VERSION ""

NS_ :

BS_:

BU_: SBZA_R_LS SBZA_L_LS VIS2_LS SDM_LS PEPS_LS UPA_LS PTM_LS MSM_LS HFP_LS EOCM_F_LS ECC_LS DCAC_LS CGM_LS BSM_LS BCM_LS AOS_LS

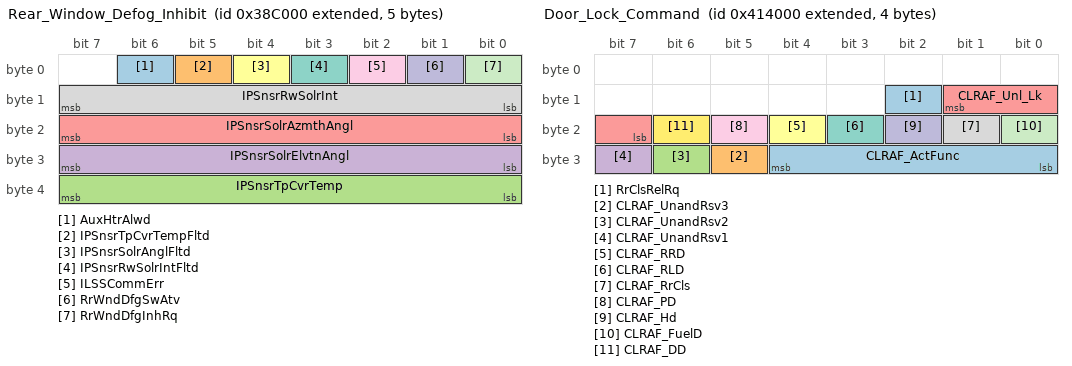
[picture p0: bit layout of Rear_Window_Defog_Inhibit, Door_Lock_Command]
BO_ 2151202816 Rear_Window_Defog_Inhibit: 5 BCM_LS
 SG_ AuxHtrAlwd : 6|1@0+ (1,0) [0|1] ""  ECC_LS,CGM_LS
 SG_ IPSnsrTpCvrTempFltd : 5|1@0+ (1,0) [0|1] ""  ECC_LS,CGM_LS
 SG_ IPSnsrTpCvrTemp : 39|8@0+ (0.5,-40) [-40|87.5] "deg C"  ECC_LS,CGM_LS
 SG_ IPSnsrSolrElvtnAngl : 31|8@0+ (1,0) [0|255] "deg"  ECC_LS,CGM_LS
 SG_ IPSnsrSolrAzmthAngl : 23|8@0+ (2,-180) [-180|330] "deg"  ECC_LS,CGM_LS
 SG_ IPSnsrSolrAnglFltd : 4|1@0+ (1,0) [0|1] ""  ECC_LS,CGM_LS
 SG_ IPSnsrRwSolrIntFltd : 3|1@0+ (1,0) [0|1] ""  ECC_LS,CGM_LS
 SG_ IPSnsrRwSolrInt : 15|8@0+ (3,0) [0|765] "W/m2"  ECC_LS,CGM_LS
 SG_ ILSSCommErr : 2|1@0+ (1,0) [0|1] ""  ECC_LS,CGM_LS
 SG_ RrWndDfgSwAtv : 1|1@0+ (1,0) [0|1] ""  ECC_LS,CGM_LS
 SG_ RrWndDfgInhRq : 0|1@0+ (1,0) [0|1] ""  ECC_LS,CGM_LS

BO_ 2151759872 Door_Lock_Command: 4 BCM_LS
 SG_ RrClsRelRq : 10|1@0+ (1,0) [0|1] ""  PTM_LS,PEPS_LS,CGM_LS
 SG_ CLRAF_UnandRsv3 : 29|1@0+ (1,0) [0|1] ""  PTM_LS,MSM_LS,CGM_LS
 SG_ CLRAF_UnandRsv2 : 30|1@0+ (1,0) [0|1] ""  PTM_LS,MSM_LS,CGM_LS
 SG_ CLRAF_UnandRsv1 : 31|1@0+ (1,0) [0|1] ""  PTM_LS,MSM_LS,CGM_LS
 SG_ CLRAF_Unl_Lk : 9|3@0+ (1,0) [0|7] ""  PTM_LS,MSM_LS,CGM_LS
 SG_ CLRAF_RRD : 20|1@0+ (1,0) [0|1] ""  PTM_LS,MSM_LS,CGM_LS
 SG_ CLRAF_RLD : 19|1@0+ (1,0) [0|1] ""  PTM_LS,MSM_LS,CGM_LS
 SG_ CLRAF_RrCls : 17|1@0+ (1,0) [0|1] ""  PTM_LS,MSM_LS,CGM_LS
 SG_ CLRAF_PD : 21|1@0+ (1,0) [0|1] ""  PTM_LS,MSM_LS,CGM_LS
 SG_ CLRAF_Hd : 18|1@0+ (1,0) [0|1] ""  PTM_LS,MSM_LS,CGM_LS
 SG_ CLRAF_FuelD : 16|1@0+ (1,0) [0|1] ""  PTM_LS,MSM_LS,CGM_LS
 SG_ CLRAF_DD : 22|1@0+ (1,0) [0|1] ""  PTM_LS,MSM_LS,CGM_LS
 SG_ CLRAF_ActFunc : 28|5@0+ (1,0) [0|31] ""  PTM_LS,MSM_LS,CGM_LS

BO_ 2149974016 Content_Theft_Sensor_Status: 3 BCM_LS
 SG_ IntrSnsDisbld : 1|1@0+ (1,0) [0|1] ""  CGM_LS
 SG_ AlrmStat : 18|3@0+ (1,0) [0|7] ""  PTM_LS,BSM_LS,CGM_LS
 SG_ AlrmTrggrdBattRcnctd : 11|1@0+ (1,0) [0|1] ""  CGM_LS
 SG_ AlrmTrgDrvDr : 3|1@0+ (1,0) [0|1] ""  CGM_LS
 SG_ AlrmTrgGlsBrkSns : 12|1@0+ (1,0) [0|1] ""  CGM_LS
 SG_ AlrmTrgHd : 21|1@0+ (1,0) [0|1] ""  CGM_LS
 SG_ AlrmTrgdIO : 15|1@0+ (1,0) [0|1] ""  CGM_LS
 SG_ AlrmTrgIntMvmntSns : 10|1@0+ (1,0) [0|1] ""  CGM_LS
 SG_ AlrmTrgNonOffPM : 13|1@0+ (1,0) [0|1] ""  CGM_LS
 SG_ AlrmTrgPsngDr : 4|1@0+ (1,0) [0|1] ""  CGM_LS
 SG_ AlrmTrgRrLftDr : 6|1@0+ (1,0) [0|1] ""  CGM_LS
 SG_ AlrmTrgRrRtDr : 5|1@0+ (1,0) [0|1] ""  CGM_LS
 SG_ AlrmTrgTltSns : 9|1@0+ (1,0) [0|1] ""  CGM_LS
 SG_ AlrmTrgTrnk : 8|1@0+ (1,0) [0|1] ""  CGM_LS
 SG_ SrvAlrmSysIO : 0|1@0+ (1,0) [0|1] ""  CGM_LS
 SG_ AlrmTrigMidClsr : 14|1@0+ (1,0) [0|1] ""  CGM_LS
 SG_ AlrmTrigTonn : 7|1@0+ (1,0) [0|1] ""  CGM_LS

BO_ 2151907328 Steering_Wheel_Control_Switches: 1 BCM_LS
 SG_ StrgWhlUnit1SwStat : 3|4@0+ (1,0) [0|15] ""  CGM_LS
 SG_ StrgWhlUnit2SwStat : 7|4@0+ (1,0) [0|15] ""  CGM_LS

BO_ 1345 UUDT_Resp_From_BCM_LS: 8 BCM_LS
 SG_ DgnInf_LS541 : 7|64@0+ (1,0) [0|1.84467440737096E+019] ""  CGM_LS

BO_ 1601 USDT_Resp_From_BCM_LS: 8 BCM_LS
 SG_ DgnInf : 7|64@0+ (1,0) [0|1.84467440737096E+019] ""  CGM_LS

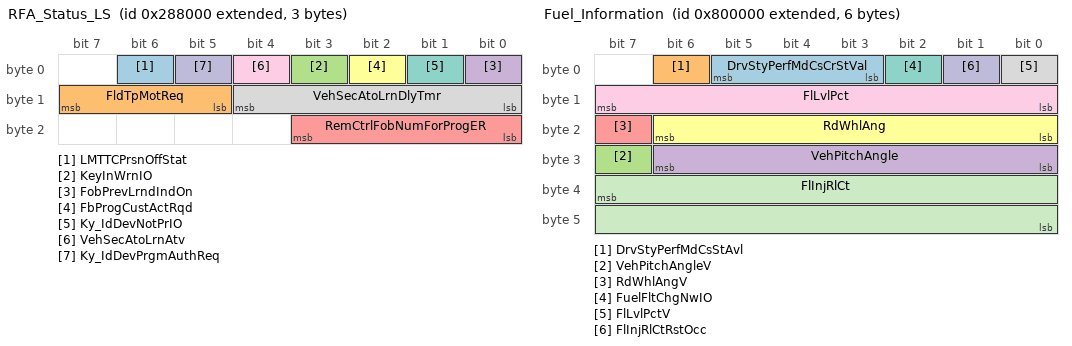
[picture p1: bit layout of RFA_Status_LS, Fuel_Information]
BO_ 2150137856 RFA_Status_LS: 3 BCM_LS
 SG_ LMTTCPrsnOffStat : 6|1@0+ (1,0) [0|1] ""  PEPS_LS,CGM_LS
 SG_ FldTpMotReq : 15|3@0+ (1,0) [0|7] ""  PEPS_LS,CGM_LS
 SG_ KeyInWrnIO : 3|1@0+ (1,0) [0|1] ""  CGM_LS
 SG_ FobPrevLrndIndOn : 0|1@0+ (1,0) [0|1] ""  CGM_LS
 SG_ RemCtrlFobNumForProgER : 19|4@0+ (1,0) [0|15] ""  PEPS_LS,CGM_LS
 SG_ FbProgCustActRqd : 2|1@0+ (1,0) [0|1] ""  CGM_LS
 SG_ Ky_IdDevNotPrIO : 1|1@0+ (1,0) [0|1] ""  CGM_LS
 SG_ VehSecAtoLrnDlyTmr : 12|5@0+ (1,0) [0|31] "min"  CGM_LS
 SG_ VehSecAtoLrnAtv : 4|1@0+ (1,0) [0|1] ""  CGM_LS
 SG_ Ky_IdDevPrgmAuthReq : 5|1@0+ (1,0) [0|1] ""  PEPS_LS,CGM_LS

BO_ 2155872256 Fuel_Information: 6 BCM_LS
 SG_ DrvStyPerfMdCsCrStVal : 5|3@0+ (1,0) [0|7] ""  CGM_LS
 SG_ DrvStyPerfMdCsStAvl : 6|1@0+ (1,0) [0|1] ""  CGM_LS
 SG_ VehPitchAngleV : 31|1@0+ (1,0) [0|1] ""  CGM_LS
 SG_ VehPitchAngle : 30|7@0+ (0.703125,-45) [-45|44.296875] "deg"  CGM_LS
 SG_ RdWhlAngV : 23|1@0+ (1,0) [0|1] ""  CGM_LS
 SG_ RdWhlAng : 22|7@0+ (0.703125,-45) [-45|44.296875] "deg"  CGM_LS
 SG_ FuelFltChgNwIO : 2|1@0+ (1,0) [0|1] ""  CGM_LS
 SG_ FlLvlPctV : 0|1@0+ (1,0) [0|1] ""  CGM_LS
 SG_ FlLvlPct : 15|8@0+ (0.392157,0) [0|100.000035] "%"  CGM_LS
 SG_ FlInjRlCtRstOcc : 1|1@0+ (1,0) [0|1] ""  CGM_LS
 SG_ FlInjRlCt : 39|16@0+ (3.05176E-005,0) [0|1.999970916] "liters"  CGM_LS

BO_ 2154561536 Vehicle_Odo_LS: 5 BCM_LS
 SG_ VehOdoV : 32|1@0+ (1,0) [0|1] ""  EOCM_F_LS,CGM_LS,BSM_LS
 SG_ VehOdo : 7|32@0+ (0.015625,0) [0|67108863.984375] "km"  EOCM_F_LS,ECC_LS,CGM_LS,BSM_LS

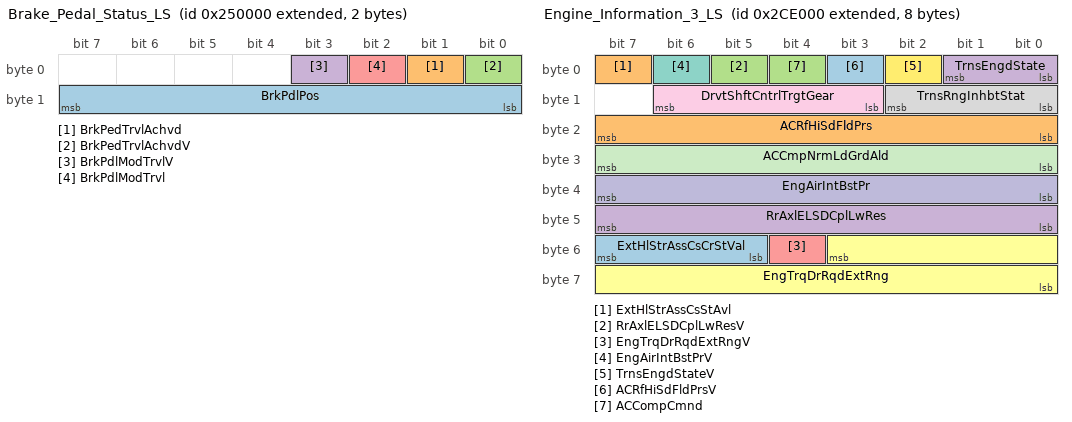
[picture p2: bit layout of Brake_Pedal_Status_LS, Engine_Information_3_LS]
BO_ 2149908480 Brake_Pedal_Status_LS: 2 BCM_LS
 SG_ BrkPdlPos : 15|8@0+ (0.392157,0) [0|100.000035] "% full"  VIS2_LS,CGM_LS
 SG_ BrkPedTrvlAchvd : 1|1@0+ (1,0) [0|1] ""  SDM_LS,VIS2_LS,CGM_LS
 SG_ BrkPedTrvlAchvdV : 0|1@0+ (1,0) [0|1] ""  SDM_LS,VIS2_LS,CGM_LS
 SG_ BrkPdlModTrvlV : 3|1@0+ (1,0) [0|1] ""  VIS2_LS,CGM_LS
 SG_ BrkPdlModTrvl : 2|1@0+ (1,0) [0|1] ""  VIS2_LS,CGM_LS

BO_ 2151268352 Column_Lock_Status: 1 BCM_LS
 SG_ ClmnLckTT : 1|2@0+ (1,0) [0|3] ""  CGM_LS

BO_ 2150424576 Engine_Information_3_LS: 8 BCM_LS
 SG_ ExtHlStrAssCsCrStVal : 55|3@0+ (1,0) [0|7] ""  CGM_LS
 SG_ ExtHlStrAssCsStAvl : 7|1@0+ (1,0) [0|1] ""  CGM_LS
 SG_ RrAxlELSDCplLwResV : 5|1@0+ (1,0) [0|1] ""  CGM_LS
 SG_ RrAxlELSDCplLwRes : 47|8@0+ (10,0) [0|2550] "Nm"  CGM_LS
 SG_ EngTrqDrRqdExtRngV : 52|1@0+ (1,0) [0|1] ""  CGM_LS
 SG_ EngTrqDrRqdExtRng : 51|12@0+ (0.5,-848) [-848|1199.5] "Nm"  CGM_LS
 SG_ EngAirIntBstPrV : 6|1@0+ (1,0) [0|1] ""  CGM_LS
 SG_ TrnsRngInhbtStat : 10|3@0+ (1,0) [0|7] ""  CGM_LS
 SG_ DrvtShftCntrlTrgtGear : 14|4@0+ (1,0) [0|15] ""  CGM_LS
 SG_ EngAirIntBstPr : 39|8@0- (1,0) [-128|127] "kPaG"  CGM_LS
 SG_ ACCmpNrmLdGrdAld : 31|8@0+ (0.1,0) [0|25.5] "dm3/m/s"  ECC_LS,CGM_LS
 SG_ TrnsEngdStateV : 2|1@0+ (1,0) [0|1] ""  SBZA_R_LS,VIS2_LS,SBZA_L_LS,CGM_LS
 SG_ ACRfHiSdFldPrsV : 3|1@0+ (1,0) [0|1] ""  ECC_LS,CGM_LS
 SG_ ACRfHiSdFldPrs : 23|8@0+ (14,0) [0|3570] "kPaG"  ECC_LS,CGM_LS
 SG_ ACCompCmnd : 4|1@0+ (1,0) [0|1] ""  ECC_LS,CGM_LS
 SG_ TrnsEngdState : 1|2@0+ (1,0) [0|3] ""  SBZA_R_LS,VIS2_LS,SBZA_L_LS,CGM_LS

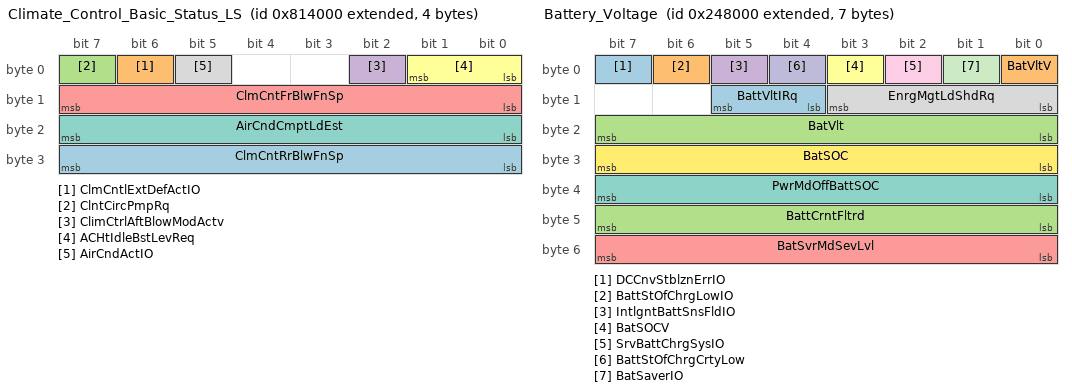
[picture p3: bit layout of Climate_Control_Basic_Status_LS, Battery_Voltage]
BO_ 2155954176 Climate_Control_Basic_Status_LS: 4 BCM_LS
 SG_ ClmCntRrBlwFnSp : 31|8@0+ (0.392157,0) [0|100.000035] "%"  CGM_LS,PTM_LS
 SG_ ClmCntlExtDefActIO : 6|1@0+ (1,0) [0|1] ""  CGM_LS
 SG_ ClntCircPmpRq : 7|1@0+ (1,0) [0|1] ""  CGM_LS,BCM_LS
 SG_ ClimCtrlAftBlowModActv : 2|1@0+ (1,0) [0|1] ""  CGM_LS,BCM_LS
 SG_ ClmCntFrBlwFnSp : 15|8@0+ (0.392157,0) [0|100.000035] "%"  CGM_LS,BSM_LS,BCM_LS,PTM_LS
 SG_ ACHtIdleBstLevReq : 1|2@0+ (1,0) [0|3] ""  CGM_LS,BCM_LS
 SG_ AirCndCmptLdEst : 23|8@0+ (0.392157,0) [0|100.000035] "%"  CGM_LS
 SG_ AirCndActIO : 5|1@0+ (1,0) [0|1] ""  CGM_LS

BO_ 2149875712 Battery_Voltage: 7 BCM_LS
 SG_ DCCnvStblznErrIO : 7|1@0+ (1,0) [0|1] ""  CGM_LS
 SG_ BattStOfChrgLowIO : 6|1@0+ (1,0) [0|1] ""  CGM_LS
 SG_ BattCrntFltrd : 47|8@0- (0.5,0) [-64|63.5] "A"  ECC_LS,CGM_LS
 SG_ IntlgntBattSnsFldIO : 5|1@0+ (1,0) [0|1] ""  CGM_LS
 SG_ BatSvrMdSevLvl : 55|8@0+ (1,0) [0|255] ""  CGM_LS
 SG_ BatSOCV : 3|1@0+ (1,0) [0|1] ""  DCAC_LS,ECC_LS,CGM_LS
 SG_ PwrMdOffBattSOC : 39|8@0+ (0.392157,0) [0|100.000035] "%"  CGM_LS
 SG_ EnrgMgtLdShdRq : 11|4@0+ (1,0) [0|15] ""  MSM_LS,DCAC_LS,ECC_LS,CGM_LS
 SG_ SrvBattChrgSysIO : 2|1@0+ (1,0) [0|1] ""  CGM_LS
 SG_ BattStOfChrgCrtyLow : 4|1@0+ (1,0) [0|1] ""  ECC_LS,CGM_LS
 SG_ BatSaverIO : 1|1@0+ (1,0) [0|1] ""  CGM_LS
 SG_ BatSOC : 31|8@0+ (0.392157,0) [0|100.000035] "%"  PEPS_LS,DCAC_LS,ECC_LS,CGM_LS
 SG_ BattVltIRq : 13|2@0+ (1,0) [0|3] ""  CGM_LS
 SG_ BatVltV : 0|1@0+ (1,0) [0|1] ""  SBZA_R_LS,MSM_LS,EOCM_F_LS,ECC_LS,CGM_LS,SBZA_L_LS
 SG_ BatVlt : 23|8@0+ (0.1,3) [3|28.5] "volts"  SBZA_R_LS,PEPS_LS,MSM_LS,EOCM_F_LS,ECC_LS,CGM_LS,SBZA_L_LS

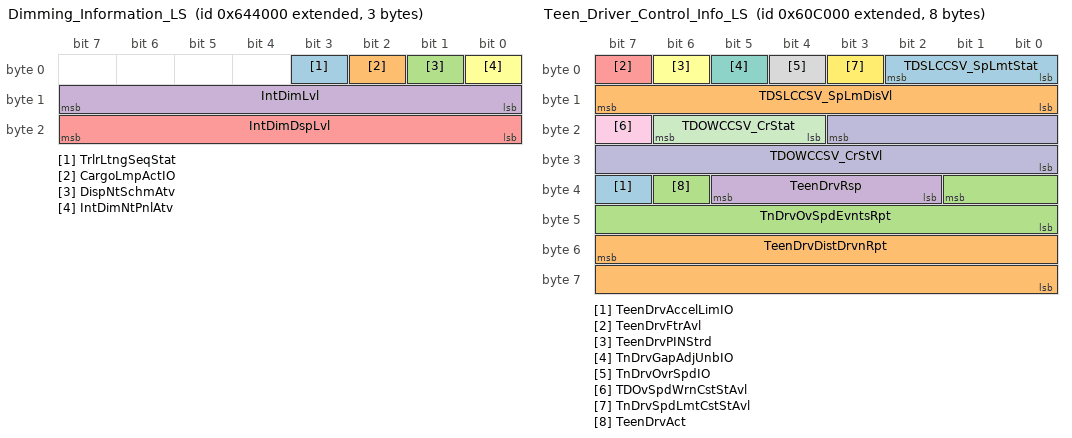
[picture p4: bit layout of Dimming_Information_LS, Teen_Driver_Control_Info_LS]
BO_ 2154053632 Dimming_Information_LS: 3 BCM_LS
 SG_ TrlrLtngSeqStat : 3|1@0+ (1,0) [0|1] ""  CGM_LS
 SG_ CargoLmpActIO : 2|1@0+ (1,0) [0|1] ""  CGM_LS
 SG_ DispNtSchmAtv : 1|1@0+ (1,0) [0|1] ""  SDM_LS,HFP_LS,ECC_LS,CGM_LS
 SG_ IntDimLvl : 15|8@0+ (0.392157,0) [0|100.000035] "%"  MSM_LS,ECC_LS,CGM_LS
 SG_ IntDimDspLvl : 23|8@0+ (0.392157,0) [0|100.000035] "%"  SDM_LS,ECC_LS,CGM_LS
 SG_ IntDimNtPnlAtv : 0|1@0+ (1,0) [0|1] ""  ECC_LS,CGM_LS

BO_ 2033 PCU_Req_to_SDM_LS: 8 BCM_LS
 SG_ PCUInfo : 7|64@0+ (1,0) [0|1.84467440737096E+019] ""  SDM_LS,CGM_LS

BO_ 2151530496 TPM_Display_Commands: 6 BCM_LS
 SG_ HVBTBDCSRR1_DChMHSRq : 45|6@0+ (1,0) [0|63] "min"  CGM_LS
 SG_ HVBTBDCSRR1_DChSnSRq : 47|2@0+ (1,0) [0|3] ""  CGM_LS
 SG_ HVBTBDCSRR1_DChSlSRq : 35|4@0+ (1,0) [0|15] ""  CGM_LS
 SG_ HVBTBDCSRR1_DChDStRq : 39|4@0+ (1,0) [0|15] ""  CGM_LS
 SG_ HVBTBDCSRR1_DChHStRq : 28|5@0+ (1,0) [0|31] "hr"  CGM_LS
 SG_ HVBatTmBsChgMdRqRmt1 : 31|3@0+ (1,0) [0|7] ""  CGM_LS
 SG_ HVChgSyChgLvPfStRmt1 : 18|3@0+ (1,0) [0|7] ""  CGM_LS
 SG_ StTODChrgTmpOvrdRmt1 : 20|2@0+ (1,0) [0|3] ""  CGM_LS
 SG_ PrtyChrgRqRmt1 : 22|2@0+ (1,0) [0|3] ""  CGM_LS
 SG_ OfBrdHVCVhCsChRqRmt1 : 23|1@0+ (1,0) [0|1] ""  CGM_LS
 SG_ TireTrdTmpStat : 6|3@0+ (1,0) [0|7] ""  CGM_LS
 SG_ TrPrsMntrTrLdStat : 3|2@0+ (1,0) [0|3] ""  CGM_LS
 SG_ TrPrsMntrAtLocFld : 1|1@0+ (1,0) [0|1] ""  CGM_LS
 SG_ TireLocatnWarnEn : 15|1@0+ (1,0) [0|1] ""  CGM_LS
 SG_ WintTrRecIndOn : 12|1@0+ (1,0) [0|1] ""  CGM_LS
 SG_ TrPrsMntrFld : 13|1@0+ (1,0) [0|1] ""  CGM_LS
 SG_ TrRrAxlPresStat : 11|2@0+ (1,0) [0|3] ""  CGM_LS
 SG_ TrFrntAxlPresStat : 9|2@0+ (1,0) [0|3] ""  CGM_LS
 SG_ TPMTrLrnMdCmplt : 0|1@0+ (1,0) [0|1] ""  CGM_LS

BO_ 2153824256 Teen_Driver_Control_Info_LS: 8 BCM_LS
 SG_ TeenDrvAccelLimIO : 39|1@0+ (1,0) [0|1] ""  CGM_LS
 SG_ TeenDrvDistDrvnRpt : 55|16@0+ (1,0) [0|65535] "km"  CGM_LS
 SG_ TnDrvOvSpdEvntsRpt : 33|10@0+ (1,0) [0|1023] "counts"  CGM_LS
 SG_ TeenDrvRsp : 37|4@0+ (1,0) [0|15] ""  CGM_LS
 SG_ TeenDrvFtrAvl : 7|1@0+ (1,0) [0|1] ""  CGM_LS
 SG_ TeenDrvPINStrd : 6|1@0+ (1,0) [0|1] ""  CGM_LS
 SG_ TnDrvGapAdjUnbIO : 5|1@0+ (1,0) [0|1] ""  CGM_LS
 SG_ TnDrvOvrSpdIO : 4|1@0+ (1,0) [0|1] ""  CGM_LS
 SG_ TDOvSpdWrnCstStAvl : 23|1@0+ (1,0) [0|1] ""  CGM_LS
 SG_ TDOWCCSV_CrStVl : 19|12@0+ (0.0625,0) [0|255.9375] "km/h"  CGM_LS
 SG_ TDOWCCSV_CrStat : 22|3@0+ (1,0) [0|7] ""  CGM_LS
 SG_ TnDrvSpdLmtCstStAvl : 3|1@0+ (1,0) [0|1] ""  CGM_LS
 SG_ TDSLCCSV_SpLmtStat : 2|3@0+ (1,0) [0|7] ""  CGM_LS
 SG_ TDSLCCSV_SpLmDisVl : 15|8@0+ (2,0) [0|510] "km/h"  CGM_LS
 SG_ TeenDrvAct : 38|1@0+ (1,0) [0|1] ""  SBZA_R_LS,SBZA_L_LS,UPA_LS,VIS2_LS,EOCM_F_LS,CGM_LS

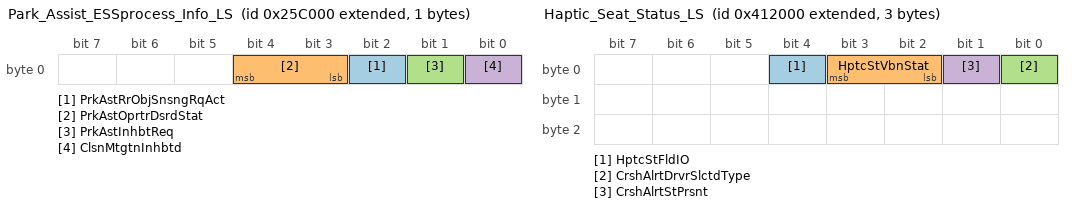
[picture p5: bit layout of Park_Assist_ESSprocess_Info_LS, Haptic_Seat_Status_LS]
BO_ 2149957632 Park_Assist_ESSprocess_Info_LS: 1 EOCM_F_LS
 SG_ PrkAstRrObjSnsngRqAct : 2|1@0+ (1,0) [0|1] ""  UPA_LS,CGM_LS
 SG_ PrkAstOprtrDsrdStat : 4|2@0+ (1,0) [0|3] ""  UPA_LS,CGM_LS
 SG_ PrkAstInhbtReq : 1|1@0+ (1,0) [0|1] ""  UPA_LS,CGM_LS
 SG_ ClsnMtgtnInhbtd : 0|1@0+ (1,0) [0|1] ""  UPA_LS,CGM_LS

BO_ 2151751680 Haptic_Seat_Status_LS: 3 MSM_LS
 SG_ HptcStFldIO : 4|1@0+ (1,0) [0|1] ""  VIS2_LS,CGM_LS
 SG_ HptcStVbnStat : 3|2@0+ (1,0) [0|3] ""  SBZA_R_LS,SBZA_L_LS,UPA_LS,VIS2_LS,EOCM_F_LS,CGM_LS,BCM_LS
 SG_ CrshAlrtDrvrSlctdType : 0|1@0+ (1,0) [0|1] ""  SBZA_R_LS,SBZA_L_LS,UPA_LS,VIS2_LS,EOCM_F_LS,CGM_LS,BCM_LS
 SG_ CrshAlrtStPrsnt : 1|1@0+ (1,0) [0|1] ""  SBZA_R_LS,SBZA_L_LS,UPA_LS,VIS2_LS,EOCM_F_LS,CGM_LS,BCM_LS

BO_ 2149990400 HS_Indications_Fast_LS: 8 BCM_LS
 SG_ ElcTransRngRq : 39|3@0+ (1,0) [0|7] ""  CGM_LS
 SG_ TrnsfrCsRngShfSpdLmt : 47|8@0+ (1,0) [0|255] "km / h"  CGM_LS
 SG_ TrlrBrkngVDA : 2|1@0+ (1,0) [0|1] ""  CGM_LS
 SG_ InstFuelConsmpRate : 51|12@0+ (0.025,0) [0|102.375] "ltrs/hr"  CGM_LS
 SG_ MotStBltUnblIO : 36|1@0+ (1,0) [0|1] ""  CGM_LS
 SG_ MotStBltFldIO : 35|1@0+ (1,0) [0|1] ""  CGM_LS
 SG_ TransNtrlCntrlMdStat : 34|2@0+ (1,0) [0|3] ""  CGM_LS
 SG_ TrlrWiringFltIO : 7|1@0+ (1,0) [0|1] ""  CGM_LS
 SG_ TrlrCnctdIO : 14|1@0+ (1,0) [0|1] ""  EOCM_F_LS,CGM_LS
 SG_ TrlrBrkngGainSetIO : 13|1@0+ (1,0) [0|1] ""  CGM_LS
 SG_ TrlrBrkngGainSet : 31|8@0+ (0.392157,0) [0|100.000035] "%"  CGM_LS
 SG_ TrlrBrkngFrcOtpt : 23|8@0+ (0.392157,0) [0|100.000035] "%"  CGM_LS
 SG_ SrvTrlrBrkngSysIO : 12|1@0+ (1,0) [0|1] ""  CGM_LS
 SG_ ChkTrlrIO : 15|1@0+ (1,0) [0|1] ""  CGM_LS
 SG_ ScndryAxleVDA : 11|1@0+ (1,0) [0|1] ""  CGM_LS
 SG_ TrlrHtchSwAtv_ITBC : 32|1@0+ (1,0) [0|1] ""  CGM_LS
 SG_ AdvHlmpsVDA : 9|1@0+ (1,0) [0|1] ""  CGM_LS
 SG_ ABSIO : 0|1@0+ (1,0) [0|1] ""  SDM_LS,CGM_LS
 SG_ ACCHdwayStngIO : 5|1@0+ (1,0) [0|1] ""  CGM_LS
 SG_ StpOnBrkToRelPBIndOn : 1|1@0+ (1,0) [0|1] ""  CGM_LS
 SG_ SADmpVDA : 10|1@0+ (1,0) [0|1] ""  CGM_LS
 SG_ ACCDrvrSeltdSpdIO : 6|1@0+ (1,0) [0|1] ""  CGM_LS
 SG_ TreInfMonSysRstPrfmd : 4|1@0+ (1,0) [0|1] ""  CGM_LS
 SG_ DrvThrtlOvrdIO : 3|1@0+ (1,0) [0|1] ""  CGM_LS
 SG_ SecAxlOperMod : 55|4@0+ (1,0) [0|15] ""  UPA_LS,CGM_LS

BO_ 2155380736 HS_Indications_SuperSlow_LS: 6 BCM_LS
 SG_ ACCmCltEngd : 41|1@0+ (1,0) [0|1] ""  ECC_LS,CGM_LS
 SG_ StrAsstRdcdLvl3IO : 23|1@0+ (1,0) [0|1] ""  CGM_LS
 SG_ StrAsstRdcdLvl2IO : 16|1@0+ (1,0) [0|1] ""  CGM_LS
 SG_ StrngAsstRdcdIO : 22|1@0+ (1,0) [0|1] ""  CGM_LS
 SG_ PwrPkFnSpd : 39|8@0+ (0.392157,0) [0|100.000035] "%"  PTM_LS,ECC_LS,CGM_LS
 SG_ PwrPckAirInTempFlt : 31|8@0+ (1,-40) [-40|215] "deg C"  ECC_LS,CGM_LS
 SG_ PTExPrtclFltrWrn2IO : 18|1@0+ (1,0) [0|1] ""  CGM_LS
 SG_ EngOilHotIO : 5|1@0+ (1,0) [0|1] ""  CGM_LS
 SG_ RrLevVDA : 3|1@0+ (1,0) [0|1] ""  CGM_LS
 SG_ EngWtrInFlIO : 12|1@0+ (1,0) [0|1] ""  CGM_LS
 SG_ AdvFrntLghtSysIndRq : 21|3@0+ (1,0) [0|7] ""  EOCM_F_LS,CGM_LS
 SG_ PTExPrtclFltrWrnIO : 6|1@0+ (1,0) [0|1] ""  CGM_LS
 SG_ AirCndOffIO : 4|1@0+ (1,0) [0|1] ""  CGM_LS
 SG_ HdLtLvlFlrIO : 2|1@0+ (1,0) [0|1] ""  CGM_LS
 SG_ PwrStrIO : 17|1@0+ (1,0) [0|1] ""  CGM_LS
 SG_ EngHt_StpEngIO : 15|1@0+ (1,0) [0|1] ""  CGM_LS
 SG_ CkFlFilrCapIO : 14|1@0+ (1,0) [0|1] ""  CGM_LS
 SG_ RdcdPwrIO : 13|1@0+ (1,0) [0|1] ""  SDM_LS,CGM_LS
 SG_ EngOilPrsLwIO : 11|1@0+ (1,0) [0|1] ""  CGM_LS
 SG_ EngOilLvlLwIO : 10|1@0+ (1,0) [0|1] ""  CGM_LS
 SG_ EngOilChngIO : 9|1@0+ (1,0) [0|1] ""  CGM_LS
 SG_ EngHotFuelEnrchmntIO : 8|1@0+ (1,0) [0|1] ""  CGM_LS
 SG_ DslGlwPlgIO : 7|1@0+ (1,0) [0|1] ""  CGM_LS
 SG_ SrvLevSysIO : 1|1@0+ (1,0) [0|1] ""  CGM_LS
 SG_ VehOvrLdIndOn : 0|1@0+ (1,0) [0|1] ""  CGM_LS
 SG_ ARSFlrIO : 40|1@0+ (1,0) [0|1] ""  CGM_LS

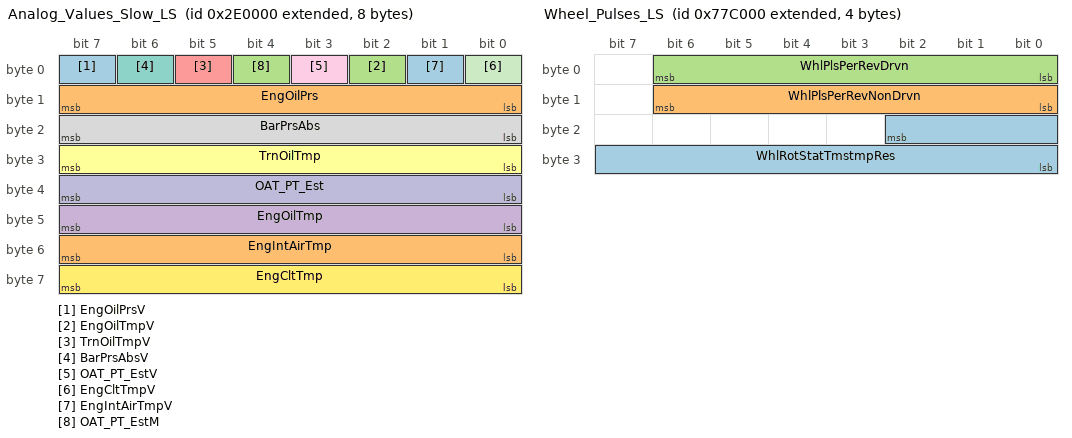
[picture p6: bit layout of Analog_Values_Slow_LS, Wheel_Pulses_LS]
BO_ 2150498304 Analog_Values_Slow_LS: 8 BCM_LS
 SG_ EngOilPrsV : 7|1@0+ (1,0) [0|1] ""  CGM_LS
 SG_ EngOilPrs : 15|8@0+ (4,0) [0|1020] "kPa"  CGM_LS
 SG_ EngOilTmpV : 2|1@0+ (1,0) [0|1] ""  CGM_LS
 SG_ EngOilTmp : 47|8@0+ (1,-40) [-40|215] "deg C"  CGM_LS
 SG_ TrnOilTmpV : 5|1@0+ (1,0) [0|1] ""  ECC_LS,CGM_LS
 SG_ TrnOilTmp : 31|8@0+ (1,-40) [-40|215] "deg C"  ECC_LS,CGM_LS
 SG_ BarPrsAbsV : 6|1@0+ (1,0) [0|1] ""  CGM_LS
 SG_ BarPrsAbs : 23|8@0+ (0.5,0) [0|127.5] "kPa"  CGM_LS
 SG_ OAT_PT_EstV : 3|1@0+ (1,0) [0|1] ""  PTM_LS,ECC_LS,CGM_LS
 SG_ OAT_PT_Est : 39|8@0+ (0.5,-40) [-40|87.5] "deg C"  PTM_LS,ECC_LS,CGM_LS
 SG_ EngCltTmpV : 0|1@0+ (1,0) [0|1] ""  ECC_LS,CGM_LS
 SG_ EngCltTmp : 63|8@0+ (1,-40) [-40|215] "deg C"  ECC_LS,CGM_LS
 SG_ EngIntAirTmpV : 1|1@0+ (1,0) [0|1] ""  ECC_LS,CGM_LS
 SG_ EngIntAirTmp : 55|8@0+ (1,-40) [-40|215] "deg C"  ECC_LS,CGM_LS
 SG_ OAT_PT_EstM : 4|1@0+ (1,0) [0|1] ""  PTM_LS,ECC_LS,CGM_LS

BO_ 2155331584 Wheel_Pulses_LS: 4 BCM_LS
 SG_ WhlRotStatTmstmpRes : 18|11@0+ (0.002,0) [0|4.094] "uSec"  SDM_LS,CGM_LS
 SG_ WhlPlsPerRevNonDrvn : 14|7@0+ (1,0) [0|127] ""  UPA_LS,SDM_LS,CGM_LS
 SG_ WhlPlsPerRevDrvn : 6|7@0+ (1,0) [0|127] ""  UPA_LS,SDM_LS,CGM_LS

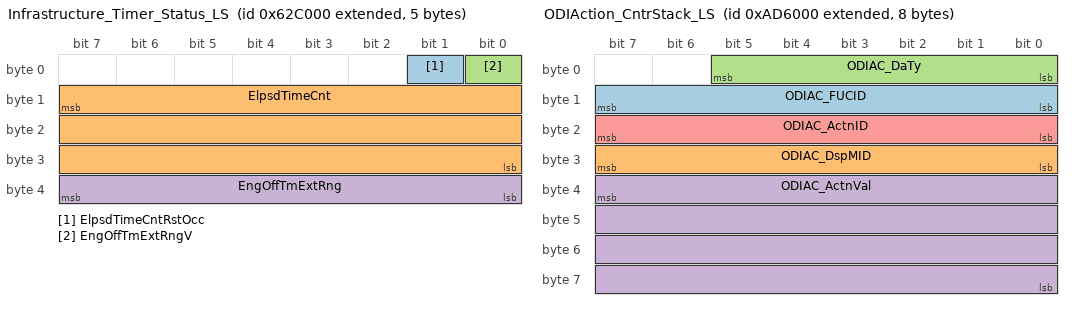
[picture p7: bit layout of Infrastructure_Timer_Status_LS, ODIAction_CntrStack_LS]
BO_ 2153955328 Infrastructure_Timer_Status_LS: 5 BCM_LS
 SG_ ElpsdTimeCntRstOcc : 1|1@0+ (1,0) [0|1] ""  CGM_LS
 SG_ ElpsdTimeCnt : 15|24@0+ (1,0) [0|16777215] "min"  CGM_LS
 SG_ EngOffTmExtRngV : 0|1@0+ (1,0) [0|1] ""  ECC_LS,CGM_LS
 SG_ EngOffTmExtRng : 39|8@0+ (4,0) [0|1020] "min"  ECC_LS,CGM_LS

BO_ 2158845952 ODIAction_CntrStack_LS: 8 CGM_LS
 SG_ ODIAC_FUCID : 15|8@0+ (1,0) [0|255] ""  SBZA_L_LS,UPA_LS,VIS2_LS,MSM_LS,EOCM_F_LS,ECC_LS,BCM_LS
 SG_ ODIAC_DspMID : 31|8@0+ (1,0) [0|255] ""  SBZA_L_LS,UPA_LS,VIS2_LS,MSM_LS,EOCM_F_LS,ECC_LS,BCM_LS
 SG_ ODIAC_DaTy : 5|6@0+ (1,0) [0|63] ""  SBZA_L_LS,UPA_LS,VIS2_LS,MSM_LS,EOCM_F_LS,ECC_LS,BCM_LS
 SG_ ODIAC_ActnVal : 39|32@0+ (1,0) [0|4294967295] ""  SBZA_L_LS,UPA_LS,VIS2_LS,MSM_LS,EOCM_F_LS,ECC_LS,BCM_LS
 SG_ ODIAC_ActnID : 23|8@0+ (1,0) [0|255] ""  SBZA_L_LS,UPA_LS,VIS2_LS,MSM_LS,EOCM_F_LS,ECC_LS,BCM_LS

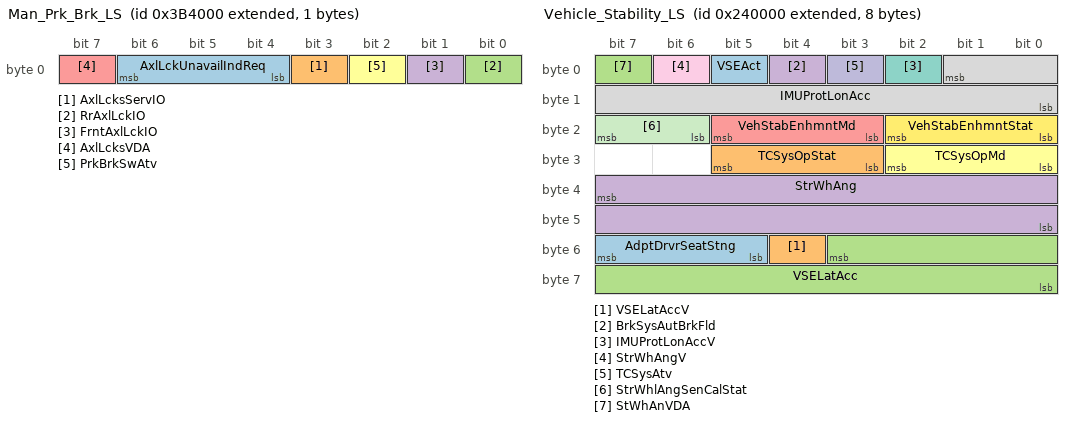
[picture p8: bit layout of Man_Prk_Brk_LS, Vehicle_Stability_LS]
BO_ 2151366656 Man_Prk_Brk_LS: 1 BCM_LS
 SG_ AxlLckUnavailIndReq : 6|3@0+ (1,0) [0|7] ""  CGM_LS
 SG_ AxlLcksServIO : 3|1@0+ (1,0) [0|1] ""  CGM_LS
 SG_ RrAxlLckIO : 0|1@0+ (1,0) [0|1] ""  CGM_LS
 SG_ FrntAxlLckIO : 1|1@0+ (1,0) [0|1] ""  CGM_LS
 SG_ AxlLcksVDA : 7|1@0+ (1,0) [0|1] ""  CGM_LS
 SG_ PrkBrkSwAtv : 2|1@0+ (1,0) [0|1] ""  SBZA_R_LS,SBZA_L_LS,UPA_LS,MSM_LS,CGM_LS

BO_ 2149842944 Vehicle_Stability_LS: 8 BCM_LS
 SG_ AdptDrvrSeatStng : 55|3@0+ (1,0) [0|7] ""  MSM_LS,CGM_LS
 SG_ VSELatAccV : 52|1@0+ (1,0) [0|1] ""  VIS2_LS,CGM_LS
 SG_ VSELatAcc : 51|12@0- (0.015625,0) [-32|31.984375] "m/s^2"  VIS2_LS,CGM_LS
 SG_ BrkSysAutBrkFld : 4|1@0+ (1,0) [0|1] ""  CGM_LS
 SG_ VehStabEnhmntMd : 21|3@0+ (1,0) [0|7] ""  CGM_LS
 SG_ TCSysOpMd : 26|3@0+ (1,0) [0|7] ""  CGM_LS
 SG_ IMUProtLonAccV : 2|1@0+ (1,0) [0|1] ""  UPA_LS,PTM_LS,VIS2_LS,CGM_LS
 SG_ IMUProtLonAcc : 1|10@0- (0.03,0) [-15.36|15.33] "m/s^2"  UPA_LS,PTM_LS,VIS2_LS,CGM_LS
 SG_ StrWhAngV : 6|1@0+ (1,0) [0|1] ""  SBZA_R_LS,SBZA_L_LS,UPA_LS,VIS2_LS,CGM_LS
 SG_ TCSysAtv : 3|1@0+ (1,0) [0|1] ""  VIS2_LS,CGM_LS
 SG_ StrWhlAngSenCalStat : 23|2@0+ (1,0) [0|3] ""  UPA_LS,VIS2_LS,CGM_LS
 SG_ VehStabEnhmntStat : 18|3@0+ (1,0) [0|7] ""  CGM_LS
 SG_ VSEAct : 5|1@0+ (1,0) [0|1] ""  VIS2_LS,EOCM_F_LS,CGM_LS
 SG_ TCSysOpStat : 29|3@0+ (1,0) [0|7] ""  CGM_LS
 SG_ StWhAnVDA : 7|1@0+ (1,0) [0|1] ""  UPA_LS,VIS2_LS,CGM_LS
 SG_ StrWhAng : 39|16@0- (0.0625,0) [-2048|2047.9375] "deg"  SBZA_R_LS,SBZA_L_LS,UPA_LS,VIS2_LS,CGM_LS

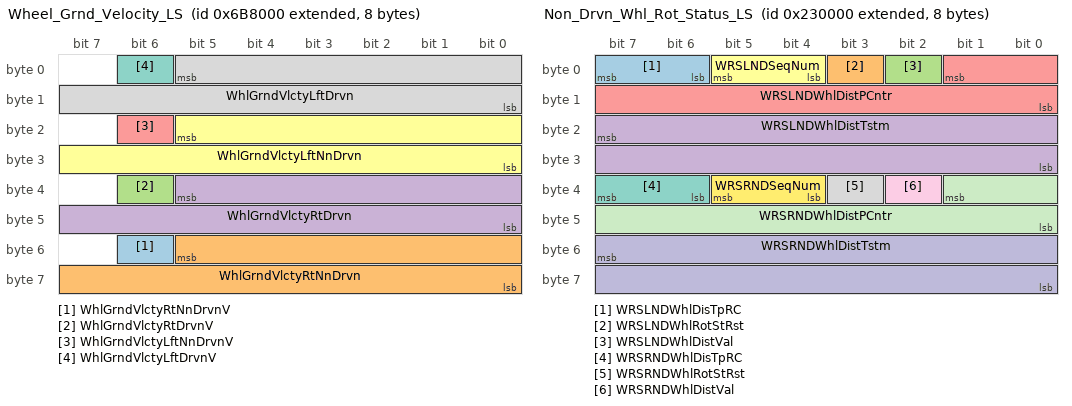
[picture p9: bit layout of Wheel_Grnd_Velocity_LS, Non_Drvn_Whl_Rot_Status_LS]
BO_ 2154528768 Wheel_Grnd_Velocity_LS: 8 BCM_LS
 SG_ WhlGrndVlctyRtNnDrvnV : 54|1@0+ (1,0) [0|1] ""  UPA_LS,SDM_LS,CGM_LS
 SG_ WhlGrndVlctyRtNnDrvn : 53|14@0+ (0.03125,0) [0|511.96875] "km / h"  UPA_LS,SDM_LS,CGM_LS
 SG_ WhlGrndVlctyRtDrvnV : 38|1@0+ (1,0) [0|1] ""  UPA_LS,SDM_LS,CGM_LS
 SG_ WhlGrndVlctyRtDrvn : 37|14@0+ (0.03125,0) [0|511.96875] "km / h"  UPA_LS,SDM_LS,CGM_LS
 SG_ WhlGrndVlctyLftNnDrvnV : 22|1@0+ (1,0) [0|1] ""  UPA_LS,SDM_LS,CGM_LS
 SG_ WhlGrndVlctyLftNnDrvn : 21|14@0+ (0.03125,0) [0|511.96875] "km / h"  UPA_LS,SDM_LS,CGM_LS
 SG_ WhlGrndVlctyLftDrvnV : 6|1@0+ (1,0) [0|1] ""  UPA_LS,SDM_LS,CGM_LS
 SG_ WhlGrndVlctyLftDrvn : 5|14@0+ (0.03125,0) [0|511.96875] "km / h"  UPA_LS,SDM_LS,CGM_LS

BO_ 2149777408 Non_Drvn_Whl_Rot_Status_LS: 8 BCM_LS
 SG_ WRSLNDWhlDisTpRC : 7|2@0+ (1,0) [0|3] "counts"  UPA_LS,CGM_LS
 SG_ WRSLNDWhlRotStRst : 3|1@0+ (1,0) [0|1] ""  UPA_LS,CGM_LS
 SG_ WRSLNDWhlDistVal : 2|1@0+ (1,0) [0|1] ""  UPA_LS,CGM_LS
 SG_ WRSLNDWhlDistTstm : 23|16@0+ (1,0) [0|65535] "counts"  UPA_LS,CGM_LS
 SG_ WRSLNDWhlDistPCntr : 1|10@0+ (1,0) [0|1023] "counts"  UPA_LS,CGM_LS
 SG_ WRSLNDSeqNum : 5|2@0+ (1,0) [0|3] "counts"  UPA_LS,CGM_LS
 SG_ WRSRNDWhlDisTpRC : 39|2@0+ (1,0) [0|3] "counts"  UPA_LS,CGM_LS
 SG_ WRSRNDWhlRotStRst : 35|1@0+ (1,0) [0|1] ""  UPA_LS,CGM_LS
 SG_ WRSRNDWhlDistVal : 34|1@0+ (1,0) [0|1] ""  UPA_LS,CGM_LS
 SG_ WRSRNDWhlDistTstm : 55|16@0+ (1,0) [0|65535] "counts"  UPA_LS,CGM_LS
 SG_ WRSRNDWhlDistPCntr : 33|10@0+ (1,0) [0|1023] "counts"  UPA_LS,CGM_LS
 SG_ WRSRNDSeqNum : 37|2@0+ (1,0) [0|3] "counts"  UPA_LS,CGM_LS

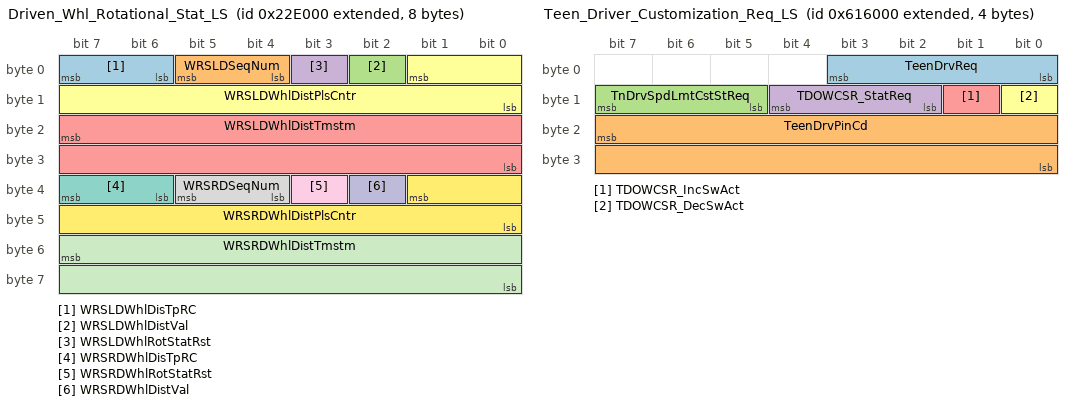
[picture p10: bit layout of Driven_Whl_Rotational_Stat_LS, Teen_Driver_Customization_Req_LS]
BO_ 2149769216 Driven_Whl_Rotational_Stat_LS: 8 BCM_LS
 SG_ WRSLDWhlDisTpRC : 7|2@0+ (1,0) [0|3] "counts"  UPA_LS,CGM_LS
 SG_ WRSLDSeqNum : 5|2@0+ (1,0) [0|3] "counts"  UPA_LS,CGM_LS
 SG_ WRSLDWhlDistVal : 2|1@0+ (1,0) [0|1] ""  UPA_LS,CGM_LS
 SG_ WRSLDWhlRotStatRst : 3|1@0+ (1,0) [0|1] ""  UPA_LS,CGM_LS
 SG_ WRSLDWhlDistTmstm : 23|16@0+ (1,0) [0|65535] "counts"  UPA_LS,CGM_LS
 SG_ WRSLDWhlDistPlsCntr : 1|10@0+ (1,0) [0|1023] "counts"  UPA_LS,CGM_LS
 SG_ WRSRDWhlDisTpRC : 39|2@0+ (1,0) [0|3] "counts"  UPA_LS,CGM_LS
 SG_ WRSRDSeqNum : 37|2@0+ (1,0) [0|3] "counts"  UPA_LS,CGM_LS
 SG_ WRSRDWhlRotStatRst : 35|1@0+ (1,0) [0|1] ""  UPA_LS,CGM_LS
 SG_ WRSRDWhlDistVal : 34|1@0+ (1,0) [0|1] ""  UPA_LS,CGM_LS
 SG_ WRSRDWhlDistTmstm : 55|16@0+ (1,0) [0|65535] "counts"  UPA_LS,CGM_LS
 SG_ WRSRDWhlDistPlsCntr : 33|10@0+ (1,0) [0|1023] "counts"  UPA_LS,CGM_LS

BO_ 2149752832 Chassis_Information_LS: 8 BCM_LS
 SG_ SndEnhcmtPerfMdRq : 55|3@0+ (1,0) [0|7] ""  CGM_LS
 SG_ SndPerfMdCsStAvl : 63|1@0+ (1,0) [0|1] ""  CGM_LS
 SG_ SndPerfMdCsCrStVal : 62|3@0+ (1,0) [0|7] ""  CGM_LS
 SG_ DispPerfMdCsStAvl : 59|1@0+ (1,0) [0|1] ""  CGM_LS
 SG_ DispPerfMdCsCrStVal : 58|3@0+ (1,0) [0|7] ""  CGM_LS
 SG_ HlStrAssActIO : 41|1@0+ (1,0) [0|1] ""  CGM_LS
 SG_ GNCustSetngAvlbl : 44|1@0+ (1,0) [0|1] ""  CGM_LS
 SG_ GNCustCrntStngVal : 47|3@0+ (1,0) [0|7] ""  CGM_LS
 SG_ CPSInfotmntMtReq : 49|2@0+ (1,0) [0|3] ""  CGM_LS
 SG_ ColPrSysStngAvl : 42|1@0+ (1,0) [0|1] ""  CGM_LS
 SG_ ColPrSysCrntStng : 52|3@0+ (1,0) [0|7] ""  CGM_LS
 SG_ HillDscntCntlSysStat : 37|3@0+ (1,0) [0|7] ""  CGM_LS
 SG_ EBDFailed : 31|1@0+ (1,0) [0|1] ""  CGM_LS
 SG_ SusCustStngAvlbl : 30|1@0+ (1,0) [0|1] ""  CGM_LS
 SG_ SusCustCurrStngVal : 34|3@0+ (1,0) [0|7] ""  CGM_LS
 SG_ StrCustStngAvlbl : 7|1@0+ (1,0) [0|1] ""  CGM_LS
 SG_ StrCustCurrStngVal : 29|3@0+ (1,0) [0|7] ""  CGM_LS
 SG_ DrvlnCustStngAvlbl : 6|1@0+ (1,0) [0|1] ""  CGM_LS
 SG_ DrvlnCustCurrStngVal : 26|3@0+ (1,0) [0|7] ""  CGM_LS
 SG_ PowStVDA : 13|1@0+ (1,0) [0|1] ""  CGM_LS
 SG_ RrDrCntVDA : 14|1@0+ (1,0) [0|1] ""  CGM_LS
 SG_ VehHghtStatV : 0|1@0+ (1,0) [0|1] ""  CGM_LS
 SG_ VehHghtStat : 11|4@0+ (1,0) [0|15] ""  CGM_LS
 SG_ IntBrkAssPreFilReq : 1|1@0+ (1,0) [0|1] "N/A"  CGM_LS
 SG_ EPBSysDspMsgReq : 23|3@0+ (1,0) [0|7] ""  CGM_LS
 SG_ EPBSysAudWarnReq : 20|2@0+ (1,0) [0|3] ""  CGM_LS
 SG_ BksOvht : 2|1@0+ (1,0) [0|1] ""  CGM_LS
 SG_ BrkSysRedBrkTlltlReq : 4|1@0+ (1,0) [0|1] ""  CGM_LS
 SG_ HalfSysFail : 3|1@0+ (1,0) [0|1] ""  CGM_LS
 SG_ ElecPrkBrkStat : 39|2@0+ (1,0) [0|3] ""  SBZA_R_LS,SBZA_L_LS,UPA_LS,MSM_LS,CGM_LS
 SG_ ABSAtv : 5|1@0+ (1,0) [0|1] ""  UPA_LS,VIS2_LS,SDM_LS,CGM_LS
 SG_ SprTireSt : 18|3@0+ (1,0) [0|7] ""  UPA_LS,CGM_LS
 SG_ BrkSysVDA : 15|1@0+ (1,0) [0|1] ""  UPA_LS,PTM_LS,VIS2_LS,CGM_LS
 SG_ PrkBrkVDA : 12|1@0+ (1,0) [0|1] ""  UPA_LS,CGM_LS

BO_ 2152775680 Front_360_Camera_On_LS: 4 CGM_LS
 SG_ RPDCA_Resrv3Avail : 17|1@0+ (1,0) [0|1] "" Vector__XXX
 SG_ RPDCA_Resrv2Avail : 18|1@0+ (1,0) [0|1] "" Vector__XXX
 SG_ RPDCA_Resrv1Avail : 19|1@0+ (1,0) [0|1] "" Vector__XXX
 SG_ RPDCA_AlrtBrkAvail : 20|1@0+ (1,0) [0|1] "" Vector__XXX
 SG_ RPDCA_AlrtAvail : 21|1@0+ (1,0) [0|1] "" Vector__XXX
 SG_ RPDCA_OnAvail : 22|1@0+ (1,0) [0|1] "" Vector__XXX
 SG_ RPDCA_OfAvail : 23|1@0+ (1,0) [0|1] "" Vector__XXX
 SG_ DispTrgdVidOn : 14|1@0+ (1,0) [0|1] "" Vector__XXX
 SG_ a_360DegVidFetrPrsnt : 15|1@0+ (1,0) [0|1] "" Vector__XXX
 SG_ TrgdVidRecFetrPrsnt : 7|1@0+ (1,0) [0|1] "" Vector__XXX
 SG_ RrPdDetHptcStVbRq : 13|6@0+ (1,0) [0|63] "Pulse"  MSM_LS
 SG_ RrPdDetHptcStVbRqSeqN : 6|2@0+ (1,0) [0|3] ""  MSM_LS
 SG_ RrPedDetCstStVal : 4|3@0+ (1,0) [0|7] "" Vector__XXX
 SG_ RrPedDetCstStAvl : 1|1@0+ (1,0) [0|1] "" Vector__XXX
 SG_ SurdVwLightgCsCurrSetVal : 26|3@0+ (1,0) [0|7] "" Vector__XXX
 SG_ DispSmrtTwVidOn : 16|1@0+ (1,0) [0|1] "" Vector__XXX
 SG_ DispFrt360CamOn : 0|1@0+ (1,0) [0|1] "" Vector__XXX
 SG_ SurdVwLightgCsSetAvail : 27|1@0+ (1,0) [0|1] "" Vector__XXX
 SG_ PudlLmpReqstd : 28|1@0+ (1,0) [0|1] ""  BCM_LS

BO_ 2153865216 Teen_Driver_Customization_Req_LS: 4 CGM_LS
 SG_ TeenDrvReq : 3|4@0+ (1,0) [0|15] ""  BCM_LS
 SG_ TeenDrvPinCd : 23|16@0+ (1,0) [0|39321] ""  BCM_LS
 SG_ TnDrvSpdLmtCstStReq : 15|3@0+ (1,0) [0|7] ""  BCM_LS
 SG_ TDOWCSR_StatReq : 12|3@0+ (1,0) [0|7] ""  BCM_LS
 SG_ TDOWCSR_IncSwAct : 9|1@0+ (1,0) [0|1] ""  BCM_LS
 SG_ TDOWCSR_DecSwAct : 8|1@0+ (1,0) [0|1] ""  BCM_LS

BO_ 2150391808 HMI_Hourmeter_Data_LS: 6 CGM_LS
 SG_ EngRunAtvTm : 31|24@0+ (1,0) [0|16777215] "min"  BCM_LS
 SG_ EngIdlAtvTm : 7|24@0+ (1,0) [0|16777215] "min"  BCM_LS

BO_ 2155970560 HVAC_PowerManager_Status_LS: 1 ECC_LS
 SG_ ClmCntBatSaverIO : 5|1@0+ (1,0) [0|1] ""  CGM_LS
 SG_ ClmCntLdShdLvlRq : 3|4@0+ (1,0) [0|15] ""  MSM_LS,CGM_LS,BCM_LS

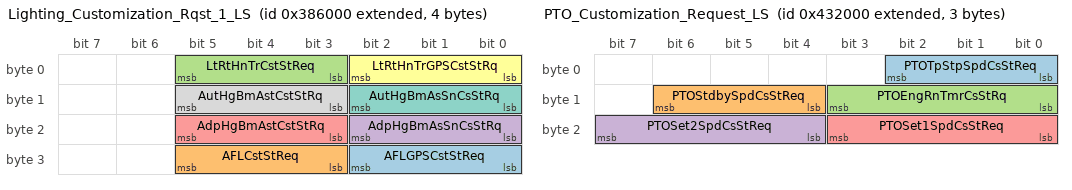
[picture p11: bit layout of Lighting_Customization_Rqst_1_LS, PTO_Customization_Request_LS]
BO_ 2151178240 Lighting_Customization_Rqst_1_LS: 4 CGM_LS
 SG_ AFLGPSCstStReq : 26|3@0+ (1,0) [0|7] ""  VIS2_LS,BCM_LS
 SG_ AFLCstStReq : 29|3@0+ (1,0) [0|7] ""  VIS2_LS,BCM_LS
 SG_ LtRtHnTrCstStReq : 5|3@0+ (1,0) [0|7] ""  BCM_LS
 SG_ AdpHgBmAsSnCsStRq : 18|3@0+ (1,0) [0|7] ""  VIS2_LS,BCM_LS
 SG_ AdpHgBmAstCstStRq : 21|3@0+ (1,0) [0|7] ""  VIS2_LS,BCM_LS
 SG_ LtRtHnTrGPSCstStRq : 2|3@0+ (1,0) [0|7] ""  BCM_LS
 SG_ AutHgBmAsSnCsStRq : 10|3@0+ (1,0) [0|7] ""  VIS2_LS,EOCM_F_LS,BCM_LS
 SG_ AutHgBmAstCstStRq : 13|3@0+ (1,0) [0|7] ""  VIS2_LS,EOCM_F_LS,BCM_LS

BO_ 2151882752 PTO_Customization_Request_LS: 3 CGM_LS
 SG_ PTOTpStpSpdCsStReq : 2|3@0+ (1,0) [0|7] ""  BCM_LS
 SG_ PTOStdbySpdCsStReq : 14|3@0+ (1,0) [0|7] ""  BCM_LS
 SG_ PTOEngRnTmrCsStRq : 11|4@0+ (1,0) [0|15] ""  BCM_LS
 SG_ PTOSet2SpdCsStReq : 23|4@0+ (1,0) [0|15] ""  BCM_LS
 SG_ PTOSet1SpdCsStReq : 19|4@0+ (1,0) [0|15] ""  BCM_LS

BO_TX_BU_ 2151907328 : CGM_LS,BCM_LS;
BO_TX_BU_ 2155954176 : ECC_LS,BCM_LS;
CM_ SG_ 2149908480 BrkPdlModTrvlV "Indicates that the brake pedal position has passed a threshold for brake torque management and some 2 channel Vehicle Dynamics Control systems.";
CM_ SG_ 2149908480 BrkPdlModTrvl "Indicates that the brake pedal position has passed a threshold for brake torque management and some 2 channel Vehicle Dynamics Control systems.";
CM_ SG_ 2150424576 ACCmpNrmLdGrdAld "dm3/m/s = dm3/minute/second";
CM_ SG_ 2151530496 TrRrAxlPresStat "Not required for C100 DIC";
CM_ SG_ 2151530496 TrFrntAxlPresStat "Not required for C100 DIC";
CM_ SG_ 2158845952 ODIAC_FUCID "ODI - Primary ID of Functional Unit in FU Database";
CM_ SG_ 2158845952 ODIAC_DspMID "ODI - ID that identifies the display requesting the data.  See detailed requirements in ODI GMLAN Protocol.";
CM_ SG_ 2158845952 ODIAC_ActnVal "ODI-Integer value for Actions with values.
FUDatabase definition of Action includes ActionDataType that defines whether or not Action has a value. 
For Actions without a value, this field is always sent as 0.";
CM_ SG_ 2158845952 ODIAC_ActnID "ODI-ActionId within the FUClass";
CM_ SG_ 2149842944 BrkSysAutBrkFld "BrakeSystemAutomaticBrakingFailed";
CM_ SG_ 2149752832 IntBrkAssPreFilReq "IntelligentBrakeAssistPreFillRequest";
BA_DEF_ SG_  "VNSigDiagnostic" ENUM  "No","Yes","DLCLS","DLCHS","DLCCE","DLCFO";
BA_DEF_ SG_  "VNSigUnused_4" ENUM  "No","Yes","DLCLS","DLCHS","DLCCE","DLCFO";
BA_DEF_ SG_  "VNSigIntermediate" ENUM  "No","Yes","DLCLS","DLCHS","DLCCE","DLCFO";
BA_DEF_ SG_  "VNSigParkedVehicle" ENUM  "No","Yes","DLCLS","DLCHS","DLCCE","DLCFO";
BA_DEF_ SG_  "VNSigRemoteDiagnostics" ENUM  "No","Yes","DLCLS","DLCHS","DLCCE","DLCFO";
BA_DEF_ SG_  "GenSigSendOnInit" ENUM  "Not Initialized","Application","Handler","DLCLS","DLCHS","DLCCE","DLCFO";
BA_DEF_ SG_  "GenSigSendType" ENUM  "not used","not used","not used","not used","not used","not used","not used","NoSigSendType","not used","not used","OnAnyChange","OnChangeIfActive","OnDelta","DLCLS","DLCHS","DLCCE","DLCFO";
BA_DEF_ SG_  "GenSigInactiveValue" INT 0 0;
BA_DEF_ SG_  "GenSigDeltaValue" INT 0 0;
BA_DEF_ SG_  "VNSigAllNodes" ENUM  "No","Yes","DLCLS","DLCHS","DLCCE","DLCFO";
BA_DEF_ SG_  "SignalType" STRING ;
BA_DEF_ SG_  "PacketOrder" INT 0 65535;
BA_DEF_ SG_  "SignalLongName" STRING ;
BA_DEF_ SG_  "GenSigStartValue" INT 0 65535;
BA_DEF_ SG_  "TxSignalSendOnInit" ENUM  "Not Initialized","Application","Handler";
BA_DEF_ BO_  "GenMsgILSupport" ENUM  "No","Yes","DLCLS","DLCHS","DLCCE","DLCFO";
BA_DEF_ BO_  "TpApplType" STRING ;
BA_DEF_ BO_  "Prio" INT 0 7;
BA_DEF_ BO_  "MessageSubnet" ENUM  "LS","MS","HS","CE","PE","HV","FO","S1","HE","LE","HE2","DLCLS","DLCHS","DLCCE","DLCFO","vector_leerstring";
BA_DEF_ BO_  "DiagState" ENUM  "No","Yes";
BA_DEF_ BO_  "GenMsgIlSupport" ENUM  "No","Yes";
BA_DEF_ BO_  "GenMsgStartDelayTime" INT 0 100000;
BA_DEF_ BO_  "GenMsgDelayTime" INT 0 100000;
BA_DEF_ BO_  "GenMsgCycleTime" INT 0 100000;
BA_DEF_ BO_  "GenMsgSendType" ENUM  "cyclicX","spontanX","cyclicIfActiveX","spontanWithDelay","cyclicAndSpontanX","cyclicAndSpontanWithDelay","spontanWithRepitition","cyclicIfActiveAndSpontanWD";
BA_DEF_ BO_  "DiagResponse" ENUM  "No","Yes";
BA_DEF_ BO_  "DiagRequest" ENUM  "No","Yes";
BA_DEF_ BO_  "NmMessage" ENUM  "No","Yes";
BA_DEF_REL_ BU_SG_REL_  "GenSigSuprvResp" ENUM  "None","Notify App","Substitute Default","DLCLS","DLCHS","DLCCE","DLCFO";
BA_DEF_REL_ BU_SG_REL_  "GenSigSuprvRespSubValue" INT 0 65535;
BA_DEF_REL_ BU_SG_REL_  "GenSigRxStartValue" STRING ;
BA_DEF_REL_ BU_SG_REL_  "GenSigVDAFailResp" ENUM  "No","Yes","DLCLS","DLCHS","DLCCE","DLCFO";
BA_DEF_REL_ BU_SG_REL_  "GenSigVDAFailComment" STRING ;
BA_DEF_REL_ BU_SG_REL_  "GenSigVBitRespComment" STRING ;
BA_DEF_REL_ BU_SG_REL_  "GenSigVBitResp" ENUM  "No","Yes","DLCLS","DLCHS","DLCCE","DLCFO";
BA_DEF_REL_ BU_SG_REL_  "GenSigSuprvRespComment" STRING ;
BA_DEF_REL_ BU_SG_REL_  "GenSigTimeoutTime" INT 0 5000;
BA_DEF_DEF_  "VNSigDiagnostic" "No";
BA_DEF_DEF_  "VNSigUnused_4" "No";
BA_DEF_DEF_  "VNSigIntermediate" "No";
BA_DEF_DEF_  "VNSigParkedVehicle" "No";
BA_DEF_DEF_  "VNSigRemoteDiagnostics" "No";
BA_DEF_DEF_  "GenSigSendOnInit" "Not Initialized";
BA_DEF_DEF_  "GenSigSendType" "NoSigSendType";
BA_DEF_DEF_  "GenSigInactiveValue" 0;
BA_DEF_DEF_  "GenSigDeltaValue" 0;
BA_DEF_DEF_  "VNSigAllNodes" "No";
BA_DEF_DEF_  "SignalType" "";
BA_DEF_DEF_  "PacketOrder" 0;
BA_DEF_DEF_  "SignalLongName" "";
BA_DEF_DEF_  "GenSigStartValue" 0;
BA_DEF_DEF_  "TxSignalSendOnInit" "Not Initialized";
BA_DEF_DEF_  "GenMsgILSupport" "Yes";
BA_DEF_DEF_  "TpApplType" "";
BA_DEF_DEF_  "Prio" 0;
BA_DEF_DEF_  "MessageSubnet" "LS";
BA_DEF_DEF_  "DiagState" "No";
BA_DEF_DEF_  "GenMsgIlSupport" "Yes";
BA_DEF_DEF_  "GenMsgStartDelayTime" 0;
BA_DEF_DEF_  "GenMsgDelayTime" 0;
BA_DEF_DEF_  "GenMsgCycleTime" 0;
BA_DEF_DEF_  "GenMsgSendType" "spontanX";
BA_DEF_DEF_  "DiagResponse" "No";
BA_DEF_DEF_  "DiagRequest" "No";
BA_DEF_DEF_  "NmMessage" "No";
BA_DEF_DEF_REL_ "GenSigSuprvResp" "None";
BA_DEF_DEF_REL_ "GenSigSuprvRespSubValue" 0;
BA_DEF_DEF_REL_ "GenSigRxStartValue" "";
BA_DEF_DEF_REL_ "GenSigVDAFailResp" "No";
BA_DEF_DEF_REL_ "GenSigVDAFailComment" "";
BA_DEF_DEF_REL_ "GenSigVBitRespComment" "";
BA_DEF_DEF_REL_ "GenSigVBitResp" "No";
BA_DEF_DEF_REL_ "GenSigSuprvRespComment" "";
BA_DEF_DEF_REL_ "GenSigTimeoutTime" 0;
BA_ "Prio" BO_ 2151202816 4;
BA_ "GenMsgDelayTime" BO_ 2151202816 100;
BA_ "Prio" BO_ 2151759872 3;
BA_ "GenMsgDelayTime" BO_ 2151759872 100;
BA_ "Prio" BO_ 2149974016 4;
BA_ "GenMsgDelayTime" BO_ 2149974016 100;
BA_ "Prio" BO_ 2151907328 4;
BA_ "GenMsgDelayTime" BO_ 2151907328 100;
BA_ "GenMsgILSupport" BO_ 1345 0;
BA_ "TpApplType" BO_ 1345 "DiagUUDTResponse";
BA_ "DiagResponse" BO_ 1601 1;
BA_ "Prio" BO_ 2150137856 4;
BA_ "GenMsgDelayTime" BO_ 2150137856 100;
BA_ "Prio" BO_ 2155872256 3;
BA_ "GenMsgStartDelayTime" BO_ 2155872256 190;
BA_ "GenMsgCycleTime" BO_ 2155872256 250;
BA_ "GenMsgSendType" BO_ 2155872256 0;
BA_ "Prio" BO_ 2154561536 4;
BA_ "GenMsgStartDelayTime" BO_ 2154561536 170;
BA_ "GenMsgCycleTime" BO_ 2154561536 1000;
BA_ "GenMsgSendType" BO_ 2154561536 0;
BA_ "Prio" BO_ 2149908480 4;
BA_ "GenMsgStartDelayTime" BO_ 2149908480 130;
BA_ "GenMsgDelayTime" BO_ 2149908480 100;
BA_ "GenMsgCycleTime" BO_ 2149908480 1000;
BA_ "GenMsgSendType" BO_ 2149908480 0;
BA_ "Prio" BO_ 2151268352 4;
BA_ "GenMsgDelayTime" BO_ 2151268352 100;
BA_ "Prio" BO_ 2150424576 4;
BA_ "GenMsgStartDelayTime" BO_ 2150424576 150;
BA_ "GenMsgCycleTime" BO_ 2150424576 250;
BA_ "GenMsgSendType" BO_ 2150424576 0;
BA_ "Prio" BO_ 2155954176 4;
BA_ "GenMsgDelayTime" BO_ 2155954176 100;
BA_ "GenMsgCycleTime" BO_ 2155954176 2500;
BA_ "GenMsgSendType" BO_ 2155954176 0;
BA_ "Prio" BO_ 2149875712 4;
BA_ "GenMsgStartDelayTime" BO_ 2149875712 120;
BA_ "GenMsgCycleTime" BO_ 2149875712 500;
BA_ "GenMsgSendType" BO_ 2149875712 0;
BA_ "Prio" BO_ 2154053632 4;
BA_ "GenMsgDelayTime" BO_ 2154053632 100;
BA_ "Prio" BO_ 2151530496 4;
BA_ "GenMsgDelayTime" BO_ 2151530496 100;
BA_ "Prio" BO_ 2153824256 4;
BA_ "GenMsgDelayTime" BO_ 2153824256 100;
BA_ "Prio" BO_ 2149957632 4;
BA_ "GenMsgDelayTime" BO_ 2149957632 100;
BA_ "Prio" BO_ 2151751680 4;
BA_ "GenMsgDelayTime" BO_ 2151751680 100;
BA_ "Prio" BO_ 2149990400 4;
BA_ "GenMsgStartDelayTime" BO_ 2149990400 200;
BA_ "GenMsgCycleTime" BO_ 2149990400 100;
BA_ "GenMsgSendType" BO_ 2149990400 0;
BA_ "Prio" BO_ 2155380736 4;
BA_ "GenMsgStartDelayTime" BO_ 2155380736 180;
BA_ "GenMsgDelayTime" BO_ 2155380736 10;
BA_ "GenMsgCycleTime" BO_ 2155380736 500;
BA_ "GenMsgSendType" BO_ 2155380736 0;
BA_ "Prio" BO_ 2150498304 4;
BA_ "GenMsgStartDelayTime" BO_ 2150498304 140;
BA_ "GenMsgCycleTime" BO_ 2150498304 1000;
BA_ "GenMsgSendType" BO_ 2150498304 0;
BA_ "Prio" BO_ 2155331584 4;
BA_ "GenMsgStartDelayTime" BO_ 2155331584 160;
BA_ "GenMsgCycleTime" BO_ 2155331584 1000;
BA_ "GenMsgSendType" BO_ 2155331584 0;
BA_ "Prio" BO_ 2153955328 4;
BA_ "GenMsgDelayTime" BO_ 2153955328 100;
BA_ "Prio" BO_ 2158845952 4;
BA_ "GenMsgDelayTime" BO_ 2158845952 20;
BA_ "Prio" BO_ 2151366656 4;
BA_ "GenMsgDelayTime" BO_ 2151366656 100;
BA_ "Prio" BO_ 2149842944 4;
BA_ "GenMsgStartDelayTime" BO_ 2149842944 160;
BA_ "GenMsgCycleTime" BO_ 2149842944 100;
BA_ "GenMsgSendType" BO_ 2149842944 0;
BA_ "Prio" BO_ 2154528768 4;
BA_ "GenMsgStartDelayTime" BO_ 2154528768 160;
BA_ "GenMsgCycleTime" BO_ 2154528768 200;
BA_ "GenMsgSendType" BO_ 2154528768 0;
BA_ "Prio" BO_ 2149777408 4;
BA_ "GenMsgStartDelayTime" BO_ 2149777408 140;
BA_ "GenMsgCycleTime" BO_ 2149777408 200;
BA_ "GenMsgSendType" BO_ 2149777408 0;
BA_ "Prio" BO_ 2149769216 4;
BA_ "GenMsgStartDelayTime" BO_ 2149769216 130;
BA_ "GenMsgCycleTime" BO_ 2149769216 200;
BA_ "GenMsgSendType" BO_ 2149769216 0;
BA_ "Prio" BO_ 2149752832 4;
BA_ "GenMsgStartDelayTime" BO_ 2149752832 110;
BA_ "GenMsgCycleTime" BO_ 2149752832 250;
BA_ "GenMsgSendType" BO_ 2149752832 0;
BA_ "Prio" BO_ 2152775680 4;
BA_ "GenMsgDelayTime" BO_ 2152775680 100;
BA_ "Prio" BO_ 2153865216 4;
BA_ "GenMsgDelayTime" BO_ 2153865216 100;
BA_ "Prio" BO_ 2150391808 4;
BA_ "GenMsgDelayTime" BO_ 2150391808 100;
BA_ "Prio" BO_ 2155970560 4;
BA_ "GenMsgDelayTime" BO_ 2155970560 100;
BA_ "Prio" BO_ 2151178240 4;
BA_ "GenMsgDelayTime" BO_ 2151178240 100;
BA_ "Prio" BO_ 2151882752 4;
BA_ "GenMsgDelayTime" BO_ 2151882752 100;
BA_ "GenSigSendType" SG_ 2151202816 AuxHtrAlwd 10;
BA_ "VNSigAllNodes" SG_ 2151202816 AuxHtrAlwd 1;
BA_ "SignalType" SG_ 2151202816 AuxHtrAlwd "BLN";
BA_ "SignalLongName" SG_ 2151202816 AuxHtrAlwd "Auxiliary Heater Allowed";
BA_ "GenSigSendType" SG_ 2151202816 IPSnsrTpCvrTempFltd 10;
BA_ "VNSigAllNodes" SG_ 2151202816 IPSnsrTpCvrTempFltd 1;
BA_ "SignalType" SG_ 2151202816 IPSnsrTpCvrTempFltd "BLN";
BA_ "SignalLongName" SG_ 2151202816 IPSnsrTpCvrTempFltd "Instrument Panel Sensor Top Cover Temperature faulted";
BA_ "GenSigSendType" SG_ 2151202816 IPSnsrTpCvrTemp 12;
BA_ "GenSigDeltaValue" SG_ 2151202816 IPSnsrTpCvrTemp 1;
BA_ "VNSigAllNodes" SG_ 2151202816 IPSnsrTpCvrTemp 1;
BA_ "SignalType" SG_ 2151202816 IPSnsrTpCvrTemp "UNM";
BA_ "SignalLongName" SG_ 2151202816 IPSnsrTpCvrTemp "Instrument Panel Sensor Top Cover Temperature";
BA_ "GenSigSendType" SG_ 2151202816 IPSnsrSolrElvtnAngl 12;
BA_ "GenSigDeltaValue" SG_ 2151202816 IPSnsrSolrElvtnAngl 1;
BA_ "VNSigAllNodes" SG_ 2151202816 IPSnsrSolrElvtnAngl 1;
BA_ "SignalType" SG_ 2151202816 IPSnsrSolrElvtnAngl "UNM";
BA_ "SignalLongName" SG_ 2151202816 IPSnsrSolrElvtnAngl "Instrument Panel Sensor Solar Elevation Angle";
BA_ "GenSigSendType" SG_ 2151202816 IPSnsrSolrAzmthAngl 12;
BA_ "GenSigDeltaValue" SG_ 2151202816 IPSnsrSolrAzmthAngl 1;
BA_ "VNSigAllNodes" SG_ 2151202816 IPSnsrSolrAzmthAngl 1;
BA_ "SignalType" SG_ 2151202816 IPSnsrSolrAzmthAngl "UNM";
BA_ "SignalLongName" SG_ 2151202816 IPSnsrSolrAzmthAngl "Instrument Panel Sensor Solar Azimuth Angle";
BA_ "GenSigSendType" SG_ 2151202816 IPSnsrSolrAnglFltd 10;
BA_ "VNSigAllNodes" SG_ 2151202816 IPSnsrSolrAnglFltd 1;
BA_ "SignalType" SG_ 2151202816 IPSnsrSolrAnglFltd "BLN";
BA_ "SignalLongName" SG_ 2151202816 IPSnsrSolrAnglFltd "Instrument Panel Sensor Solar Angle Faulted";
BA_ "GenSigSendType" SG_ 2151202816 IPSnsrRwSolrIntFltd 10;
BA_ "VNSigAllNodes" SG_ 2151202816 IPSnsrRwSolrIntFltd 1;
BA_ "SignalType" SG_ 2151202816 IPSnsrRwSolrIntFltd "BLN";
BA_ "SignalLongName" SG_ 2151202816 IPSnsrRwSolrIntFltd "Instrument Panel Sensor Raw Solar Intensity Faulted";
BA_ "GenSigSendType" SG_ 2151202816 IPSnsrRwSolrInt 12;
BA_ "GenSigDeltaValue" SG_ 2151202816 IPSnsrRwSolrInt 1;
BA_ "VNSigAllNodes" SG_ 2151202816 IPSnsrRwSolrInt 1;
BA_ "SignalType" SG_ 2151202816 IPSnsrRwSolrInt "UNM";
BA_ "SignalLongName" SG_ 2151202816 IPSnsrRwSolrInt "Instrument Panel Sensor Raw Solar Intensity";
BA_ "GenSigSendType" SG_ 2151202816 ILSSCommErr 10;
BA_ "VNSigAllNodes" SG_ 2151202816 ILSSCommErr 1;
BA_ "SignalType" SG_ 2151202816 ILSSCommErr "ENM";
BA_ "SignalLongName" SG_ 2151202816 ILSSCommErr "ILSS Communication Error";
BA_ "GenSigSendType" SG_ 2151202816 RrWndDfgSwAtv 10;
BA_ "VNSigAllNodes" SG_ 2151202816 RrWndDfgSwAtv 1;
BA_ "SignalType" SG_ 2151202816 RrWndDfgSwAtv "BLN";
BA_ "SignalLongName" SG_ 2151202816 RrWndDfgSwAtv "Rear Window Defog Switch Active";
BA_ "GenSigSendOnInit" SG_ 2151202816 RrWndDfgInhRq 2;
BA_ "GenSigSendType" SG_ 2151202816 RrWndDfgInhRq 10;
BA_ "VNSigAllNodes" SG_ 2151202816 RrWndDfgInhRq 1;
BA_ "SignalType" SG_ 2151202816 RrWndDfgInhRq "ENM";
BA_ "SignalLongName" SG_ 2151202816 RrWndDfgInhRq "Rear Window Defog Inhibit Request";
BA_ "GenSigSendType" SG_ 2151759872 RrClsRelRq 10;
BA_ "VNSigAllNodes" SG_ 2151759872 RrClsRelRq 1;
BA_ "SignalType" SG_ 2151759872 RrClsRelRq "ENM";
BA_ "SignalLongName" SG_ 2151759872 RrClsRelRq "Rear Closure Release Request";
BA_ "GenSigSendType" SG_ 2151759872 CLRAF_UnandRsv3 10;
BA_ "VNSigAllNodes" SG_ 2151759872 CLRAF_UnandRsv3 1;
BA_ "SignalType" SG_ 2151759872 CLRAF_UnandRsv3 "BLN";
BA_ "PacketOrder" SG_ 2151759872 CLRAF_UnandRsv3 11;
BA_ "SignalLongName" SG_ 2151759872 CLRAF_UnandRsv3 "Central Locking Request with Extended Activating Functions : Unused and Reserved 3";
BA_ "GenSigSendType" SG_ 2151759872 CLRAF_UnandRsv2 10;
BA_ "VNSigAllNodes" SG_ 2151759872 CLRAF_UnandRsv2 1;
BA_ "SignalType" SG_ 2151759872 CLRAF_UnandRsv2 "BLN";
BA_ "PacketOrder" SG_ 2151759872 CLRAF_UnandRsv2 10;
BA_ "SignalLongName" SG_ 2151759872 CLRAF_UnandRsv2 "Central Locking Request with Extended Activating Functions : Unused and Reserved 2";
BA_ "GenSigSendType" SG_ 2151759872 CLRAF_UnandRsv1 10;
BA_ "VNSigAllNodes" SG_ 2151759872 CLRAF_UnandRsv1 1;
BA_ "SignalType" SG_ 2151759872 CLRAF_UnandRsv1 "BLN";
BA_ "PacketOrder" SG_ 2151759872 CLRAF_UnandRsv1 9;
BA_ "SignalLongName" SG_ 2151759872 CLRAF_UnandRsv1 "Central Locking Request with Extended Activating Functions : Unused and Reserved 1";
BA_ "GenSigSendType" SG_ 2151759872 CLRAF_Unl_Lk 10;
BA_ "VNSigAllNodes" SG_ 2151759872 CLRAF_Unl_Lk 1;
BA_ "SignalType" SG_ 2151759872 CLRAF_Unl_Lk "ENM";
BA_ "PacketOrder" SG_ 2151759872 CLRAF_Unl_Lk 1;
BA_ "SignalLongName" SG_ 2151759872 CLRAF_Unl_Lk "Central Locking Request with Extended Activating Functions : Unlock/Lock";
BA_ "GenSigSendType" SG_ 2151759872 CLRAF_RRD 10;
BA_ "VNSigAllNodes" SG_ 2151759872 CLRAF_RRD 1;
BA_ "SignalType" SG_ 2151759872 CLRAF_RRD "BLN";
BA_ "PacketOrder" SG_ 2151759872 CLRAF_RRD 4;
BA_ "SignalLongName" SG_ 2151759872 CLRAF_RRD "Central Locking Request with Extended Activating Functions : Rear Right Door";
BA_ "GenSigSendType" SG_ 2151759872 CLRAF_RLD 10;
BA_ "VNSigAllNodes" SG_ 2151759872 CLRAF_RLD 1;
BA_ "SignalType" SG_ 2151759872 CLRAF_RLD "BLN";
BA_ "PacketOrder" SG_ 2151759872 CLRAF_RLD 5;
BA_ "SignalLongName" SG_ 2151759872 CLRAF_RLD "Central Locking Request with Extended Activating Functions : Rear Left Door";
BA_ "GenSigSendType" SG_ 2151759872 CLRAF_RrCls 10;
BA_ "VNSigAllNodes" SG_ 2151759872 CLRAF_RrCls 1;
BA_ "SignalType" SG_ 2151759872 CLRAF_RrCls "BLN";
BA_ "PacketOrder" SG_ 2151759872 CLRAF_RrCls 7;
BA_ "SignalLongName" SG_ 2151759872 CLRAF_RrCls "Central Locking Request with Extended Activating Functions : Rear Closure";
BA_ "GenSigSendType" SG_ 2151759872 CLRAF_PD 10;
BA_ "VNSigAllNodes" SG_ 2151759872 CLRAF_PD 1;
BA_ "SignalType" SG_ 2151759872 CLRAF_PD "BLN";
BA_ "PacketOrder" SG_ 2151759872 CLRAF_PD 3;
BA_ "SignalLongName" SG_ 2151759872 CLRAF_PD "Central Locking Request with Extended Activating Functions : Passenger Door";
BA_ "GenSigSendType" SG_ 2151759872 CLRAF_Hd 10;
BA_ "VNSigAllNodes" SG_ 2151759872 CLRAF_Hd 1;
BA_ "SignalType" SG_ 2151759872 CLRAF_Hd "BLN";
BA_ "PacketOrder" SG_ 2151759872 CLRAF_Hd 6;
BA_ "SignalLongName" SG_ 2151759872 CLRAF_Hd "Central Locking Request with Extended Activating Functions : Hood";
BA_ "GenSigSendType" SG_ 2151759872 CLRAF_FuelD 10;
BA_ "VNSigAllNodes" SG_ 2151759872 CLRAF_FuelD 1;
BA_ "SignalType" SG_ 2151759872 CLRAF_FuelD "BLN";
BA_ "PacketOrder" SG_ 2151759872 CLRAF_FuelD 8;
BA_ "SignalLongName" SG_ 2151759872 CLRAF_FuelD "Central Locking Request with Extended Activating Functions : Fuel Door";
BA_ "GenSigSendType" SG_ 2151759872 CLRAF_DD 10;
BA_ "VNSigAllNodes" SG_ 2151759872 CLRAF_DD 1;
BA_ "SignalType" SG_ 2151759872 CLRAF_DD "BLN";
BA_ "PacketOrder" SG_ 2151759872 CLRAF_DD 2;
BA_ "SignalLongName" SG_ 2151759872 CLRAF_DD "Central Locking Request with Extended Activating Functions : Driver Door";
BA_ "GenSigSendType" SG_ 2151759872 CLRAF_ActFunc 10;
BA_ "VNSigAllNodes" SG_ 2151759872 CLRAF_ActFunc 1;
BA_ "SignalType" SG_ 2151759872 CLRAF_ActFunc "ENM";
BA_ "PacketOrder" SG_ 2151759872 CLRAF_ActFunc 12;
BA_ "SignalLongName" SG_ 2151759872 CLRAF_ActFunc "Central Locking Request with Extended Activating Functions : Activating Function";
BA_ "GenSigSendType" SG_ 2149974016 IntrSnsDisbld 10;
BA_ "VNSigAllNodes" SG_ 2149974016 IntrSnsDisbld 1;
BA_ "SignalType" SG_ 2149974016 IntrSnsDisbld "BLN";
BA_ "SignalLongName" SG_ 2149974016 IntrSnsDisbld "Intrusion Sensing Disabled";
BA_ "GenSigSendOnInit" SG_ 2149974016 AlrmStat 2;
BA_ "GenSigSendType" SG_ 2149974016 AlrmStat 10;
BA_ "VNSigAllNodes" SG_ 2149974016 AlrmStat 1;
BA_ "SignalType" SG_ 2149974016 AlrmStat "ENM";
BA_ "SignalLongName" SG_ 2149974016 AlrmStat "Alarm Status";
BA_ "GenSigSendType" SG_ 2149974016 AlrmTrggrdBattRcnctd 10;
BA_ "VNSigAllNodes" SG_ 2149974016 AlrmTrggrdBattRcnctd 1;
BA_ "SignalType" SG_ 2149974016 AlrmTrggrdBattRcnctd "BLN";
BA_ "SignalLongName" SG_ 2149974016 AlrmTrggrdBattRcnctd "Alarm Triggered Battery Reconnected";
BA_ "GenSigSendType" SG_ 2149974016 AlrmTrgDrvDr 10;
BA_ "VNSigAllNodes" SG_ 2149974016 AlrmTrgDrvDr 1;
BA_ "SignalType" SG_ 2149974016 AlrmTrgDrvDr "BLN";
BA_ "SignalLongName" SG_ 2149974016 AlrmTrgDrvDr "Alarm Triggered Driver Door Ajar";
BA_ "GenSigSendType" SG_ 2149974016 AlrmTrgGlsBrkSns 10;
BA_ "VNSigAllNodes" SG_ 2149974016 AlrmTrgGlsBrkSns 1;
BA_ "SignalType" SG_ 2149974016 AlrmTrgGlsBrkSns "BLN";
BA_ "SignalLongName" SG_ 2149974016 AlrmTrgGlsBrkSns "Alarm Triggered Glass Breakage Sensor";
BA_ "GenSigSendType" SG_ 2149974016 AlrmTrgHd 10;
BA_ "VNSigAllNodes" SG_ 2149974016 AlrmTrgHd 1;
BA_ "SignalType" SG_ 2149974016 AlrmTrgHd "BLN";
BA_ "SignalLongName" SG_ 2149974016 AlrmTrgHd "Alarm Triggered Hood Ajar";
BA_ "GenSigSendType" SG_ 2149974016 AlrmTrgdIO 10;
BA_ "VNSigAllNodes" SG_ 2149974016 AlrmTrgdIO 1;
BA_ "SignalType" SG_ 2149974016 AlrmTrgdIO "BLN";
BA_ "SignalLongName" SG_ 2149974016 AlrmTrgdIO "Alarm Triggered Indication On";
BA_ "GenSigSendType" SG_ 2149974016 AlrmTrgIntMvmntSns 10;
BA_ "VNSigAllNodes" SG_ 2149974016 AlrmTrgIntMvmntSns 1;
BA_ "SignalType" SG_ 2149974016 AlrmTrgIntMvmntSns "BLN";
BA_ "SignalLongName" SG_ 2149974016 AlrmTrgIntMvmntSns "Alarm Triggered Interior Movement Sensor";
BA_ "GenSigSendType" SG_ 2149974016 AlrmTrgNonOffPM 10;
BA_ "VNSigAllNodes" SG_ 2149974016 AlrmTrgNonOffPM 1;
BA_ "SignalType" SG_ 2149974016 AlrmTrgNonOffPM "BLN";
BA_ "SignalLongName" SG_ 2149974016 AlrmTrgNonOffPM "Alarm Triggered Non-Off Power Mode";
BA_ "GenSigSendType" SG_ 2149974016 AlrmTrgPsngDr 10;
BA_ "VNSigAllNodes" SG_ 2149974016 AlrmTrgPsngDr 1;
BA_ "SignalType" SG_ 2149974016 AlrmTrgPsngDr "BLN";
BA_ "SignalLongName" SG_ 2149974016 AlrmTrgPsngDr "Alarm Triggered Passenger Door Ajar";
BA_ "GenSigSendType" SG_ 2149974016 AlrmTrgRrLftDr 10;
BA_ "VNSigAllNodes" SG_ 2149974016 AlrmTrgRrLftDr 1;
BA_ "SignalType" SG_ 2149974016 AlrmTrgRrLftDr "BLN";
BA_ "SignalLongName" SG_ 2149974016 AlrmTrgRrLftDr "Alarm Triggered Rear Left Door Ajar";
BA_ "GenSigSendType" SG_ 2149974016 AlrmTrgRrRtDr 10;
BA_ "VNSigAllNodes" SG_ 2149974016 AlrmTrgRrRtDr 1;
BA_ "SignalType" SG_ 2149974016 AlrmTrgRrRtDr "BLN";
BA_ "SignalLongName" SG_ 2149974016 AlrmTrgRrRtDr "Alarm Triggered Rear Right Door Ajar";
BA_ "GenSigSendType" SG_ 2149974016 AlrmTrgTltSns 10;
BA_ "VNSigAllNodes" SG_ 2149974016 AlrmTrgTltSns 1;
BA_ "SignalType" SG_ 2149974016 AlrmTrgTltSns "BLN";
BA_ "SignalLongName" SG_ 2149974016 AlrmTrgTltSns "Alarm Triggered Tilt Sensor";
BA_ "GenSigSendType" SG_ 2149974016 AlrmTrgTrnk 10;
BA_ "VNSigAllNodes" SG_ 2149974016 AlrmTrgTrnk 1;
BA_ "SignalType" SG_ 2149974016 AlrmTrgTrnk "BLN";
BA_ "SignalLongName" SG_ 2149974016 AlrmTrgTrnk "Alarm Triggered Trunk Ajar";
BA_ "GenSigSendType" SG_ 2149974016 SrvAlrmSysIO 10;
BA_ "VNSigAllNodes" SG_ 2149974016 SrvAlrmSysIO 1;
BA_ "SignalType" SG_ 2149974016 SrvAlrmSysIO "BLN";
BA_ "SignalLongName" SG_ 2149974016 SrvAlrmSysIO "Service Alarm System Indication On";
BA_ "GenSigSendType" SG_ 2149974016 AlrmTrigMidClsr 10;
BA_ "VNSigAllNodes" SG_ 2149974016 AlrmTrigMidClsr 1;
BA_ "SignalType" SG_ 2149974016 AlrmTrigMidClsr "BLN";
BA_ "SignalLongName" SG_ 2149974016 AlrmTrigMidClsr "Alarm Triggered Mid Closure";
BA_ "GenSigSendType" SG_ 2149974016 AlrmTrigTonn 10;
BA_ "VNSigAllNodes" SG_ 2149974016 AlrmTrigTonn 1;
BA_ "SignalType" SG_ 2149974016 AlrmTrigTonn "BLN";
BA_ "SignalLongName" SG_ 2149974016 AlrmTrigTonn "Alarm Triggered Tonneau";
BA_ "GenSigSendType" SG_ 2151907328 StrgWhlUnit1SwStat 10;
BA_ "VNSigAllNodes" SG_ 2151907328 StrgWhlUnit1SwStat 1;
BA_ "SignalType" SG_ 2151907328 StrgWhlUnit1SwStat "ENM";
BA_ "SignalLongName" SG_ 2151907328 StrgWhlUnit1SwStat "Steering Wheel Unit #1 Switch Status";
BA_ "GenSigSendType" SG_ 2151907328 StrgWhlUnit2SwStat 10;
BA_ "VNSigAllNodes" SG_ 2151907328 StrgWhlUnit2SwStat 1;
BA_ "SignalType" SG_ 2151907328 StrgWhlUnit2SwStat "ENM";
BA_ "SignalLongName" SG_ 2151907328 StrgWhlUnit2SwStat "Steering Wheel Unit #2 Switch Status";
BA_ "VNSigDiagnostic" SG_ 1345 DgnInf_LS541 1;
BA_ "VNSigAllNodes" SG_ 1345 DgnInf_LS541 1;
BA_ "SignalType" SG_ 1345 DgnInf_LS541 "UNM";
BA_ "SignalLongName" SG_ 1345 DgnInf_LS541 "Diagnostic Information LS541";
BA_ "VNSigDiagnostic" SG_ 1601 DgnInf 1;
BA_ "GenSigSendType" SG_ 1601 DgnInf 12;
BA_ "GenSigDeltaValue" SG_ 1601 DgnInf 1;
BA_ "VNSigAllNodes" SG_ 1601 DgnInf 1;
BA_ "SignalType" SG_ 1601 DgnInf "UNM";
BA_ "SignalLongName" SG_ 1601 DgnInf "Diagnostic Information";
BA_ "GenSigSendType" SG_ 2150137856 LMTTCPrsnOffStat 10;
BA_ "VNSigAllNodes" SG_ 2150137856 LMTTCPrsnOffStat 1;
BA_ "SignalType" SG_ 2150137856 LMTTCPrsnOffStat "BLN";
BA_ "SignalLongName" SG_ 2150137856 LMTTCPrsnOffStat "Lead Me To The Car Personalization Off Status";
BA_ "GenSigSendType" SG_ 2150137856 FldTpMotReq 10;
BA_ "VNSigAllNodes" SG_ 2150137856 FldTpMotReq 1;
BA_ "SignalType" SG_ 2150137856 FldTpMotReq "ENM";
BA_ "SignalLongName" SG_ 2150137856 FldTpMotReq "Folding Top Motion Request";
BA_ "GenSigSendOnInit" SG_ 2150137856 KeyInWrnIO 2;
BA_ "GenSigSendType" SG_ 2150137856 KeyInWrnIO 10;
BA_ "VNSigAllNodes" SG_ 2150137856 KeyInWrnIO 1;
BA_ "SignalType" SG_ 2150137856 KeyInWrnIO "BLN";
BA_ "SignalLongName" SG_ 2150137856 KeyInWrnIO "Key In Warning Indication On";
BA_ "GenSigSendType" SG_ 2150137856 FobPrevLrndIndOn 10;
BA_ "VNSigAllNodes" SG_ 2150137856 FobPrevLrndIndOn 1;
BA_ "SignalType" SG_ 2150137856 FobPrevLrndIndOn "BLN";
BA_ "SignalLongName" SG_ 2150137856 FobPrevLrndIndOn "Fob Previously Learned Indication On";
BA_ "GenSigSendType" SG_ 2150137856 RemCtrlFobNumForProgER 10;
BA_ "VNSigAllNodes" SG_ 2150137856 RemCtrlFobNumForProgER 1;
BA_ "SignalType" SG_ 2150137856 RemCtrlFobNumForProgER "ENM";
BA_ "SignalLongName" SG_ 2150137856 RemCtrlFobNumForProgER "Remote Control Fob Number For Programming Extended Range";
BA_ "GenSigSendType" SG_ 2150137856 FbProgCustActRqd 10;
BA_ "VNSigAllNodes" SG_ 2150137856 FbProgCustActRqd 1;
BA_ "SignalType" SG_ 2150137856 FbProgCustActRqd "BLN";
BA_ "SignalLongName" SG_ 2150137856 FbProgCustActRqd "Fob Programming Customer Action Required";
BA_ "GenSigSendOnInit" SG_ 2150137856 Ky_IdDevNotPrIO 2;
BA_ "GenSigSendType" SG_ 2150137856 Ky_IdDevNotPrIO 10;
BA_ "VNSigAllNodes" SG_ 2150137856 Ky_IdDevNotPrIO 1;
BA_ "SignalType" SG_ 2150137856 Ky_IdDevNotPrIO "BLN";
BA_ "SignalLongName" SG_ 2150137856 Ky_IdDevNotPrIO "Key/Identification Device Not Present Indication On";
BA_ "GenSigSendType" SG_ 2150137856 VehSecAtoLrnDlyTmr 12;
BA_ "GenSigDeltaValue" SG_ 2150137856 VehSecAtoLrnDlyTmr 1;
BA_ "VNSigAllNodes" SG_ 2150137856 VehSecAtoLrnDlyTmr 1;
BA_ "SignalType" SG_ 2150137856 VehSecAtoLrnDlyTmr "UNM";
BA_ "SignalLongName" SG_ 2150137856 VehSecAtoLrnDlyTmr "Vehicle Security Auto Learn Delay Timer";
BA_ "GenSigSendType" SG_ 2150137856 VehSecAtoLrnAtv 10;
BA_ "VNSigAllNodes" SG_ 2150137856 VehSecAtoLrnAtv 1;
BA_ "SignalType" SG_ 2150137856 VehSecAtoLrnAtv "BLN";
BA_ "SignalLongName" SG_ 2150137856 VehSecAtoLrnAtv "Vehicle Security Auto Learn Active";
BA_ "GenSigSendType" SG_ 2150137856 Ky_IdDevPrgmAuthReq 10;
BA_ "VNSigAllNodes" SG_ 2150137856 Ky_IdDevPrgmAuthReq 1;
BA_ "SignalType" SG_ 2150137856 Ky_IdDevPrgmAuthReq "BLN";
BA_ "SignalLongName" SG_ 2150137856 Ky_IdDevPrgmAuthReq "Key / Identification Device Programming Authentication Requested";
BA_ "VNSigAllNodes" SG_ 2155872256 DrvStyPerfMdCsCrStVal 1;
BA_ "SignalType" SG_ 2155872256 DrvStyPerfMdCsCrStVal "ENM";
BA_ "SignalLongName" SG_ 2155872256 DrvStyPerfMdCsCrStVal "Driving Style Performance Mode Customization Current Setting Value";
BA_ "VNSigAllNodes" SG_ 2155872256 DrvStyPerfMdCsStAvl 1;
BA_ "SignalType" SG_ 2155872256 DrvStyPerfMdCsStAvl "BLN";
BA_ "SignalLongName" SG_ 2155872256 DrvStyPerfMdCsStAvl "Driving Style Performance Mode Customization Setting Available";
BA_ "VNSigAllNodes" SG_ 2155872256 VehPitchAngleV 1;
BA_ "SignalType" SG_ 2155872256 VehPitchAngleV "ENM";
BA_ "SignalLongName" SG_ 2155872256 VehPitchAngleV "Vehicle Pitch Angle Validity";
BA_ "VNSigAllNodes" SG_ 2155872256 VehPitchAngle 1;
BA_ "SignalType" SG_ 2155872256 VehPitchAngle "UNM";
BA_ "SignalLongName" SG_ 2155872256 VehPitchAngle "Vehicle Pitch Angle";
BA_ "VNSigAllNodes" SG_ 2155872256 RdWhlAngV 1;
BA_ "SignalType" SG_ 2155872256 RdWhlAngV "ENM";
BA_ "SignalLongName" SG_ 2155872256 RdWhlAngV "Road Wheel Angle Validity";
BA_ "VNSigAllNodes" SG_ 2155872256 RdWhlAng 1;
BA_ "SignalType" SG_ 2155872256 RdWhlAng "UNM";
BA_ "SignalLongName" SG_ 2155872256 RdWhlAng "Road Wheel Angle";
BA_ "VNSigAllNodes" SG_ 2155872256 FuelFltChgNwIO 1;
BA_ "SignalType" SG_ 2155872256 FuelFltChgNwIO "BLN";
BA_ "SignalLongName" SG_ 2155872256 FuelFltChgNwIO "Fuel Filter Change Now Indication On";
BA_ "GenSigSendOnInit" SG_ 2155872256 FlLvlPctV 1;
BA_ "VNSigAllNodes" SG_ 2155872256 FlLvlPctV 1;
BA_ "SignalType" SG_ 2155872256 FlLvlPctV "ENM";
BA_ "SignalLongName" SG_ 2155872256 FlLvlPctV "Fuel Level Percent Validity";
BA_ "GenSigSendOnInit" SG_ 2155872256 FlLvlPct 1;
BA_ "GenSigDeltaValue" SG_ 2155872256 FlLvlPct 2;
BA_ "VNSigAllNodes" SG_ 2155872256 FlLvlPct 1;
BA_ "SignalType" SG_ 2155872256 FlLvlPct "UNM";
BA_ "SignalLongName" SG_ 2155872256 FlLvlPct "Fuel Level Percent";
BA_ "VNSigAllNodes" SG_ 2155872256 FlInjRlCtRstOcc 1;
BA_ "SignalType" SG_ 2155872256 FlInjRlCtRstOcc "BLN";
BA_ "SignalLongName" SG_ 2155872256 FlInjRlCtRstOcc "Fuel Injected Rolling Count Reset Occurred";
BA_ "VNSigAllNodes" SG_ 2155872256 FlInjRlCt 1;
BA_ "SignalType" SG_ 2155872256 FlInjRlCt "UNM";
BA_ "SignalLongName" SG_ 2155872256 FlInjRlCt "Fuel Injected Rolling Count";
BA_ "VNSigAllNodes" SG_ 2154561536 VehOdoV 1;
BA_ "SignalType" SG_ 2154561536 VehOdoV "ENM";
BA_ "SignalLongName" SG_ 2154561536 VehOdoV "Vehicle Odometer Validity";
BA_ "VNSigAllNodes" SG_ 2154561536 VehOdo 1;
BA_ "SignalType" SG_ 2154561536 VehOdo "UNM";
BA_ "SignalLongName" SG_ 2154561536 VehOdo "Vehicle Odometer";
BA_ "GenSigSendOnInit" SG_ 2149908480 BrkPdlPos 1;
BA_ "GenSigSendType" SG_ 2149908480 BrkPdlPos 12;
BA_ "GenSigDeltaValue" SG_ 2149908480 BrkPdlPos 1;
BA_ "VNSigAllNodes" SG_ 2149908480 BrkPdlPos 1;
BA_ "SignalType" SG_ 2149908480 BrkPdlPos "UNM";
BA_ "SignalLongName" SG_ 2149908480 BrkPdlPos "Brake Pedal Position";
BA_ "GenSigSendType" SG_ 2149908480 BrkPedTrvlAchvd 10;
BA_ "VNSigAllNodes" SG_ 2149908480 BrkPedTrvlAchvd 1;
BA_ "SignalType" SG_ 2149908480 BrkPedTrvlAchvd "BLN";
BA_ "PacketOrder" SG_ 2149908480 BrkPedTrvlAchvd 1;
BA_ "SignalLongName" SG_ 2149908480 BrkPedTrvlAchvd "Brake Pedal Initial Travel Achieved Status : Brake Pedal Initial Travel Achieved";
BA_ "GenSigSendType" SG_ 2149908480 BrkPedTrvlAchvdV 10;
BA_ "VNSigAllNodes" SG_ 2149908480 BrkPedTrvlAchvdV 1;
BA_ "SignalType" SG_ 2149908480 BrkPedTrvlAchvdV "ENM";
BA_ "PacketOrder" SG_ 2149908480 BrkPedTrvlAchvdV 2;
BA_ "SignalLongName" SG_ 2149908480 BrkPedTrvlAchvdV "Brake Pedal Initial Travel Achieved Status : Brake Pedal Initial Travel Achieved Validity";
BA_ "GenSigSendType" SG_ 2149908480 BrkPdlModTrvlV 10;
BA_ "VNSigAllNodes" SG_ 2149908480 BrkPdlModTrvlV 1;
BA_ "SignalType" SG_ 2149908480 BrkPdlModTrvlV "ENM";
BA_ "SignalLongName" SG_ 2149908480 BrkPdlModTrvlV "Brake Pedal Moderate Travel Achieved Validity";
BA_ "GenSigSendType" SG_ 2149908480 BrkPdlModTrvl 10;
BA_ "VNSigAllNodes" SG_ 2149908480 BrkPdlModTrvl 1;
BA_ "SignalType" SG_ 2149908480 BrkPdlModTrvl "BLN";
BA_ "SignalLongName" SG_ 2149908480 BrkPdlModTrvl "Brake Pedal Moderate Travel Achieved";
BA_ "GenSigSendOnInit" SG_ 2151268352 ClmnLckTT 1;
BA_ "GenSigSendType" SG_ 2151268352 ClmnLckTT 10;
BA_ "VNSigAllNodes" SG_ 2151268352 ClmnLckTT 1;
BA_ "SignalType" SG_ 2151268352 ClmnLckTT "ENM";
BA_ "SignalLongName" SG_ 2151268352 ClmnLckTT "Column Lock Telltale";
BA_ "VNSigAllNodes" SG_ 2150424576 ExtHlStrAssCsCrStVal 1;
BA_ "SignalType" SG_ 2150424576 ExtHlStrAssCsCrStVal "ENM";
BA_ "SignalLongName" SG_ 2150424576 ExtHlStrAssCsCrStVal "Extended Hill Start Assist Customization Current Setting Value";
BA_ "VNSigAllNodes" SG_ 2150424576 ExtHlStrAssCsStAvl 1;
BA_ "SignalType" SG_ 2150424576 ExtHlStrAssCsStAvl "BLN";
BA_ "SignalLongName" SG_ 2150424576 ExtHlStrAssCsStAvl "Extended Hill Start Assist Customization Setting Available";
BA_ "VNSigAllNodes" SG_ 2150424576 RrAxlELSDCplLwResV 1;
BA_ "SignalType" SG_ 2150424576 RrAxlELSDCplLwResV "ENM";
BA_ "SignalLongName" SG_ 2150424576 RrAxlELSDCplLwResV "Rear Axle Electronic Limited Slip Differential Coupling Low Resolution Validity";
BA_ "VNSigAllNodes" SG_ 2150424576 RrAxlELSDCplLwRes 1;
BA_ "SignalType" SG_ 2150424576 RrAxlELSDCplLwRes "UNM";
BA_ "SignalLongName" SG_ 2150424576 RrAxlELSDCplLwRes "Rear Axle Electronic Limited Slip Differential Coupling Low Resolution";
BA_ "VNSigAllNodes" SG_ 2150424576 EngTrqDrRqdExtRngV 1;
BA_ "SignalType" SG_ 2150424576 EngTrqDrRqdExtRngV "ENM";
BA_ "SignalLongName" SG_ 2150424576 EngTrqDrRqdExtRngV "Engine Torque Driver Requested Extended Range Validity";
BA_ "VNSigAllNodes" SG_ 2150424576 EngTrqDrRqdExtRng 1;
BA_ "SignalType" SG_ 2150424576 EngTrqDrRqdExtRng "UNM";
BA_ "SignalLongName" SG_ 2150424576 EngTrqDrRqdExtRng "Engine Torque Driver Requested Extended Range";
BA_ "GenSigStartValue" SG_ 2150424576 EngTrqDrRqdExtRng 1696;
BA_ "VNSigAllNodes" SG_ 2150424576 EngAirIntBstPrV 1;
BA_ "SignalType" SG_ 2150424576 EngAirIntBstPrV "ENM";
BA_ "SignalLongName" SG_ 2150424576 EngAirIntBstPrV "Engine Intake Air Boost Pressure Validity";
BA_ "VNSigAllNodes" SG_ 2150424576 TrnsRngInhbtStat 1;
BA_ "SignalType" SG_ 2150424576 TrnsRngInhbtStat "ENM";
BA_ "SignalLongName" SG_ 2150424576 TrnsRngInhbtStat "Transmission Range Inhibit Status";
BA_ "VNSigAllNodes" SG_ 2150424576 DrvtShftCntrlTrgtGear 1;
BA_ "SignalType" SG_ 2150424576 DrvtShftCntrlTrgtGear "ENM";
BA_ "SignalLongName" SG_ 2150424576 DrvtShftCntrlTrgtGear "Driver Shift Control Target Gear";
BA_ "VNSigAllNodes" SG_ 2150424576 EngAirIntBstPr 1;
BA_ "SignalType" SG_ 2150424576 EngAirIntBstPr "SNM";
BA_ "SignalLongName" SG_ 2150424576 EngAirIntBstPr "Engine Intake Air Boost Pressure";
BA_ "VNSigAllNodes" SG_ 2150424576 ACCmpNrmLdGrdAld 1;
BA_ "SignalType" SG_ 2150424576 ACCmpNrmLdGrdAld "UNM";
BA_ "SignalLongName" SG_ 2150424576 ACCmpNrmLdGrdAld "Air Conditioning Compressor Normalized Load Gradient Allowed";
BA_ "VNSigAllNodes" SG_ 2150424576 TrnsEngdStateV 1;
BA_ "SignalType" SG_ 2150424576 TrnsEngdStateV "ENM";
BA_ "SignalLongName" SG_ 2150424576 TrnsEngdStateV "Transmission Engaged State Validity";
BA_ "VNSigAllNodes" SG_ 2150424576 ACRfHiSdFldPrsV 1;
BA_ "SignalType" SG_ 2150424576 ACRfHiSdFldPrsV "ENM";
BA_ "SignalLongName" SG_ 2150424576 ACRfHiSdFldPrsV "Air Conditioning Refrigerant High Side Fluid Pressure Validity";
BA_ "VNSigAllNodes" SG_ 2150424576 ACRfHiSdFldPrs 1;
BA_ "SignalType" SG_ 2150424576 ACRfHiSdFldPrs "UNM";
BA_ "SignalLongName" SG_ 2150424576 ACRfHiSdFldPrs "Air Conditioning Refrigerant High Side Fluid Pressure";
BA_ "VNSigAllNodes" SG_ 2150424576 ACCompCmnd 1;
BA_ "SignalType" SG_ 2150424576 ACCompCmnd "ENM";
BA_ "SignalLongName" SG_ 2150424576 ACCompCmnd "Air Conditioning Compressor Command";
BA_ "VNSigAllNodes" SG_ 2150424576 TrnsEngdState 1;
BA_ "SignalType" SG_ 2150424576 TrnsEngdState "ENM";
BA_ "SignalLongName" SG_ 2150424576 TrnsEngdState "Transmission Engaged State";
BA_ "GenSigSendOnInit" SG_ 2155954176 ClmCntRrBlwFnSp 2;
BA_ "GenSigSendType" SG_ 2155954176 ClmCntRrBlwFnSp 12;
BA_ "GenSigDeltaValue" SG_ 2155954176 ClmCntRrBlwFnSp 1;
BA_ "VNSigAllNodes" SG_ 2155954176 ClmCntRrBlwFnSp 1;
BA_ "SignalType" SG_ 2155954176 ClmCntRrBlwFnSp "UNM";
BA_ "SignalLongName" SG_ 2155954176 ClmCntRrBlwFnSp "Climate Control Rear Blower Fan Speed";
BA_ "GenSigSendOnInit" SG_ 2155954176 ClmCntlExtDefActIO 2;
BA_ "GenSigSendType" SG_ 2155954176 ClmCntlExtDefActIO 10;
BA_ "VNSigAllNodes" SG_ 2155954176 ClmCntlExtDefActIO 1;
BA_ "SignalType" SG_ 2155954176 ClmCntlExtDefActIO "BLN";
BA_ "SignalLongName" SG_ 2155954176 ClmCntlExtDefActIO "Climate Control Extended Defrost Active Indication On";
BA_ "VNSigIntermediate" SG_ 2155954176 ClntCircPmpRq 1;
BA_ "GenSigSendOnInit" SG_ 2155954176 ClntCircPmpRq 2;
BA_ "GenSigSendType" SG_ 2155954176 ClntCircPmpRq 10;
BA_ "VNSigAllNodes" SG_ 2155954176 ClntCircPmpRq 1;
BA_ "SignalType" SG_ 2155954176 ClntCircPmpRq "ENM";
BA_ "SignalLongName" SG_ 2155954176 ClntCircPmpRq "Coolant Circulation Pump Request";
BA_ "VNSigIntermediate" SG_ 2155954176 ClimCtrlAftBlowModActv 1;
BA_ "GenSigSendOnInit" SG_ 2155954176 ClimCtrlAftBlowModActv 1;
BA_ "GenSigSendType" SG_ 2155954176 ClimCtrlAftBlowModActv 10;
BA_ "VNSigAllNodes" SG_ 2155954176 ClimCtrlAftBlowModActv 1;
BA_ "SignalType" SG_ 2155954176 ClimCtrlAftBlowModActv "BLN";
BA_ "SignalLongName" SG_ 2155954176 ClimCtrlAftBlowModActv "Climate Control Afterblow Mode Active";
BA_ "VNSigIntermediate" SG_ 2155954176 ClmCntFrBlwFnSp 1;
BA_ "GenSigSendOnInit" SG_ 2155954176 ClmCntFrBlwFnSp 2;
BA_ "GenSigSendType" SG_ 2155954176 ClmCntFrBlwFnSp 12;
BA_ "GenSigDeltaValue" SG_ 2155954176 ClmCntFrBlwFnSp 1;
BA_ "VNSigAllNodes" SG_ 2155954176 ClmCntFrBlwFnSp 1;
BA_ "SignalType" SG_ 2155954176 ClmCntFrBlwFnSp "UNM";
BA_ "SignalLongName" SG_ 2155954176 ClmCntFrBlwFnSp "Climate Control Front Blower Fan Speed";
BA_ "GenSigSendOnInit" SG_ 2155954176 ACHtIdleBstLevReq 1;
BA_ "GenSigSendType" SG_ 2155954176 ACHtIdleBstLevReq 10;
BA_ "VNSigAllNodes" SG_ 2155954176 ACHtIdleBstLevReq 1;
BA_ "SignalType" SG_ 2155954176 ACHtIdleBstLevReq "ENM";
BA_ "SignalLongName" SG_ 2155954176 ACHtIdleBstLevReq "Air Conditioning and Heating Idle Boost Level Request";
BA_ "GenSigSendOnInit" SG_ 2155954176 AirCndCmptLdEst 2;
BA_ "GenSigSendType" SG_ 2155954176 AirCndCmptLdEst 12;
BA_ "GenSigDeltaValue" SG_ 2155954176 AirCndCmptLdEst 1;
BA_ "VNSigAllNodes" SG_ 2155954176 AirCndCmptLdEst 1;
BA_ "SignalType" SG_ 2155954176 AirCndCmptLdEst "UNM";
BA_ "SignalLongName" SG_ 2155954176 AirCndCmptLdEst "Air Conditioning Compartment Load Estimated";
BA_ "GenSigSendOnInit" SG_ 2155954176 AirCndActIO 2;
BA_ "GenSigSendType" SG_ 2155954176 AirCndActIO 10;
BA_ "VNSigAllNodes" SG_ 2155954176 AirCndActIO 1;
BA_ "SignalType" SG_ 2155954176 AirCndActIO "BLN";
BA_ "SignalLongName" SG_ 2155954176 AirCndActIO "Air Conditioning Active Indication On";
BA_ "VNSigAllNodes" SG_ 2149875712 DCCnvStblznErrIO 1;
BA_ "SignalType" SG_ 2149875712 DCCnvStblznErrIO "BLN";
BA_ "SignalLongName" SG_ 2149875712 DCCnvStblznErrIO "DC Converter Stabilization Error Indication On";
BA_ "VNSigAllNodes" SG_ 2149875712 BattStOfChrgLowIO 1;
BA_ "SignalType" SG_ 2149875712 BattStOfChrgLowIO "BLN";
BA_ "SignalLongName" SG_ 2149875712 BattStOfChrgLowIO "Battery State of Charge Low Indication On";
BA_ "VNSigAllNodes" SG_ 2149875712 BattCrntFltrd 1;
BA_ "SignalType" SG_ 2149875712 BattCrntFltrd "SNM";
BA_ "SignalLongName" SG_ 2149875712 BattCrntFltrd "Battery Current Filtered";
BA_ "VNSigAllNodes" SG_ 2149875712 IntlgntBattSnsFldIO 1;
BA_ "SignalType" SG_ 2149875712 IntlgntBattSnsFldIO "BLN";
BA_ "SignalLongName" SG_ 2149875712 IntlgntBattSnsFldIO "Intelligent Battery Sensor Failed Indication On";
BA_ "VNSigAllNodes" SG_ 2149875712 BatSvrMdSevLvl 1;
BA_ "SignalType" SG_ 2149875712 BatSvrMdSevLvl "UNM";
BA_ "SignalLongName" SG_ 2149875712 BatSvrMdSevLvl "Battery Saver Mode Severity Level";
BA_ "VNSigAllNodes" SG_ 2149875712 BatSOCV 1;
BA_ "SignalType" SG_ 2149875712 BatSOCV "ENM";
BA_ "SignalLongName" SG_ 2149875712 BatSOCV "Battery State of Charge Validity";
BA_ "VNSigAllNodes" SG_ 2149875712 PwrMdOffBattSOC 1;
BA_ "SignalType" SG_ 2149875712 PwrMdOffBattSOC "UNM";
BA_ "SignalLongName" SG_ 2149875712 PwrMdOffBattSOC "Power Mode Off Battery State Of Charge";
BA_ "VNSigAllNodes" SG_ 2149875712 EnrgMgtLdShdRq 1;
BA_ "SignalType" SG_ 2149875712 EnrgMgtLdShdRq "ENM";
BA_ "SignalLongName" SG_ 2149875712 EnrgMgtLdShdRq "Energy Management Load Shedding Request";
BA_ "VNSigAllNodes" SG_ 2149875712 SrvBattChrgSysIO 1;
BA_ "SignalType" SG_ 2149875712 SrvBattChrgSysIO "BLN";
BA_ "SignalLongName" SG_ 2149875712 SrvBattChrgSysIO "Service Battery Charging System Indication On";
BA_ "VNSigIntermediate" SG_ 2149875712 BattStOfChrgCrtyLow 1;
BA_ "VNSigAllNodes" SG_ 2149875712 BattStOfChrgCrtyLow 1;
BA_ "SignalType" SG_ 2149875712 BattStOfChrgCrtyLow "BLN";
BA_ "SignalLongName" SG_ 2149875712 BattStOfChrgCrtyLow "Battery State of Charge Critically Low";
BA_ "VNSigAllNodes" SG_ 2149875712 BatSaverIO 1;
BA_ "SignalType" SG_ 2149875712 BatSaverIO "BLN";
BA_ "SignalLongName" SG_ 2149875712 BatSaverIO "Battery Saver Indication On";
BA_ "VNSigAllNodes" SG_ 2149875712 BatSOC 1;
BA_ "SignalType" SG_ 2149875712 BatSOC "UNM";
BA_ "SignalLongName" SG_ 2149875712 BatSOC "Battery State of Charge";
BA_ "VNSigAllNodes" SG_ 2149875712 BattVltIRq 1;
BA_ "SignalType" SG_ 2149875712 BattVltIRq "ENM";
BA_ "SignalLongName" SG_ 2149875712 BattVltIRq "Battery Voltage Indication Request";
BA_ "VNSigAllNodes" SG_ 2149875712 BatVltV 1;
BA_ "SignalType" SG_ 2149875712 BatVltV "ENM";
BA_ "SignalLongName" SG_ 2149875712 BatVltV "Battery Voltage Validity";
BA_ "VNSigAllNodes" SG_ 2149875712 BatVlt 1;
BA_ "SignalType" SG_ 2149875712 BatVlt "UNM";
BA_ "SignalLongName" SG_ 2149875712 BatVlt "Battery Voltage";
BA_ "VNSigIntermediate" SG_ 2154053632 TrlrLtngSeqStat 1;
BA_ "GenSigSendOnInit" SG_ 2154053632 TrlrLtngSeqStat 2;
BA_ "GenSigSendType" SG_ 2154053632 TrlrLtngSeqStat 10;
BA_ "VNSigAllNodes" SG_ 2154053632 TrlrLtngSeqStat 1;
BA_ "SignalType" SG_ 2154053632 TrlrLtngSeqStat "ENM";
BA_ "SignalLongName" SG_ 2154053632 TrlrLtngSeqStat "Trailer Lighting Sequence Status";
BA_ "GenSigSendType" SG_ 2154053632 CargoLmpActIO 10;
BA_ "VNSigAllNodes" SG_ 2154053632 CargoLmpActIO 1;
BA_ "SignalType" SG_ 2154053632 CargoLmpActIO "BLN";
BA_ "SignalLongName" SG_ 2154053632 CargoLmpActIO "Cargo Lamp Active Indication On";
BA_ "GenSigSendOnInit" SG_ 2154053632 DispNtSchmAtv 2;
BA_ "GenSigSendType" SG_ 2154053632 DispNtSchmAtv 10;
BA_ "VNSigAllNodes" SG_ 2154053632 DispNtSchmAtv 1;
BA_ "SignalType" SG_ 2154053632 DispNtSchmAtv "BLN";
BA_ "SignalLongName" SG_ 2154053632 DispNtSchmAtv "Display Night Scheme Active";
BA_ "GenSigSendOnInit" SG_ 2154053632 IntDimLvl 2;
BA_ "GenSigSendType" SG_ 2154053632 IntDimLvl 12;
BA_ "GenSigDeltaValue" SG_ 2154053632 IntDimLvl 1;
BA_ "VNSigAllNodes" SG_ 2154053632 IntDimLvl 1;
BA_ "SignalType" SG_ 2154053632 IntDimLvl "UNM";
BA_ "SignalLongName" SG_ 2154053632 IntDimLvl "Interior Dimming Level";
BA_ "GenSigSendOnInit" SG_ 2154053632 IntDimDspLvl 2;
BA_ "GenSigSendType" SG_ 2154053632 IntDimDspLvl 12;
BA_ "GenSigDeltaValue" SG_ 2154053632 IntDimDspLvl 1;
BA_ "VNSigAllNodes" SG_ 2154053632 IntDimDspLvl 1;
BA_ "SignalType" SG_ 2154053632 IntDimDspLvl "UNM";
BA_ "SignalLongName" SG_ 2154053632 IntDimDspLvl "Interior Dimming Display Level";
BA_ "GenSigSendType" SG_ 2154053632 IntDimNtPnlAtv 10;
BA_ "VNSigAllNodes" SG_ 2154053632 IntDimNtPnlAtv 1;
BA_ "SignalType" SG_ 2154053632 IntDimNtPnlAtv "BLN";
BA_ "SignalLongName" SG_ 2154053632 IntDimNtPnlAtv "Interior Dimming Night Panel Active";
BA_ "GenSigSendType" SG_ 2033 PCUInfo 12;
BA_ "GenSigDeltaValue" SG_ 2033 PCUInfo 1;
BA_ "VNSigAllNodes" SG_ 2033 PCUInfo 1;
BA_ "SignalType" SG_ 2033 PCUInfo "UNM";
BA_ "SignalLongName" SG_ 2033 PCUInfo "Pyrotechnical Control Unit Information";
BA_ "GenSigSendType" SG_ 2151530496 HVBTBDCSRR1_DChMHSRq 12;
BA_ "GenSigDeltaValue" SG_ 2151530496 HVBTBDCSRR1_DChMHSRq 1;
BA_ "VNSigAllNodes" SG_ 2151530496 HVBTBDCSRR1_DChMHSRq 1;
BA_ "SignalType" SG_ 2151530496 HVBTBDCSRR1_DChMHSRq "UNM";
BA_ "PacketOrder" SG_ 2151530496 HVBTBDCSRR1_DChMHSRq 5;
BA_ "SignalLongName" SG_ 2151530496 HVBTBDCSRR1_DChMHSRq "High Voltage Battery Time Based Delayed Charging Set Request Remote 1 : Delayed Charging Minute of Hour Set Request";
BA_ "GenSigSendType" SG_ 2151530496 HVBTBDCSRR1_DChSnSRq 10;
BA_ "VNSigAllNodes" SG_ 2151530496 HVBTBDCSRR1_DChSnSRq 1;
BA_ "SignalType" SG_ 2151530496 HVBTBDCSRR1_DChSnSRq "ENM";
BA_ "PacketOrder" SG_ 2151530496 HVBTBDCSRR1_DChSnSRq 4;
BA_ "SignalLongName" SG_ 2151530496 HVBTBDCSRR1_DChSnSRq "High Voltage Battery Time Based Delayed Charging Set Request Remote 1 : Delayed Charging Season Set Request";
BA_ "GenSigSendType" SG_ 2151530496 HVBTBDCSRR1_DChSlSRq 10;
BA_ "VNSigAllNodes" SG_ 2151530496 HVBTBDCSRR1_DChSlSRq 1;
BA_ "SignalType" SG_ 2151530496 HVBTBDCSRR1_DChSlSRq "ENM";
BA_ "PacketOrder" SG_ 2151530496 HVBTBDCSRR1_DChSlSRq 3;
BA_ "SignalLongName" SG_ 2151530496 HVBTBDCSRR1_DChSlSRq "High Voltage Battery Time Based Delayed Charging Set Request Remote 1 : Delayed Charging Selected Set Request";
BA_ "GenSigSendType" SG_ 2151530496 HVBTBDCSRR1_DChDStRq 10;
BA_ "VNSigAllNodes" SG_ 2151530496 HVBTBDCSRR1_DChDStRq 1;
BA_ "SignalType" SG_ 2151530496 HVBTBDCSRR1_DChDStRq "ENM";
BA_ "PacketOrder" SG_ 2151530496 HVBTBDCSRR1_DChDStRq 2;
BA_ "SignalLongName" SG_ 2151530496 HVBTBDCSRR1_DChDStRq "High Voltage Battery Time Based Delayed Charging Set Request Remote 1 : Delayed Charging Day Set Request";
BA_ "GenSigSendType" SG_ 2151530496 HVBTBDCSRR1_DChHStRq 12;
BA_ "GenSigDeltaValue" SG_ 2151530496 HVBTBDCSRR1_DChHStRq 1;
BA_ "VNSigAllNodes" SG_ 2151530496 HVBTBDCSRR1_DChHStRq 1;
BA_ "SignalType" SG_ 2151530496 HVBTBDCSRR1_DChHStRq "UNM";
BA_ "PacketOrder" SG_ 2151530496 HVBTBDCSRR1_DChHStRq 1;
BA_ "SignalLongName" SG_ 2151530496 HVBTBDCSRR1_DChHStRq "High Voltage Battery Time Based Delayed Charging Set Request Remote 1 : Delayed Charging Hour Set Request";
BA_ "GenSigSendType" SG_ 2151530496 HVBatTmBsChgMdRqRmt1 10;
BA_ "VNSigAllNodes" SG_ 2151530496 HVBatTmBsChgMdRqRmt1 1;
BA_ "SignalType" SG_ 2151530496 HVBatTmBsChgMdRqRmt1 "ENM";
BA_ "SignalLongName" SG_ 2151530496 HVBatTmBsChgMdRqRmt1 "High Voltage Battery Time Based Charging Mode Request Remote 1";
BA_ "GenSigSendType" SG_ 2151530496 HVChgSyChgLvPfStRmt1 10;
BA_ "VNSigAllNodes" SG_ 2151530496 HVChgSyChgLvPfStRmt1 1;
BA_ "SignalType" SG_ 2151530496 HVChgSyChgLvPfStRmt1 "ENM";
BA_ "SignalLongName" SG_ 2151530496 HVChgSyChgLvPfStRmt1 "High Voltage Charging System Charge Level Preference Setting Remote 1";
BA_ "GenSigSendType" SG_ 2151530496 StTODChrgTmpOvrdRmt1 10;
BA_ "VNSigAllNodes" SG_ 2151530496 StTODChrgTmpOvrdRmt1 1;
BA_ "SignalType" SG_ 2151530496 StTODChrgTmpOvrdRmt1 "ENM";
BA_ "SignalLongName" SG_ 2151530496 StTODChrgTmpOvrdRmt1 "Set Time of Day Charge Temporary Override Remote 1";
BA_ "GenSigSendType" SG_ 2151530496 PrtyChrgRqRmt1 10;
BA_ "VNSigAllNodes" SG_ 2151530496 PrtyChrgRqRmt1 1;
BA_ "SignalType" SG_ 2151530496 PrtyChrgRqRmt1 "ENM";
BA_ "SignalLongName" SG_ 2151530496 PrtyChrgRqRmt1 "Priority Charging Request Remote 1";
BA_ "GenSigSendType" SG_ 2151530496 OfBrdHVCVhCsChRqRmt1 10;
BA_ "VNSigAllNodes" SG_ 2151530496 OfBrdHVCVhCsChRqRmt1 1;
BA_ "SignalType" SG_ 2151530496 OfBrdHVCVhCsChRqRmt1 "BLN";
BA_ "SignalLongName" SG_ 2151530496 OfBrdHVCVhCsChRqRmt1 "Off Board High Voltage Charging Vehicle Cease Charging Requested Remote 1";
BA_ "GenSigSendType" SG_ 2151530496 TireTrdTmpStat 10;
BA_ "VNSigAllNodes" SG_ 2151530496 TireTrdTmpStat 1;
BA_ "SignalType" SG_ 2151530496 TireTrdTmpStat "ENM";
BA_ "SignalLongName" SG_ 2151530496 TireTrdTmpStat "Tire Tread Temperature Status";
BA_ "GenSigSendType" SG_ 2151530496 TrPrsMntrTrLdStat 10;
BA_ "VNSigAllNodes" SG_ 2151530496 TrPrsMntrTrLdStat 1;
BA_ "SignalType" SG_ 2151530496 TrPrsMntrTrLdStat "ENM";
BA_ "SignalLongName" SG_ 2151530496 TrPrsMntrTrLdStat "Tire Pressure Monitoring Tire Loading Status";
BA_ "GenSigSendType" SG_ 2151530496 TrPrsMntrAtLocFld 10;
BA_ "VNSigAllNodes" SG_ 2151530496 TrPrsMntrAtLocFld 1;
BA_ "SignalType" SG_ 2151530496 TrPrsMntrAtLocFld "BLN";
BA_ "SignalLongName" SG_ 2151530496 TrPrsMntrAtLocFld "Tire Pressure Monitoring Autolocation System Failed";
BA_ "GenSigSendType" SG_ 2151530496 TireLocatnWarnEn 10;
BA_ "VNSigAllNodes" SG_ 2151530496 TireLocatnWarnEn 1;
BA_ "SignalType" SG_ 2151530496 TireLocatnWarnEn "BLN";
BA_ "SignalLongName" SG_ 2151530496 TireLocatnWarnEn "Tire Location Warnings Enabled";
BA_ "GenSigSendType" SG_ 2151530496 WintTrRecIndOn 10;
BA_ "VNSigAllNodes" SG_ 2151530496 WintTrRecIndOn 1;
BA_ "SignalType" SG_ 2151530496 WintTrRecIndOn "BLN";
BA_ "SignalLongName" SG_ 2151530496 WintTrRecIndOn "Winter Tire Recognition Indication On";
BA_ "GenSigSendType" SG_ 2151530496 TrPrsMntrFld 10;
BA_ "VNSigAllNodes" SG_ 2151530496 TrPrsMntrFld 1;
BA_ "SignalType" SG_ 2151530496 TrPrsMntrFld "BLN";
BA_ "SignalLongName" SG_ 2151530496 TrPrsMntrFld "Tire Pressure Monitoring System Failed";
BA_ "GenSigSendType" SG_ 2151530496 TrRrAxlPresStat 10;
BA_ "VNSigAllNodes" SG_ 2151530496 TrRrAxlPresStat 1;
BA_ "SignalType" SG_ 2151530496 TrRrAxlPresStat "ENM";
BA_ "SignalLongName" SG_ 2151530496 TrRrAxlPresStat "Tire Rear Axle Pressure Status";
BA_ "GenSigSendType" SG_ 2151530496 TrFrntAxlPresStat 10;
BA_ "VNSigAllNodes" SG_ 2151530496 TrFrntAxlPresStat 1;
BA_ "SignalType" SG_ 2151530496 TrFrntAxlPresStat "ENM";
BA_ "SignalLongName" SG_ 2151530496 TrFrntAxlPresStat "Tire Front Axle Pressure Status";
BA_ "GenSigSendOnInit" SG_ 2151530496 TPMTrLrnMdCmplt 2;
BA_ "GenSigSendType" SG_ 2151530496 TPMTrLrnMdCmplt 10;
BA_ "VNSigAllNodes" SG_ 2151530496 TPMTrLrnMdCmplt 1;
BA_ "SignalType" SG_ 2151530496 TPMTrLrnMdCmplt "BLN";
BA_ "SignalLongName" SG_ 2151530496 TPMTrLrnMdCmplt "Tire Pressure Monitoring Tire Learn Mode Complete";
BA_ "GenSigStartValue" SG_ 2151530496 TPMTrLrnMdCmplt 1;
BA_ "GenSigSendOnInit" SG_ 2153824256 TeenDrvAccelLimIO 2;
BA_ "GenSigSendType" SG_ 2153824256 TeenDrvAccelLimIO 10;
BA_ "VNSigAllNodes" SG_ 2153824256 TeenDrvAccelLimIO 1;
BA_ "SignalType" SG_ 2153824256 TeenDrvAccelLimIO "BLN";
BA_ "SignalLongName" SG_ 2153824256 TeenDrvAccelLimIO "Teen Driver Acceleration Limit Indication On";
BA_ "GenSigSendOnInit" SG_ 2153824256 TeenDrvDistDrvnRpt 2;
BA_ "GenSigSendType" SG_ 2153824256 TeenDrvDistDrvnRpt 12;
BA_ "GenSigDeltaValue" SG_ 2153824256 TeenDrvDistDrvnRpt 1;
BA_ "VNSigAllNodes" SG_ 2153824256 TeenDrvDistDrvnRpt 1;
BA_ "SignalType" SG_ 2153824256 TeenDrvDistDrvnRpt "UNM";
BA_ "SignalLongName" SG_ 2153824256 TeenDrvDistDrvnRpt "Teen Driver Distance Driven Report";
BA_ "GenSigSendOnInit" SG_ 2153824256 TnDrvOvSpdEvntsRpt 2;
BA_ "GenSigSendType" SG_ 2153824256 TnDrvOvSpdEvntsRpt 12;
BA_ "GenSigDeltaValue" SG_ 2153824256 TnDrvOvSpdEvntsRpt 1;
BA_ "VNSigAllNodes" SG_ 2153824256 TnDrvOvSpdEvntsRpt 1;
BA_ "SignalType" SG_ 2153824256 TnDrvOvSpdEvntsRpt "UNM";
BA_ "SignalLongName" SG_ 2153824256 TnDrvOvSpdEvntsRpt "Teen Driver Overspeed Events Report";
BA_ "GenSigSendOnInit" SG_ 2153824256 TeenDrvRsp 2;
BA_ "GenSigSendType" SG_ 2153824256 TeenDrvRsp 10;
BA_ "VNSigAllNodes" SG_ 2153824256 TeenDrvRsp 1;
BA_ "SignalType" SG_ 2153824256 TeenDrvRsp "ENM";
BA_ "SignalLongName" SG_ 2153824256 TeenDrvRsp "Teen Driver Response";
BA_ "GenSigSendOnInit" SG_ 2153824256 TeenDrvFtrAvl 2;
BA_ "GenSigSendType" SG_ 2153824256 TeenDrvFtrAvl 10;
BA_ "VNSigAllNodes" SG_ 2153824256 TeenDrvFtrAvl 1;
BA_ "SignalType" SG_ 2153824256 TeenDrvFtrAvl "BLN";
BA_ "SignalLongName" SG_ 2153824256 TeenDrvFtrAvl "Teen Driver Feature Available";
BA_ "GenSigSendOnInit" SG_ 2153824256 TeenDrvPINStrd 2;
BA_ "GenSigSendType" SG_ 2153824256 TeenDrvPINStrd 10;
BA_ "VNSigAllNodes" SG_ 2153824256 TeenDrvPINStrd 1;
BA_ "SignalType" SG_ 2153824256 TeenDrvPINStrd "BLN";
BA_ "SignalLongName" SG_ 2153824256 TeenDrvPINStrd "Teen Driver PIN Stored";
BA_ "GenSigSendType" SG_ 2153824256 TnDrvGapAdjUnbIO 10;
BA_ "VNSigAllNodes" SG_ 2153824256 TnDrvGapAdjUnbIO 1;
BA_ "SignalType" SG_ 2153824256 TnDrvGapAdjUnbIO "BLN";
BA_ "SignalLongName" SG_ 2153824256 TnDrvGapAdjUnbIO "Teen Driver Gap Adjust Unavailable Indication On";
BA_ "GenSigSendType" SG_ 2153824256 TnDrvOvrSpdIO 10;
BA_ "VNSigAllNodes" SG_ 2153824256 TnDrvOvrSpdIO 1;
BA_ "SignalType" SG_ 2153824256 TnDrvOvrSpdIO "BLN";
BA_ "SignalLongName" SG_ 2153824256 TnDrvOvrSpdIO "Teen Driver Overspeed Indication On";
BA_ "GenSigSendOnInit" SG_ 2153824256 TDOvSpdWrnCstStAvl 2;
BA_ "GenSigSendType" SG_ 2153824256 TDOvSpdWrnCstStAvl 10;
BA_ "VNSigAllNodes" SG_ 2153824256 TDOvSpdWrnCstStAvl 1;
BA_ "SignalType" SG_ 2153824256 TDOvSpdWrnCstStAvl "BLN";
BA_ "SignalLongName" SG_ 2153824256 TDOvSpdWrnCstStAvl "Teen Driver Overspeed Warning Customization Setting Available";
BA_ "GenSigSendOnInit" SG_ 2153824256 TDOWCCSV_CrStVl 2;
BA_ "GenSigSendType" SG_ 2153824256 TDOWCCSV_CrStVl 12;
BA_ "GenSigDeltaValue" SG_ 2153824256 TDOWCCSV_CrStVl 16;
BA_ "VNSigAllNodes" SG_ 2153824256 TDOWCCSV_CrStVl 1;
BA_ "SignalType" SG_ 2153824256 TDOWCCSV_CrStVl "UNM";
BA_ "PacketOrder" SG_ 2153824256 TDOWCCSV_CrStVl 2;
BA_ "SignalLongName" SG_ 2153824256 TDOWCCSV_CrStVl "Teen Driver Overspeed Warning Customization Current Setting Value : Current Setting Value";
BA_ "GenSigSendOnInit" SG_ 2153824256 TDOWCCSV_CrStat 2;
BA_ "GenSigSendType" SG_ 2153824256 TDOWCCSV_CrStat 10;
BA_ "VNSigAllNodes" SG_ 2153824256 TDOWCCSV_CrStat 1;
BA_ "SignalType" SG_ 2153824256 TDOWCCSV_CrStat "ENM";
BA_ "PacketOrder" SG_ 2153824256 TDOWCCSV_CrStat 1;
BA_ "SignalLongName" SG_ 2153824256 TDOWCCSV_CrStat "Teen Driver Overspeed Warning Customization Current Setting Value : Current Status";
BA_ "GenSigSendOnInit" SG_ 2153824256 TnDrvSpdLmtCstStAvl 2;
BA_ "GenSigSendType" SG_ 2153824256 TnDrvSpdLmtCstStAvl 10;
BA_ "VNSigAllNodes" SG_ 2153824256 TnDrvSpdLmtCstStAvl 1;
BA_ "SignalType" SG_ 2153824256 TnDrvSpdLmtCstStAvl "BLN";
BA_ "SignalLongName" SG_ 2153824256 TnDrvSpdLmtCstStAvl "Teen Driver Speed Limit Customization Setting Available";
BA_ "GenSigSendOnInit" SG_ 2153824256 TDSLCCSV_SpLmtStat 2;
BA_ "GenSigSendType" SG_ 2153824256 TDSLCCSV_SpLmtStat 10;
BA_ "VNSigAllNodes" SG_ 2153824256 TDSLCCSV_SpLmtStat 1;
BA_ "SignalType" SG_ 2153824256 TDSLCCSV_SpLmtStat "ENM";
BA_ "PacketOrder" SG_ 2153824256 TDSLCCSV_SpLmtStat 1;
BA_ "SignalLongName" SG_ 2153824256 TDSLCCSV_SpLmtStat "Teen Driver Speed Limit Customization Current Setting Value : Speed Limit Status";
BA_ "GenSigSendOnInit" SG_ 2153824256 TDSLCCSV_SpLmDisVl 2;
BA_ "GenSigSendType" SG_ 2153824256 TDSLCCSV_SpLmDisVl 12;
BA_ "GenSigDeltaValue" SG_ 2153824256 TDSLCCSV_SpLmDisVl 1;
BA_ "VNSigAllNodes" SG_ 2153824256 TDSLCCSV_SpLmDisVl 1;
BA_ "SignalType" SG_ 2153824256 TDSLCCSV_SpLmDisVl "UNM";
BA_ "PacketOrder" SG_ 2153824256 TDSLCCSV_SpLmDisVl 2;
BA_ "SignalLongName" SG_ 2153824256 TDSLCCSV_SpLmDisVl "Teen Driver Speed Limit Customization Current Setting Value : Speed Limit Display Value";
BA_ "GenSigSendOnInit" SG_ 2153824256 TeenDrvAct 2;
BA_ "GenSigSendType" SG_ 2153824256 TeenDrvAct 10;
BA_ "VNSigAllNodes" SG_ 2153824256 TeenDrvAct 1;
BA_ "SignalType" SG_ 2153824256 TeenDrvAct "BLN";
BA_ "SignalLongName" SG_ 2153824256 TeenDrvAct "Teen Driver Active";
BA_ "GenSigSendOnInit" SG_ 2149957632 PrkAstRrObjSnsngRqAct 2;
BA_ "GenSigSendType" SG_ 2149957632 PrkAstRrObjSnsngRqAct 10;
BA_ "VNSigAllNodes" SG_ 2149957632 PrkAstRrObjSnsngRqAct 1;
BA_ "SignalType" SG_ 2149957632 PrkAstRrObjSnsngRqAct "BLN";
BA_ "SignalLongName" SG_ 2149957632 PrkAstRrObjSnsngRqAct "Park Assistance Rear Object Sensing Request Active";
BA_ "GenSigSendOnInit" SG_ 2149957632 PrkAstOprtrDsrdStat 2;
BA_ "GenSigSendType" SG_ 2149957632 PrkAstOprtrDsrdStat 10;
BA_ "VNSigAllNodes" SG_ 2149957632 PrkAstOprtrDsrdStat 1;
BA_ "SignalType" SG_ 2149957632 PrkAstOprtrDsrdStat "ENM";
BA_ "SignalLongName" SG_ 2149957632 PrkAstOprtrDsrdStat "Park Assistance Operator Desired Status";
BA_ "GenSigSendOnInit" SG_ 2149957632 PrkAstInhbtReq 2;
BA_ "GenSigSendType" SG_ 2149957632 PrkAstInhbtReq 10;
BA_ "VNSigAllNodes" SG_ 2149957632 PrkAstInhbtReq 1;
BA_ "SignalType" SG_ 2149957632 PrkAstInhbtReq "BLN";
BA_ "SignalLongName" SG_ 2149957632 PrkAstInhbtReq "Park Assistance Inhibit Request";
BA_ "GenSigSendOnInit" SG_ 2149957632 ClsnMtgtnInhbtd 2;
BA_ "GenSigSendType" SG_ 2149957632 ClsnMtgtnInhbtd 10;
BA_ "VNSigAllNodes" SG_ 2149957632 ClsnMtgtnInhbtd 1;
BA_ "SignalType" SG_ 2149957632 ClsnMtgtnInhbtd "BLN";
BA_ "SignalLongName" SG_ 2149957632 ClsnMtgtnInhbtd "Collision Mitigation Inhibited";
BA_ "GenSigSendType" SG_ 2151751680 HptcStFldIO 10;
BA_ "VNSigAllNodes" SG_ 2151751680 HptcStFldIO 1;
BA_ "SignalType" SG_ 2151751680 HptcStFldIO "BLN";
BA_ "SignalLongName" SG_ 2151751680 HptcStFldIO "Haptic Seat Failed Indication On";
BA_ "GenSigSendType" SG_ 2151751680 HptcStVbnStat 10;
BA_ "VNSigAllNodes" SG_ 2151751680 HptcStVbnStat 1;
BA_ "SignalType" SG_ 2151751680 HptcStVbnStat "ENM";
BA_ "SignalLongName" SG_ 2151751680 HptcStVbnStat "Haptic Seat Vibration Status";
BA_ "GenSigSendOnInit" SG_ 2151751680 CrshAlrtDrvrSlctdType 1;
BA_ "GenSigSendType" SG_ 2151751680 CrshAlrtDrvrSlctdType 10;
BA_ "VNSigAllNodes" SG_ 2151751680 CrshAlrtDrvrSlctdType 1;
BA_ "SignalType" SG_ 2151751680 CrshAlrtDrvrSlctdType "ENM";
BA_ "SignalLongName" SG_ 2151751680 CrshAlrtDrvrSlctdType "Crash Alert Driver Selected Type";
BA_ "GenSigSendOnInit" SG_ 2151751680 CrshAlrtStPrsnt 1;
BA_ "GenSigSendType" SG_ 2151751680 CrshAlrtStPrsnt 10;
BA_ "VNSigAllNodes" SG_ 2151751680 CrshAlrtStPrsnt 1;
BA_ "SignalType" SG_ 2151751680 CrshAlrtStPrsnt "BLN";
BA_ "SignalLongName" SG_ 2151751680 CrshAlrtStPrsnt "Crash Alert Seat Present";
BA_ "VNSigAllNodes" SG_ 2149990400 ElcTransRngRq 1;
BA_ "SignalType" SG_ 2149990400 ElcTransRngRq "ENM";
BA_ "SignalLongName" SG_ 2149990400 ElcTransRngRq "Electronic Transmission Range Request";
BA_ "VNSigAllNodes" SG_ 2149990400 TrnsfrCsRngShfSpdLmt 1;
BA_ "SignalType" SG_ 2149990400 TrnsfrCsRngShfSpdLmt "UNM";
BA_ "SignalLongName" SG_ 2149990400 TrnsfrCsRngShfSpdLmt "Transfer Case Range Shift Speed Limit";
BA_ "VNSigAllNodes" SG_ 2149990400 TrlrBrkngVDA 1;
BA_ "SignalType" SG_ 2149990400 TrlrBrkngVDA "ENM";
BA_ "SignalLongName" SG_ 2149990400 TrlrBrkngVDA "Trailer Braking Virtual Device Availability";
BA_ "GenSigStartValue" SG_ 2149990400 TrlrBrkngVDA 1;
BA_ "VNSigAllNodes" SG_ 2149990400 InstFuelConsmpRate 1;
BA_ "SignalType" SG_ 2149990400 InstFuelConsmpRate "UNM";
BA_ "SignalLongName" SG_ 2149990400 InstFuelConsmpRate "Instantaneous Fuel Consumption Rate";
BA_ "VNSigAllNodes" SG_ 2149990400 MotStBltUnblIO 1;
BA_ "SignalType" SG_ 2149990400 MotStBltUnblIO "BLN";
BA_ "SignalLongName" SG_ 2149990400 MotStBltUnblIO "Motorized Seat Belt Unavailable Indication On";
BA_ "VNSigAllNodes" SG_ 2149990400 MotStBltFldIO 1;
BA_ "SignalType" SG_ 2149990400 MotStBltFldIO "BLN";
BA_ "SignalLongName" SG_ 2149990400 MotStBltFldIO "Motorized Seat Belt Failed Indication On";
BA_ "VNSigAllNodes" SG_ 2149990400 TransNtrlCntrlMdStat 1;
BA_ "SignalType" SG_ 2149990400 TransNtrlCntrlMdStat "ENM";
BA_ "SignalLongName" SG_ 2149990400 TransNtrlCntrlMdStat "Transmission Neutral Control Mode Status";
BA_ "VNSigAllNodes" SG_ 2149990400 TrlrWiringFltIO 1;
BA_ "SignalType" SG_ 2149990400 TrlrWiringFltIO "BLN";
BA_ "SignalLongName" SG_ 2149990400 TrlrWiringFltIO "Trailer Wiring Fault Indication On";
BA_ "VNSigAllNodes" SG_ 2149990400 TrlrCnctdIO 1;
BA_ "SignalType" SG_ 2149990400 TrlrCnctdIO "BLN";
BA_ "SignalLongName" SG_ 2149990400 TrlrCnctdIO "Trailer Connected Indication On";
BA_ "VNSigAllNodes" SG_ 2149990400 TrlrBrkngGainSetIO 1;
BA_ "SignalType" SG_ 2149990400 TrlrBrkngGainSetIO "BLN";
BA_ "SignalLongName" SG_ 2149990400 TrlrBrkngGainSetIO "Trailer Braking Gain Setting Indication On";
BA_ "VNSigAllNodes" SG_ 2149990400 TrlrBrkngGainSet 1;
BA_ "SignalType" SG_ 2149990400 TrlrBrkngGainSet "UNM";
BA_ "SignalLongName" SG_ 2149990400 TrlrBrkngGainSet "Trailer Braking Gain Setting";
BA_ "VNSigAllNodes" SG_ 2149990400 TrlrBrkngFrcOtpt 1;
BA_ "SignalType" SG_ 2149990400 TrlrBrkngFrcOtpt "UNM";
BA_ "SignalLongName" SG_ 2149990400 TrlrBrkngFrcOtpt "Trailer Braking Force Output";
BA_ "VNSigAllNodes" SG_ 2149990400 SrvTrlrBrkngSysIO 1;
BA_ "SignalType" SG_ 2149990400 SrvTrlrBrkngSysIO "BLN";
BA_ "SignalLongName" SG_ 2149990400 SrvTrlrBrkngSysIO "ServiceTrailer Braking System Indication On";
BA_ "VNSigAllNodes" SG_ 2149990400 ChkTrlrIO 1;
BA_ "SignalType" SG_ 2149990400 ChkTrlrIO "BLN";
BA_ "SignalLongName" SG_ 2149990400 ChkTrlrIO "Check Trailer Indication On";
BA_ "VNSigAllNodes" SG_ 2149990400 ScndryAxleVDA 1;
BA_ "SignalType" SG_ 2149990400 ScndryAxleVDA "ENM";
BA_ "SignalLongName" SG_ 2149990400 ScndryAxleVDA "Secondary Axle Virtual Device Availability";
BA_ "GenSigStartValue" SG_ 2149990400 ScndryAxleVDA 1;
BA_ "VNSigAllNodes" SG_ 2149990400 TrlrHtchSwAtv_ITBC 1;
BA_ "SignalType" SG_ 2149990400 TrlrHtchSwAtv_ITBC "BLN";
BA_ "SignalLongName" SG_ 2149990400 TrlrHtchSwAtv_ITBC "Trailer Hitch Switch Active ITBC";
BA_ "VNSigAllNodes" SG_ 2149990400 AdvHlmpsVDA 1;
BA_ "SignalType" SG_ 2149990400 AdvHlmpsVDA "ENM";
BA_ "SignalLongName" SG_ 2149990400 AdvHlmpsVDA "Advance Headlamps Virtual Device Availability";
BA_ "GenSigStartValue" SG_ 2149990400 AdvHlmpsVDA 1;
BA_ "VNSigAllNodes" SG_ 2149990400 ABSIO 1;
BA_ "SignalType" SG_ 2149990400 ABSIO "BLN";
BA_ "SignalLongName" SG_ 2149990400 ABSIO "Antilock Brake System Indication On";
BA_ "VNSigAllNodes" SG_ 2149990400 ACCHdwayStngIO 1;
BA_ "SignalType" SG_ 2149990400 ACCHdwayStngIO "BLN";
BA_ "SignalLongName" SG_ 2149990400 ACCHdwayStngIO "Adaptive Cruise Control Headway Setting Indication On";
BA_ "VNSigAllNodes" SG_ 2149990400 StpOnBrkToRelPBIndOn 1;
BA_ "SignalType" SG_ 2149990400 StpOnBrkToRelPBIndOn "BLN";
BA_ "SignalLongName" SG_ 2149990400 StpOnBrkToRelPBIndOn "Step On Brake To Release Park Brake Indication On";
BA_ "VNSigAllNodes" SG_ 2149990400 SADmpVDA 1;
BA_ "SignalType" SG_ 2149990400 SADmpVDA "ENM";
BA_ "SignalLongName" SG_ 2149990400 SADmpVDA "Semi Active Damping Virtual Device Availability";
BA_ "GenSigStartValue" SG_ 2149990400 SADmpVDA 1;
BA_ "VNSigAllNodes" SG_ 2149990400 ACCDrvrSeltdSpdIO 1;
BA_ "SignalType" SG_ 2149990400 ACCDrvrSeltdSpdIO "BLN";
BA_ "SignalLongName" SG_ 2149990400 ACCDrvrSeltdSpdIO "Adaptive Cruise Control Driver Selected Speed Indication On";
BA_ "VNSigAllNodes" SG_ 2149990400 TreInfMonSysRstPrfmd 1;
BA_ "SignalType" SG_ 2149990400 TreInfMonSysRstPrfmd "BLN";
BA_ "SignalLongName" SG_ 2149990400 TreInfMonSysRstPrfmd "Tire Inflation Monitoring System Reset Performed";
BA_ "VNSigAllNodes" SG_ 2149990400 DrvThrtlOvrdIO 1;
BA_ "SignalType" SG_ 2149990400 DrvThrtlOvrdIO "BLN";
BA_ "SignalLongName" SG_ 2149990400 DrvThrtlOvrdIO "Driver Throttle Override Indication On";
BA_ "VNSigAllNodes" SG_ 2149990400 SecAxlOperMod 1;
BA_ "SignalType" SG_ 2149990400 SecAxlOperMod "ENM";
BA_ "SignalLongName" SG_ 2149990400 SecAxlOperMod "Secondary Axle Operational Mode";
BA_ "VNSigAllNodes" SG_ 2155380736 ACCmCltEngd 1;
BA_ "SignalType" SG_ 2155380736 ACCmCltEngd "BLN";
BA_ "SignalLongName" SG_ 2155380736 ACCmCltEngd "Air Conditioning Compressor Clutch Engaged";
BA_ "GenSigSendType" SG_ 2155380736 StrAsstRdcdLvl3IO 10;
BA_ "VNSigAllNodes" SG_ 2155380736 StrAsstRdcdLvl3IO 1;
BA_ "SignalType" SG_ 2155380736 StrAsstRdcdLvl3IO "BLN";
BA_ "SignalLongName" SG_ 2155380736 StrAsstRdcdLvl3IO "Steering Assist Reduced Level 3 Indication On";
BA_ "GenSigSendType" SG_ 2155380736 StrAsstRdcdLvl2IO 10;
BA_ "VNSigAllNodes" SG_ 2155380736 StrAsstRdcdLvl2IO 1;
BA_ "SignalType" SG_ 2155380736 StrAsstRdcdLvl2IO "BLN";
BA_ "SignalLongName" SG_ 2155380736 StrAsstRdcdLvl2IO "Steering Assist Reduced Level 2 Indication On";
BA_ "GenSigSendType" SG_ 2155380736 StrngAsstRdcdIO 10;
BA_ "VNSigAllNodes" SG_ 2155380736 StrngAsstRdcdIO 1;
BA_ "SignalType" SG_ 2155380736 StrngAsstRdcdIO "BLN";
BA_ "SignalLongName" SG_ 2155380736 StrngAsstRdcdIO "Steering Assist Reduced Indication On";
BA_ "VNSigAllNodes" SG_ 2155380736 PwrPkFnSpd 1;
BA_ "SignalType" SG_ 2155380736 PwrPkFnSpd "UNM";
BA_ "SignalLongName" SG_ 2155380736 PwrPkFnSpd "Power Pack Fan Speed";
BA_ "VNSigAllNodes" SG_ 2155380736 PwrPckAirInTempFlt 1;
BA_ "SignalType" SG_ 2155380736 PwrPckAirInTempFlt "UNM";
BA_ "SignalLongName" SG_ 2155380736 PwrPckAirInTempFlt "Power Pack Air Inlet Temperature Filtered";
BA_ "VNSigAllNodes" SG_ 2155380736 PTExPrtclFltrWrn2IO 1;
BA_ "SignalType" SG_ 2155380736 PTExPrtclFltrWrn2IO "BLN";
BA_ "SignalLongName" SG_ 2155380736 PTExPrtclFltrWrn2IO "Powertrain Exhaust Particle Filter Warning 2 Indication On";
BA_ "VNSigAllNodes" SG_ 2155380736 EngOilHotIO 1;
BA_ "SignalType" SG_ 2155380736 EngOilHotIO "BLN";
BA_ "SignalLongName" SG_ 2155380736 EngOilHotIO "Engine Oil Hot Indication On";
BA_ "VNSigAllNodes" SG_ 2155380736 RrLevVDA 1;
BA_ "SignalType" SG_ 2155380736 RrLevVDA "ENM";
BA_ "SignalLongName" SG_ 2155380736 RrLevVDA "Rear Leveling Virtual Device Availability";
BA_ "GenSigStartValue" SG_ 2155380736 RrLevVDA 1;
BA_ "VNSigAllNodes" SG_ 2155380736 EngWtrInFlIO 1;
BA_ "SignalType" SG_ 2155380736 EngWtrInFlIO "BLN";
BA_ "SignalLongName" SG_ 2155380736 EngWtrInFlIO "Engine Water In Fuel Indication On";
BA_ "VNSigAllNodes" SG_ 2155380736 AdvFrntLghtSysIndRq 1;
BA_ "SignalType" SG_ 2155380736 AdvFrntLghtSysIndRq "ENM";
BA_ "SignalLongName" SG_ 2155380736 AdvFrntLghtSysIndRq "Advanced Front Lighting System Indication Request";
BA_ "VNSigAllNodes" SG_ 2155380736 PTExPrtclFltrWrnIO 1;
BA_ "SignalType" SG_ 2155380736 PTExPrtclFltrWrnIO "BLN";
BA_ "SignalLongName" SG_ 2155380736 PTExPrtclFltrWrnIO "Powertrain Exhaust Particle Filter Warning Indication On";
BA_ "VNSigAllNodes" SG_ 2155380736 AirCndOffIO 1;
BA_ "SignalType" SG_ 2155380736 AirCndOffIO "BLN";
BA_ "SignalLongName" SG_ 2155380736 AirCndOffIO "Air Conditioning Off Indication On";
BA_ "VNSigAllNodes" SG_ 2155380736 HdLtLvlFlrIO 1;
BA_ "SignalType" SG_ 2155380736 HdLtLvlFlrIO "BLN";
BA_ "SignalLongName" SG_ 2155380736 HdLtLvlFlrIO "Head Light Leveling Failure Indication On";
BA_ "GenSigSendType" SG_ 2155380736 PwrStrIO 10;
BA_ "VNSigAllNodes" SG_ 2155380736 PwrStrIO 1;
BA_ "SignalType" SG_ 2155380736 PwrStrIO "BLN";
BA_ "SignalLongName" SG_ 2155380736 PwrStrIO "Power Steering Indication On";
BA_ "VNSigAllNodes" SG_ 2155380736 EngHt_StpEngIO 1;
BA_ "SignalType" SG_ 2155380736 EngHt_StpEngIO "BLN";
BA_ "SignalLongName" SG_ 2155380736 EngHt_StpEngIO "Engine Hot / Stop Engine Indication On";
BA_ "VNSigAllNodes" SG_ 2155380736 CkFlFilrCapIO 1;
BA_ "SignalType" SG_ 2155380736 CkFlFilrCapIO "BLN";
BA_ "SignalLongName" SG_ 2155380736 CkFlFilrCapIO "Check Fuel Filler Cap Indication On";
BA_ "VNSigAllNodes" SG_ 2155380736 RdcdPwrIO 1;
BA_ "SignalType" SG_ 2155380736 RdcdPwrIO "BLN";
BA_ "SignalLongName" SG_ 2155380736 RdcdPwrIO "Reduced Power Indication On";
BA_ "VNSigAllNodes" SG_ 2155380736 EngOilPrsLwIO 1;
BA_ "SignalType" SG_ 2155380736 EngOilPrsLwIO "BLN";
BA_ "SignalLongName" SG_ 2155380736 EngOilPrsLwIO "Engine Oil Pressure Low Indication On";
BA_ "VNSigAllNodes" SG_ 2155380736 EngOilLvlLwIO 1;
BA_ "SignalType" SG_ 2155380736 EngOilLvlLwIO "BLN";
BA_ "SignalLongName" SG_ 2155380736 EngOilLvlLwIO "Engine Oil Level Low Indication On";
BA_ "VNSigAllNodes" SG_ 2155380736 EngOilChngIO 1;
BA_ "SignalType" SG_ 2155380736 EngOilChngIO "BLN";
BA_ "SignalLongName" SG_ 2155380736 EngOilChngIO "Engine Oil Change Indication On";
BA_ "VNSigAllNodes" SG_ 2155380736 EngHotFuelEnrchmntIO 1;
BA_ "SignalType" SG_ 2155380736 EngHotFuelEnrchmntIO "BLN";
BA_ "SignalLongName" SG_ 2155380736 EngHotFuelEnrchmntIO "Engine Hot Fuel Enrichment Indication On";
BA_ "GenSigSendType" SG_ 2155380736 DslGlwPlgIO 10;
BA_ "VNSigAllNodes" SG_ 2155380736 DslGlwPlgIO 1;
BA_ "SignalType" SG_ 2155380736 DslGlwPlgIO "BLN";
BA_ "SignalLongName" SG_ 2155380736 DslGlwPlgIO "Diesel Glow Plug Indication On";
BA_ "VNSigAllNodes" SG_ 2155380736 SrvLevSysIO 1;
BA_ "SignalType" SG_ 2155380736 SrvLevSysIO "BLN";
BA_ "SignalLongName" SG_ 2155380736 SrvLevSysIO "Service Leveling System Indication On";
BA_ "VNSigAllNodes" SG_ 2155380736 VehOvrLdIndOn 1;
BA_ "SignalType" SG_ 2155380736 VehOvrLdIndOn "BLN";
BA_ "SignalLongName" SG_ 2155380736 VehOvrLdIndOn "Vehicle Overloaded Indication On";
BA_ "VNSigAllNodes" SG_ 2155380736 ARSFlrIO 1;
BA_ "SignalType" SG_ 2155380736 ARSFlrIO "BLN";
BA_ "SignalLongName" SG_ 2155380736 ARSFlrIO "Active Rear Steer Failure Indication On";
BA_ "VNSigAllNodes" SG_ 2150498304 EngOilPrsV 1;
BA_ "SignalType" SG_ 2150498304 EngOilPrsV "ENM";
BA_ "SignalLongName" SG_ 2150498304 EngOilPrsV "Engine Oil Pressure Validity";
BA_ "VNSigAllNodes" SG_ 2150498304 EngOilPrs 1;
BA_ "SignalType" SG_ 2150498304 EngOilPrs "UNM";
BA_ "SignalLongName" SG_ 2150498304 EngOilPrs "Engine Oil Pressure";
BA_ "VNSigAllNodes" SG_ 2150498304 EngOilTmpV 1;
BA_ "SignalType" SG_ 2150498304 EngOilTmpV "ENM";
BA_ "SignalLongName" SG_ 2150498304 EngOilTmpV "Engine Oil Temperature Validity";
BA_ "VNSigAllNodes" SG_ 2150498304 EngOilTmp 1;
BA_ "SignalType" SG_ 2150498304 EngOilTmp "UNM";
BA_ "SignalLongName" SG_ 2150498304 EngOilTmp "Engine Oil Temperature";
BA_ "VNSigAllNodes" SG_ 2150498304 TrnOilTmpV 1;
BA_ "SignalType" SG_ 2150498304 TrnOilTmpV "ENM";
BA_ "SignalLongName" SG_ 2150498304 TrnOilTmpV "Transmission Oil Temperature Validity";
BA_ "VNSigAllNodes" SG_ 2150498304 TrnOilTmp 1;
BA_ "SignalType" SG_ 2150498304 TrnOilTmp "UNM";
BA_ "SignalLongName" SG_ 2150498304 TrnOilTmp "Transmission Oil Temperature";
BA_ "VNSigAllNodes" SG_ 2150498304 BarPrsAbsV 1;
BA_ "SignalType" SG_ 2150498304 BarPrsAbsV "ENM";
BA_ "SignalLongName" SG_ 2150498304 BarPrsAbsV "Barometric Pressure Absolute Validity";
BA_ "VNSigAllNodes" SG_ 2150498304 BarPrsAbs 1;
BA_ "SignalType" SG_ 2150498304 BarPrsAbs "UNM";
BA_ "SignalLongName" SG_ 2150498304 BarPrsAbs "Barometric Pressure Absolute";
BA_ "VNSigAllNodes" SG_ 2150498304 OAT_PT_EstV 1;
BA_ "SignalType" SG_ 2150498304 OAT_PT_EstV "ENM";
BA_ "SignalLongName" SG_ 2150498304 OAT_PT_EstV "Outside Air Temperature Powertrain Estimated Validity";
BA_ "VNSigAllNodes" SG_ 2150498304 OAT_PT_Est 1;
BA_ "SignalType" SG_ 2150498304 OAT_PT_Est "UNM";
BA_ "SignalLongName" SG_ 2150498304 OAT_PT_Est "Outside Air Temperature Powertrain Estimated";
BA_ "GenSigSendOnInit" SG_ 2150498304 EngCltTmpV 1;
BA_ "VNSigAllNodes" SG_ 2150498304 EngCltTmpV 1;
BA_ "SignalType" SG_ 2150498304 EngCltTmpV "ENM";
BA_ "SignalLongName" SG_ 2150498304 EngCltTmpV "Engine Coolant Temperature Validity";
BA_ "GenSigSendOnInit" SG_ 2150498304 EngCltTmp 1;
BA_ "VNSigAllNodes" SG_ 2150498304 EngCltTmp 1;
BA_ "SignalType" SG_ 2150498304 EngCltTmp "UNM";
BA_ "SignalLongName" SG_ 2150498304 EngCltTmp "Engine Coolant Temperature";
BA_ "VNSigAllNodes" SG_ 2150498304 EngIntAirTmpV 1;
BA_ "SignalType" SG_ 2150498304 EngIntAirTmpV "ENM";
BA_ "SignalLongName" SG_ 2150498304 EngIntAirTmpV "Engine Intake Air Temperature Validity";
BA_ "VNSigAllNodes" SG_ 2150498304 EngIntAirTmp 1;
BA_ "SignalType" SG_ 2150498304 EngIntAirTmp "UNM";
BA_ "SignalLongName" SG_ 2150498304 EngIntAirTmp "Engine Intake Air Temperature";
BA_ "VNSigAllNodes" SG_ 2150498304 OAT_PT_EstM 1;
BA_ "SignalType" SG_ 2150498304 OAT_PT_EstM "ENM";
BA_ "SignalLongName" SG_ 2150498304 OAT_PT_EstM "Outside Air Temperature Powertrain Estimated Mask";
BA_ "VNSigAllNodes" SG_ 2155331584 WhlRotStatTmstmpRes 1;
BA_ "SignalType" SG_ 2155331584 WhlRotStatTmstmpRes "UNM";
BA_ "SignalLongName" SG_ 2155331584 WhlRotStatTmstmpRes "Wheel Rotational Status Timestamp Resolution";
BA_ "VNSigAllNodes" SG_ 2155331584 WhlPlsPerRevNonDrvn 1;
BA_ "SignalType" SG_ 2155331584 WhlPlsPerRevNonDrvn "UNM";
BA_ "SignalLongName" SG_ 2155331584 WhlPlsPerRevNonDrvn "Wheel Pulses Per Revolution Non Driven";
BA_ "VNSigAllNodes" SG_ 2155331584 WhlPlsPerRevDrvn 1;
BA_ "SignalType" SG_ 2155331584 WhlPlsPerRevDrvn "UNM";
BA_ "SignalLongName" SG_ 2155331584 WhlPlsPerRevDrvn "Wheel Pulses Per Revolution Driven";
BA_ "GenSigSendType" SG_ 2153955328 ElpsdTimeCntRstOcc 10;
BA_ "VNSigAllNodes" SG_ 2153955328 ElpsdTimeCntRstOcc 1;
BA_ "SignalType" SG_ 2153955328 ElpsdTimeCntRstOcc "BLN";
BA_ "SignalLongName" SG_ 2153955328 ElpsdTimeCntRstOcc "Elapsed Time Count Reset Occurred";
BA_ "GenSigSendType" SG_ 2153955328 ElpsdTimeCnt 12;
BA_ "GenSigDeltaValue" SG_ 2153955328 ElpsdTimeCnt 1;
BA_ "VNSigAllNodes" SG_ 2153955328 ElpsdTimeCnt 1;
BA_ "SignalType" SG_ 2153955328 ElpsdTimeCnt "UNM";
BA_ "SignalLongName" SG_ 2153955328 ElpsdTimeCnt "Elapsed Time Count";
BA_ "GenSigSendType" SG_ 2153955328 EngOffTmExtRngV 10;
BA_ "VNSigAllNodes" SG_ 2153955328 EngOffTmExtRngV 1;
BA_ "SignalType" SG_ 2153955328 EngOffTmExtRngV "ENM";
BA_ "SignalLongName" SG_ 2153955328 EngOffTmExtRngV "Engine Off Time Extended Range Validity";
BA_ "GenSigSendOnInit" SG_ 2153955328 EngOffTmExtRng 2;
BA_ "GenSigSendType" SG_ 2153955328 EngOffTmExtRng 12;
BA_ "GenSigDeltaValue" SG_ 2153955328 EngOffTmExtRng 1;
BA_ "VNSigAllNodes" SG_ 2153955328 EngOffTmExtRng 1;
BA_ "SignalType" SG_ 2153955328 EngOffTmExtRng "UNM";
BA_ "SignalLongName" SG_ 2153955328 EngOffTmExtRng "Engine Off Time Extended Range";
BA_ "GenSigSendType" SG_ 2158845952 ODIAC_FUCID 12;
BA_ "GenSigDeltaValue" SG_ 2158845952 ODIAC_FUCID 1;
BA_ "VNSigAllNodes" SG_ 2158845952 ODIAC_FUCID 1;
BA_ "SignalType" SG_ 2158845952 ODIAC_FUCID "UNM";
BA_ "PacketOrder" SG_ 2158845952 ODIAC_FUCID 2;
BA_ "SignalLongName" SG_ 2158845952 ODIAC_FUCID "Open Display Interface Action CenterStack : FU Class ID";
BA_ "GenSigSendType" SG_ 2158845952 ODIAC_DspMID 10;
BA_ "VNSigAllNodes" SG_ 2158845952 ODIAC_DspMID 1;
BA_ "SignalType" SG_ 2158845952 ODIAC_DspMID "ENM";
BA_ "PacketOrder" SG_ 2158845952 ODIAC_DspMID 4;
BA_ "SignalLongName" SG_ 2158845952 ODIAC_DspMID "Open Display Interface Action CenterStack : Display Mask ID";
BA_ "GenSigSendType" SG_ 2158845952 ODIAC_DaTy 10;
BA_ "GenSigDeltaValue" SG_ 2158845952 ODIAC_DaTy 1;
BA_ "VNSigAllNodes" SG_ 2158845952 ODIAC_DaTy 1;
BA_ "SignalType" SG_ 2158845952 ODIAC_DaTy "ENM";
BA_ "PacketOrder" SG_ 2158845952 ODIAC_DaTy 1;
BA_ "SignalLongName" SG_ 2158845952 ODIAC_DaTy "Open Display Interface Action CenterStack : DataType";
BA_ "GenSigSendType" SG_ 2158845952 ODIAC_ActnVal 12;
BA_ "GenSigDeltaValue" SG_ 2158845952 ODIAC_ActnVal 1;
BA_ "VNSigAllNodes" SG_ 2158845952 ODIAC_ActnVal 1;
BA_ "SignalType" SG_ 2158845952 ODIAC_ActnVal "UNM";
BA_ "PacketOrder" SG_ 2158845952 ODIAC_ActnVal 5;
BA_ "SignalLongName" SG_ 2158845952 ODIAC_ActnVal "Open Display Interface Action CenterStack : Action Value";
BA_ "GenSigSendType" SG_ 2158845952 ODIAC_ActnID 12;
BA_ "GenSigDeltaValue" SG_ 2158845952 ODIAC_ActnID 1;
BA_ "VNSigAllNodes" SG_ 2158845952 ODIAC_ActnID 1;
BA_ "SignalType" SG_ 2158845952 ODIAC_ActnID "UNM";
BA_ "PacketOrder" SG_ 2158845952 ODIAC_ActnID 3;
BA_ "SignalLongName" SG_ 2158845952 ODIAC_ActnID "Open Display Interface Action CenterStack : Action ID";
BA_ "GenSigSendType" SG_ 2151366656 AxlLckUnavailIndReq 10;
BA_ "VNSigAllNodes" SG_ 2151366656 AxlLckUnavailIndReq 1;
BA_ "SignalType" SG_ 2151366656 AxlLckUnavailIndReq "ENM";
BA_ "SignalLongName" SG_ 2151366656 AxlLckUnavailIndReq "Axle Locks Unavailable Indication Request";
BA_ "GenSigSendType" SG_ 2151366656 AxlLcksServIO 10;
BA_ "VNSigAllNodes" SG_ 2151366656 AxlLcksServIO 1;
BA_ "SignalType" SG_ 2151366656 AxlLcksServIO "BLN";
BA_ "SignalLongName" SG_ 2151366656 AxlLcksServIO "Axle Locks Service Indication On";
BA_ "GenSigSendType" SG_ 2151366656 RrAxlLckIO 10;
BA_ "VNSigAllNodes" SG_ 2151366656 RrAxlLckIO 1;
BA_ "SignalType" SG_ 2151366656 RrAxlLckIO "BLN";
BA_ "SignalLongName" SG_ 2151366656 RrAxlLckIO "Rear Axle Lock Indication On";
BA_ "GenSigSendType" SG_ 2151366656 FrntAxlLckIO 10;
BA_ "VNSigAllNodes" SG_ 2151366656 FrntAxlLckIO 1;
BA_ "SignalType" SG_ 2151366656 FrntAxlLckIO "BLN";
BA_ "SignalLongName" SG_ 2151366656 FrntAxlLckIO "Front Axle Lock Indication On";
BA_ "GenSigSendType" SG_ 2151366656 AxlLcksVDA 10;
BA_ "VNSigAllNodes" SG_ 2151366656 AxlLcksVDA 1;
BA_ "SignalType" SG_ 2151366656 AxlLcksVDA "ENM";
BA_ "SignalLongName" SG_ 2151366656 AxlLcksVDA "Axle Locks Virtual Device Availability";
BA_ "GenSigStartValue" SG_ 2151366656 AxlLcksVDA 1;
BA_ "GenSigSendOnInit" SG_ 2151366656 PrkBrkSwAtv 1;
BA_ "GenSigSendType" SG_ 2151366656 PrkBrkSwAtv 10;
BA_ "VNSigAllNodes" SG_ 2151366656 PrkBrkSwAtv 1;
BA_ "SignalType" SG_ 2151366656 PrkBrkSwAtv "BLN";
BA_ "SignalLongName" SG_ 2151366656 PrkBrkSwAtv "Park Brake Switch Active";
BA_ "VNSigAllNodes" SG_ 2149842944 AdptDrvrSeatStng 1;
BA_ "SignalType" SG_ 2149842944 AdptDrvrSeatStng "ENM";
BA_ "SignalLongName" SG_ 2149842944 AdptDrvrSeatStng "Adaptive Driver Seat Setting";
BA_ "VNSigAllNodes" SG_ 2149842944 VSELatAccV 1;
BA_ "SignalType" SG_ 2149842944 VSELatAccV "ENM";
BA_ "SignalLongName" SG_ 2149842944 VSELatAccV "Vehicle Stability Enhancement Lateral Acceleration Validity";
BA_ "VNSigAllNodes" SG_ 2149842944 VSELatAcc 1;
BA_ "SignalType" SG_ 2149842944 VSELatAcc "SNM";
BA_ "SignalLongName" SG_ 2149842944 VSELatAcc "Vehicle Stability Enhancement Lateral Acceleration";
BA_ "VNSigAllNodes" SG_ 2149842944 BrkSysAutBrkFld 1;
BA_ "SignalType" SG_ 2149842944 BrkSysAutBrkFld "BLN";
BA_ "SignalLongName" SG_ 2149842944 BrkSysAutBrkFld "Brake System Automatic Braking Failed";
BA_ "VNSigAllNodes" SG_ 2149842944 VehStabEnhmntMd 1;
BA_ "SignalType" SG_ 2149842944 VehStabEnhmntMd "ENM";
BA_ "SignalLongName" SG_ 2149842944 VehStabEnhmntMd "Vehicle Stability Enhancement Mode";
BA_ "VNSigAllNodes" SG_ 2149842944 TCSysOpMd 1;
BA_ "SignalType" SG_ 2149842944 TCSysOpMd "ENM";
BA_ "SignalLongName" SG_ 2149842944 TCSysOpMd "Traction Control System Operating Mode";
BA_ "VNSigAllNodes" SG_ 2149842944 IMUProtLonAccV 1;
BA_ "SignalType" SG_ 2149842944 IMUProtLonAccV "ENM";
BA_ "SignalLongName" SG_ 2149842944 IMUProtLonAccV "Inertial Measurement Unit Protected Longitudinal Acceleration Validity";
BA_ "VNSigAllNodes" SG_ 2149842944 IMUProtLonAcc 1;
BA_ "SignalType" SG_ 2149842944 IMUProtLonAcc "SNM";
BA_ "SignalLongName" SG_ 2149842944 IMUProtLonAcc "Inertial Measurement Unit Protected Longitudinal Acceleration";
BA_ "VNSigAllNodes" SG_ 2149842944 StrWhAngV 1;
BA_ "SignalType" SG_ 2149842944 StrWhAngV "ENM";
BA_ "SignalLongName" SG_ 2149842944 StrWhAngV "Steering Wheel Angle Validity";
BA_ "VNSigAllNodes" SG_ 2149842944 TCSysAtv 1;
BA_ "SignalType" SG_ 2149842944 TCSysAtv "BLN";
BA_ "SignalLongName" SG_ 2149842944 TCSysAtv "Traction Control System Active";
BA_ "VNSigAllNodes" SG_ 2149842944 StrWhlAngSenCalStat 1;
BA_ "SignalType" SG_ 2149842944 StrWhlAngSenCalStat "ENM";
BA_ "SignalLongName" SG_ 2149842944 StrWhlAngSenCalStat "Steering Wheel Angle Sensor Calibration Status";
BA_ "VNSigAllNodes" SG_ 2149842944 VehStabEnhmntStat 1;
BA_ "SignalType" SG_ 2149842944 VehStabEnhmntStat "ENM";
BA_ "SignalLongName" SG_ 2149842944 VehStabEnhmntStat "Vehicle Stability Enhancement Status";
BA_ "VNSigAllNodes" SG_ 2149842944 VSEAct 1;
BA_ "SignalType" SG_ 2149842944 VSEAct "BLN";
BA_ "SignalLongName" SG_ 2149842944 VSEAct "Vehicle Stability Enhancement System Active";
BA_ "VNSigAllNodes" SG_ 2149842944 TCSysOpStat 1;
BA_ "SignalType" SG_ 2149842944 TCSysOpStat "ENM";
BA_ "SignalLongName" SG_ 2149842944 TCSysOpStat "Traction Control System Operating Status";
BA_ "VNSigAllNodes" SG_ 2149842944 StWhAnVDA 1;
BA_ "SignalType" SG_ 2149842944 StWhAnVDA "ENM";
BA_ "SignalLongName" SG_ 2149842944 StWhAnVDA "Steering Wheel Angle Virtual Device Availability";
BA_ "GenSigStartValue" SG_ 2149842944 StWhAnVDA 1;
BA_ "VNSigAllNodes" SG_ 2149842944 StrWhAng 1;
BA_ "SignalType" SG_ 2149842944 StrWhAng "SNM";
BA_ "SignalLongName" SG_ 2149842944 StrWhAng "Steering Wheel Angle";
BA_ "VNSigAllNodes" SG_ 2154528768 WhlGrndVlctyRtNnDrvnV 1;
BA_ "SignalType" SG_ 2154528768 WhlGrndVlctyRtNnDrvnV "ENM";
BA_ "SignalLongName" SG_ 2154528768 WhlGrndVlctyRtNnDrvnV "Wheel Ground Velocity Right Non Driven Validity";
BA_ "VNSigAllNodes" SG_ 2154528768 WhlGrndVlctyRtNnDrvn 1;
BA_ "SignalType" SG_ 2154528768 WhlGrndVlctyRtNnDrvn "UNM";
BA_ "SignalLongName" SG_ 2154528768 WhlGrndVlctyRtNnDrvn "Wheel Ground Velocity Right Non Driven";
BA_ "VNSigAllNodes" SG_ 2154528768 WhlGrndVlctyRtDrvnV 1;
BA_ "SignalType" SG_ 2154528768 WhlGrndVlctyRtDrvnV "ENM";
BA_ "SignalLongName" SG_ 2154528768 WhlGrndVlctyRtDrvnV "Wheel Ground Velocity Right Driven Validity";
BA_ "VNSigAllNodes" SG_ 2154528768 WhlGrndVlctyRtDrvn 1;
BA_ "SignalType" SG_ 2154528768 WhlGrndVlctyRtDrvn "UNM";
BA_ "SignalLongName" SG_ 2154528768 WhlGrndVlctyRtDrvn "Wheel Ground Velocity Right Driven";
BA_ "VNSigAllNodes" SG_ 2154528768 WhlGrndVlctyLftNnDrvnV 1;
BA_ "SignalType" SG_ 2154528768 WhlGrndVlctyLftNnDrvnV "ENM";
BA_ "SignalLongName" SG_ 2154528768 WhlGrndVlctyLftNnDrvnV "Wheel Ground Velocity Left Non Driven Validity";
BA_ "VNSigAllNodes" SG_ 2154528768 WhlGrndVlctyLftNnDrvn 1;
BA_ "SignalType" SG_ 2154528768 WhlGrndVlctyLftNnDrvn "UNM";
BA_ "SignalLongName" SG_ 2154528768 WhlGrndVlctyLftNnDrvn "Wheel Ground Velocity Left Non Driven";
BA_ "VNSigAllNodes" SG_ 2154528768 WhlGrndVlctyLftDrvnV 1;
BA_ "SignalType" SG_ 2154528768 WhlGrndVlctyLftDrvnV "ENM";
BA_ "SignalLongName" SG_ 2154528768 WhlGrndVlctyLftDrvnV "Wheel Ground Velocity Left Driven Validity";
BA_ "VNSigAllNodes" SG_ 2154528768 WhlGrndVlctyLftDrvn 1;
BA_ "SignalType" SG_ 2154528768 WhlGrndVlctyLftDrvn "UNM";
BA_ "SignalLongName" SG_ 2154528768 WhlGrndVlctyLftDrvn "Wheel Ground Velocity Left Driven";
BA_ "VNSigAllNodes" SG_ 2149777408 WRSLNDWhlDisTpRC 1;
BA_ "SignalType" SG_ 2149777408 WRSLNDWhlDisTpRC "UNM";
BA_ "PacketOrder" SG_ 2149777408 WRSLNDWhlDisTpRC 1;
BA_ "SignalLongName" SG_ 2149777408 WRSLNDWhlDisTpRC "Wheel Rotational Status Left Non Driven : Wheel Distance Timestamp Rollover Counter";
BA_ "VNSigAllNodes" SG_ 2149777408 WRSLNDWhlRotStRst 1;
BA_ "SignalType" SG_ 2149777408 WRSLNDWhlRotStRst "BLN";
BA_ "PacketOrder" SG_ 2149777408 WRSLNDWhlRotStRst 3;
BA_ "SignalLongName" SG_ 2149777408 WRSLNDWhlRotStRst "Wheel Rotational Status Left Non Driven : Wheel Rotational Status Reset Occurred";
BA_ "VNSigAllNodes" SG_ 2149777408 WRSLNDWhlDistVal 1;
BA_ "SignalType" SG_ 2149777408 WRSLNDWhlDistVal "ENM";
BA_ "PacketOrder" SG_ 2149777408 WRSLNDWhlDistVal 4;
BA_ "SignalLongName" SG_ 2149777408 WRSLNDWhlDistVal "Wheel Rotational Status Left Non Driven : Wheel Distance Validity";
BA_ "VNSigAllNodes" SG_ 2149777408 WRSLNDWhlDistTstm 1;
BA_ "SignalType" SG_ 2149777408 WRSLNDWhlDistTstm "UNM";
BA_ "PacketOrder" SG_ 2149777408 WRSLNDWhlDistTstm 6;
BA_ "SignalLongName" SG_ 2149777408 WRSLNDWhlDistTstm "Wheel Rotational Status Left Non Driven : Wheel Distance Timestamp";
BA_ "VNSigAllNodes" SG_ 2149777408 WRSLNDWhlDistPCntr 1;
BA_ "SignalType" SG_ 2149777408 WRSLNDWhlDistPCntr "UNM";
BA_ "PacketOrder" SG_ 2149777408 WRSLNDWhlDistPCntr 5;
BA_ "SignalLongName" SG_ 2149777408 WRSLNDWhlDistPCntr "Wheel Rotational Status Left Non Driven : Wheel Distance Pulse Counter";
BA_ "VNSigAllNodes" SG_ 2149777408 WRSLNDSeqNum 1;
BA_ "SignalType" SG_ 2149777408 WRSLNDSeqNum "UNM";
BA_ "PacketOrder" SG_ 2149777408 WRSLNDSeqNum 2;
BA_ "SignalLongName" SG_ 2149777408 WRSLNDSeqNum "Wheel Rotational Status Left Non Driven : Sequence Number";
BA_ "VNSigAllNodes" SG_ 2149777408 WRSRNDWhlDisTpRC 1;
BA_ "SignalType" SG_ 2149777408 WRSRNDWhlDisTpRC "UNM";
BA_ "PacketOrder" SG_ 2149777408 WRSRNDWhlDisTpRC 1;
BA_ "SignalLongName" SG_ 2149777408 WRSRNDWhlDisTpRC "Wheel Rotational Status Right Non Driven : Wheel Distance Timestamp Rollover Counter";
BA_ "VNSigAllNodes" SG_ 2149777408 WRSRNDWhlRotStRst 1;
BA_ "SignalType" SG_ 2149777408 WRSRNDWhlRotStRst "BLN";
BA_ "PacketOrder" SG_ 2149777408 WRSRNDWhlRotStRst 3;
BA_ "SignalLongName" SG_ 2149777408 WRSRNDWhlRotStRst "Wheel Rotational Status Right Non Driven : Wheel Rotational Status Reset Occurred";
BA_ "VNSigAllNodes" SG_ 2149777408 WRSRNDWhlDistVal 1;
BA_ "SignalType" SG_ 2149777408 WRSRNDWhlDistVal "ENM";
BA_ "PacketOrder" SG_ 2149777408 WRSRNDWhlDistVal 4;
BA_ "SignalLongName" SG_ 2149777408 WRSRNDWhlDistVal "Wheel Rotational Status Right Non Driven : Wheel Distance Validity";
BA_ "VNSigAllNodes" SG_ 2149777408 WRSRNDWhlDistTstm 1;
BA_ "SignalType" SG_ 2149777408 WRSRNDWhlDistTstm "UNM";
BA_ "PacketOrder" SG_ 2149777408 WRSRNDWhlDistTstm 6;
BA_ "SignalLongName" SG_ 2149777408 WRSRNDWhlDistTstm "Wheel Rotational Status Right Non Driven : Wheel Distance Timestamp";
BA_ "VNSigAllNodes" SG_ 2149777408 WRSRNDWhlDistPCntr 1;
BA_ "SignalType" SG_ 2149777408 WRSRNDWhlDistPCntr "UNM";
BA_ "PacketOrder" SG_ 2149777408 WRSRNDWhlDistPCntr 5;
BA_ "SignalLongName" SG_ 2149777408 WRSRNDWhlDistPCntr "Wheel Rotational Status Right Non Driven : Wheel Distance Pulse Counter";
BA_ "VNSigAllNodes" SG_ 2149777408 WRSRNDSeqNum 1;
BA_ "SignalType" SG_ 2149777408 WRSRNDSeqNum "UNM";
BA_ "PacketOrder" SG_ 2149777408 WRSRNDSeqNum 2;
BA_ "SignalLongName" SG_ 2149777408 WRSRNDSeqNum "Wheel Rotational Status Right Non Driven : Sequence Number";
BA_ "GenSigSendType" SG_ 2149769216 WRSLDWhlDisTpRC 12;
BA_ "GenSigDeltaValue" SG_ 2149769216 WRSLDWhlDisTpRC 1;
BA_ "VNSigAllNodes" SG_ 2149769216 WRSLDWhlDisTpRC 1;
BA_ "SignalType" SG_ 2149769216 WRSLDWhlDisTpRC "UNM";
BA_ "PacketOrder" SG_ 2149769216 WRSLDWhlDisTpRC 1;
BA_ "SignalLongName" SG_ 2149769216 WRSLDWhlDisTpRC "Wheel Rotational Status Left Driven : Wheel Distance Timestamp Rollover Counter";
BA_ "GenSigSendType" SG_ 2149769216 WRSLDSeqNum 12;
BA_ "GenSigDeltaValue" SG_ 2149769216 WRSLDSeqNum 1;
BA_ "VNSigAllNodes" SG_ 2149769216 WRSLDSeqNum 1;
BA_ "SignalType" SG_ 2149769216 WRSLDSeqNum "UNM";
BA_ "PacketOrder" SG_ 2149769216 WRSLDSeqNum 2;
BA_ "SignalLongName" SG_ 2149769216 WRSLDSeqNum "Wheel Rotational Status Left Driven : Sequence Number";
BA_ "GenSigSendType" SG_ 2149769216 WRSLDWhlDistVal 10;
BA_ "VNSigAllNodes" SG_ 2149769216 WRSLDWhlDistVal 1;
BA_ "SignalType" SG_ 2149769216 WRSLDWhlDistVal "ENM";
BA_ "PacketOrder" SG_ 2149769216 WRSLDWhlDistVal 4;
BA_ "SignalLongName" SG_ 2149769216 WRSLDWhlDistVal "Wheel Rotational Status Left Driven : Wheel Distance Validity";
BA_ "GenSigSendType" SG_ 2149769216 WRSLDWhlRotStatRst 10;
BA_ "VNSigAllNodes" SG_ 2149769216 WRSLDWhlRotStatRst 1;
BA_ "SignalType" SG_ 2149769216 WRSLDWhlRotStatRst "BLN";
BA_ "PacketOrder" SG_ 2149769216 WRSLDWhlRotStatRst 3;
BA_ "SignalLongName" SG_ 2149769216 WRSLDWhlRotStatRst "Wheel Rotational Status Left Driven : Wheel Rotational Status Reset Occurred";
BA_ "GenSigSendType" SG_ 2149769216 WRSLDWhlDistTmstm 12;
BA_ "GenSigDeltaValue" SG_ 2149769216 WRSLDWhlDistTmstm 1;
BA_ "VNSigAllNodes" SG_ 2149769216 WRSLDWhlDistTmstm 1;
BA_ "SignalType" SG_ 2149769216 WRSLDWhlDistTmstm "UNM";
BA_ "PacketOrder" SG_ 2149769216 WRSLDWhlDistTmstm 6;
BA_ "SignalLongName" SG_ 2149769216 WRSLDWhlDistTmstm "Wheel Rotational Status Left Driven : Wheel Distance Timestamp";
BA_ "GenSigSendType" SG_ 2149769216 WRSLDWhlDistPlsCntr 12;
BA_ "GenSigDeltaValue" SG_ 2149769216 WRSLDWhlDistPlsCntr 1;
BA_ "VNSigAllNodes" SG_ 2149769216 WRSLDWhlDistPlsCntr 1;
BA_ "SignalType" SG_ 2149769216 WRSLDWhlDistPlsCntr "UNM";
BA_ "PacketOrder" SG_ 2149769216 WRSLDWhlDistPlsCntr 5;
BA_ "SignalLongName" SG_ 2149769216 WRSLDWhlDistPlsCntr "Wheel Rotational Status Left Driven : Wheel Distance Pulse Counter";
BA_ "GenSigSendType" SG_ 2149769216 WRSRDWhlDisTpRC 12;
BA_ "GenSigDeltaValue" SG_ 2149769216 WRSRDWhlDisTpRC 1;
BA_ "VNSigAllNodes" SG_ 2149769216 WRSRDWhlDisTpRC 1;
BA_ "SignalType" SG_ 2149769216 WRSRDWhlDisTpRC "UNM";
BA_ "PacketOrder" SG_ 2149769216 WRSRDWhlDisTpRC 1;
BA_ "SignalLongName" SG_ 2149769216 WRSRDWhlDisTpRC "Wheel Rotational Status Right Driven : Wheel Distance Timestamp Rollover Counter";
BA_ "GenSigSendType" SG_ 2149769216 WRSRDSeqNum 12;
BA_ "GenSigDeltaValue" SG_ 2149769216 WRSRDSeqNum 1;
BA_ "VNSigAllNodes" SG_ 2149769216 WRSRDSeqNum 1;
BA_ "SignalType" SG_ 2149769216 WRSRDSeqNum "UNM";
BA_ "PacketOrder" SG_ 2149769216 WRSRDSeqNum 2;
BA_ "SignalLongName" SG_ 2149769216 WRSRDSeqNum "Wheel Rotational Status Right Driven : Sequence Number";
BA_ "GenSigSendType" SG_ 2149769216 WRSRDWhlRotStatRst 10;
BA_ "VNSigAllNodes" SG_ 2149769216 WRSRDWhlRotStatRst 1;
BA_ "SignalType" SG_ 2149769216 WRSRDWhlRotStatRst "BLN";
BA_ "PacketOrder" SG_ 2149769216 WRSRDWhlRotStatRst 3;
BA_ "SignalLongName" SG_ 2149769216 WRSRDWhlRotStatRst "Wheel Rotational Status Right Driven : Wheel Rotational Status Reset Occurred";
BA_ "GenSigSendType" SG_ 2149769216 WRSRDWhlDistVal 10;
BA_ "VNSigAllNodes" SG_ 2149769216 WRSRDWhlDistVal 1;
BA_ "SignalType" SG_ 2149769216 WRSRDWhlDistVal "ENM";
BA_ "PacketOrder" SG_ 2149769216 WRSRDWhlDistVal 4;
BA_ "SignalLongName" SG_ 2149769216 WRSRDWhlDistVal "Wheel Rotational Status Right Driven : Wheel Distance Validity";
BA_ "GenSigSendType" SG_ 2149769216 WRSRDWhlDistTmstm 12;
BA_ "GenSigDeltaValue" SG_ 2149769216 WRSRDWhlDistTmstm 1;
BA_ "VNSigAllNodes" SG_ 2149769216 WRSRDWhlDistTmstm 1;
BA_ "SignalType" SG_ 2149769216 WRSRDWhlDistTmstm "UNM";
BA_ "PacketOrder" SG_ 2149769216 WRSRDWhlDistTmstm 6;
BA_ "SignalLongName" SG_ 2149769216 WRSRDWhlDistTmstm "Wheel Rotational Status Right Driven : Wheel Distance Timestamp";
BA_ "GenSigSendType" SG_ 2149769216 WRSRDWhlDistPlsCntr 12;
BA_ "GenSigDeltaValue" SG_ 2149769216 WRSRDWhlDistPlsCntr 1;
BA_ "VNSigAllNodes" SG_ 2149769216 WRSRDWhlDistPlsCntr 1;
BA_ "SignalType" SG_ 2149769216 WRSRDWhlDistPlsCntr "UNM";
BA_ "PacketOrder" SG_ 2149769216 WRSRDWhlDistPlsCntr 5;
BA_ "SignalLongName" SG_ 2149769216 WRSRDWhlDistPlsCntr "Wheel Rotational Status Right Driven : Wheel Distance Pulse Counter";
BA_ "VNSigAllNodes" SG_ 2149752832 SndEnhcmtPerfMdRq 1;
BA_ "SignalType" SG_ 2149752832 SndEnhcmtPerfMdRq "ENM";
BA_ "SignalLongName" SG_ 2149752832 SndEnhcmtPerfMdRq "Sound Enhancement Performance Mode Request";
BA_ "VNSigAllNodes" SG_ 2149752832 SndPerfMdCsStAvl 1;
BA_ "SignalType" SG_ 2149752832 SndPerfMdCsStAvl "BLN";
BA_ "SignalLongName" SG_ 2149752832 SndPerfMdCsStAvl "Sound Performance Mode Customization Setting Available";
BA_ "VNSigAllNodes" SG_ 2149752832 SndPerfMdCsCrStVal 1;
BA_ "SignalType" SG_ 2149752832 SndPerfMdCsCrStVal "ENM";
BA_ "SignalLongName" SG_ 2149752832 SndPerfMdCsCrStVal "Sound Performance Mode Customization Current Setting Value";
BA_ "VNSigAllNodes" SG_ 2149752832 DispPerfMdCsStAvl 1;
BA_ "SignalType" SG_ 2149752832 DispPerfMdCsStAvl "BLN";
BA_ "SignalLongName" SG_ 2149752832 DispPerfMdCsStAvl "Display Performance Mode Customization Setting Available";
BA_ "VNSigAllNodes" SG_ 2149752832 DispPerfMdCsCrStVal 1;
BA_ "SignalType" SG_ 2149752832 DispPerfMdCsCrStVal "ENM";
BA_ "SignalLongName" SG_ 2149752832 DispPerfMdCsCrStVal "Display Performance Mode Customization Current Setting Value";
BA_ "VNSigAllNodes" SG_ 2149752832 HlStrAssActIO 1;
BA_ "SignalType" SG_ 2149752832 HlStrAssActIO "BLN";
BA_ "SignalLongName" SG_ 2149752832 HlStrAssActIO "Hill Start Assist Active Indication On";
BA_ "VNSigAllNodes" SG_ 2149752832 GNCustSetngAvlbl 1;
BA_ "SignalType" SG_ 2149752832 GNCustSetngAvlbl "BLN";
BA_ "SignalLongName" SG_ 2149752832 GNCustSetngAvlbl "Go Notifier Customization Setting Available";
BA_ "VNSigAllNodes" SG_ 2149752832 GNCustCrntStngVal 1;
BA_ "SignalType" SG_ 2149752832 GNCustCrntStngVal "ENM";
BA_ "SignalLongName" SG_ 2149752832 GNCustCrntStngVal "Go Notifier Customization Current Setting Value";
BA_ "VNSigAllNodes" SG_ 2149752832 CPSInfotmntMtReq 1;
BA_ "SignalType" SG_ 2149752832 CPSInfotmntMtReq "ENM";
BA_ "SignalLongName" SG_ 2149752832 CPSInfotmntMtReq "Collision Preparation System Infotainment Mute Request";
BA_ "VNSigAllNodes" SG_ 2149752832 ColPrSysStngAvl 1;
BA_ "SignalType" SG_ 2149752832 ColPrSysStngAvl "BLN";
BA_ "SignalLongName" SG_ 2149752832 ColPrSysStngAvl "Collision Preparation System Setting Available";
BA_ "VNSigAllNodes" SG_ 2149752832 ColPrSysCrntStng 1;
BA_ "SignalType" SG_ 2149752832 ColPrSysCrntStng "ENM";
BA_ "SignalLongName" SG_ 2149752832 ColPrSysCrntStng "Collision Preparation System Current Setting Value";
BA_ "VNSigAllNodes" SG_ 2149752832 HillDscntCntlSysStat 1;
BA_ "SignalType" SG_ 2149752832 HillDscntCntlSysStat "ENM";
BA_ "SignalLongName" SG_ 2149752832 HillDscntCntlSysStat "Hill Descent Control System Status";
BA_ "VNSigAllNodes" SG_ 2149752832 EBDFailed 1;
BA_ "SignalType" SG_ 2149752832 EBDFailed "BLN";
BA_ "SignalLongName" SG_ 2149752832 EBDFailed "Electronic Brake Distribution Failed";
BA_ "VNSigAllNodes" SG_ 2149752832 SusCustStngAvlbl 1;
BA_ "SignalType" SG_ 2149752832 SusCustStngAvlbl "BLN";
BA_ "SignalLongName" SG_ 2149752832 SusCustStngAvlbl "Suspension Customization Setting Available";
BA_ "VNSigAllNodes" SG_ 2149752832 SusCustCurrStngVal 1;
BA_ "SignalType" SG_ 2149752832 SusCustCurrStngVal "ENM";
BA_ "SignalLongName" SG_ 2149752832 SusCustCurrStngVal "Suspension Customization Current Setting Value";
BA_ "VNSigAllNodes" SG_ 2149752832 StrCustStngAvlbl 1;
BA_ "SignalType" SG_ 2149752832 StrCustStngAvlbl "BLN";
BA_ "SignalLongName" SG_ 2149752832 StrCustStngAvlbl "Steering Customization Setting Available";
BA_ "VNSigAllNodes" SG_ 2149752832 StrCustCurrStngVal 1;
BA_ "SignalType" SG_ 2149752832 StrCustCurrStngVal "ENM";
BA_ "SignalLongName" SG_ 2149752832 StrCustCurrStngVal "Steering Customization Current Setting Value";
BA_ "VNSigAllNodes" SG_ 2149752832 DrvlnCustStngAvlbl 1;
BA_ "SignalType" SG_ 2149752832 DrvlnCustStngAvlbl "BLN";
BA_ "SignalLongName" SG_ 2149752832 DrvlnCustStngAvlbl "Driveline Customization Setting Available";
BA_ "VNSigAllNodes" SG_ 2149752832 DrvlnCustCurrStngVal 1;
BA_ "SignalType" SG_ 2149752832 DrvlnCustCurrStngVal "ENM";
BA_ "SignalLongName" SG_ 2149752832 DrvlnCustCurrStngVal "Driveline Customization Current Setting Value";
BA_ "VNSigAllNodes" SG_ 2149752832 PowStVDA 1;
BA_ "SignalType" SG_ 2149752832 PowStVDA "ENM";
BA_ "SignalLongName" SG_ 2149752832 PowStVDA "Power Steering Virtual Device Availability";
BA_ "GenSigStartValue" SG_ 2149752832 PowStVDA 1;
BA_ "VNSigAllNodes" SG_ 2149752832 RrDrCntVDA 1;
BA_ "SignalType" SG_ 2149752832 RrDrCntVDA "ENM";
BA_ "SignalLongName" SG_ 2149752832 RrDrCntVDA "Rear Drive Control Virtual Device Availability";
BA_ "GenSigStartValue" SG_ 2149752832 RrDrCntVDA 1;
BA_ "VNSigAllNodes" SG_ 2149752832 VehHghtStatV 1;
BA_ "SignalType" SG_ 2149752832 VehHghtStatV "ENM";
BA_ "SignalLongName" SG_ 2149752832 VehHghtStatV "Vehicle Height Status Validity";
BA_ "VNSigAllNodes" SG_ 2149752832 VehHghtStat 1;
BA_ "SignalType" SG_ 2149752832 VehHghtStat "ENM";
BA_ "SignalLongName" SG_ 2149752832 VehHghtStat "Vehicle Height Status";
BA_ "VNSigAllNodes" SG_ 2149752832 IntBrkAssPreFilReq 1;
BA_ "SignalType" SG_ 2149752832 IntBrkAssPreFilReq "BLN";
BA_ "SignalLongName" SG_ 2149752832 IntBrkAssPreFilReq "Inteligent Brake Assist Pre-Fil Request";
BA_ "VNSigAllNodes" SG_ 2149752832 EPBSysDspMsgReq 1;
BA_ "SignalType" SG_ 2149752832 EPBSysDspMsgReq "ENM";
BA_ "SignalLongName" SG_ 2149752832 EPBSysDspMsgReq "Electric Park Brake System Display Message Request";
BA_ "VNSigAllNodes" SG_ 2149752832 EPBSysAudWarnReq 1;
BA_ "SignalType" SG_ 2149752832 EPBSysAudWarnReq "ENM";
BA_ "SignalLongName" SG_ 2149752832 EPBSysAudWarnReq "Electric Park Brake System Audible Warning Request";
BA_ "VNSigAllNodes" SG_ 2149752832 BksOvht 1;
BA_ "SignalType" SG_ 2149752832 BksOvht "BLN";
BA_ "SignalLongName" SG_ 2149752832 BksOvht "Brakes Overheated";
BA_ "VNSigAllNodes" SG_ 2149752832 BrkSysRedBrkTlltlReq 1;
BA_ "SignalType" SG_ 2149752832 BrkSysRedBrkTlltlReq "BLN";
BA_ "SignalLongName" SG_ 2149752832 BrkSysRedBrkTlltlReq "Brake System Red Brake Telltale Request";
BA_ "VNSigAllNodes" SG_ 2149752832 HalfSysFail 1;
BA_ "SignalType" SG_ 2149752832 HalfSysFail "BLN";
BA_ "SignalLongName" SG_ 2149752832 HalfSysFail "Half System Failure";
BA_ "VNSigAllNodes" SG_ 2149752832 ElecPrkBrkStat 1;
BA_ "SignalType" SG_ 2149752832 ElecPrkBrkStat "ENM";
BA_ "SignalLongName" SG_ 2149752832 ElecPrkBrkStat "Electric Park Brake Status";
BA_ "VNSigAllNodes" SG_ 2149752832 ABSAtv 1;
BA_ "SignalType" SG_ 2149752832 ABSAtv "BLN";
BA_ "SignalLongName" SG_ 2149752832 ABSAtv "Antilock Brake System Active";
BA_ "VNSigAllNodes" SG_ 2149752832 SprTireSt 1;
BA_ "SignalType" SG_ 2149752832 SprTireSt "ENM";
BA_ "SignalLongName" SG_ 2149752832 SprTireSt "Spare Tire Status";
BA_ "VNSigAllNodes" SG_ 2149752832 BrkSysVDA 1;
BA_ "SignalType" SG_ 2149752832 BrkSysVDA "ENM";
BA_ "SignalLongName" SG_ 2149752832 BrkSysVDA "Brake System Virtual Device Availability";
BA_ "GenSigStartValue" SG_ 2149752832 BrkSysVDA 1;
BA_ "GenSigSendType" SG_ 2149752832 PrkBrkVDA 10;
BA_ "VNSigAllNodes" SG_ 2149752832 PrkBrkVDA 1;
BA_ "SignalType" SG_ 2149752832 PrkBrkVDA "ENM";
BA_ "SignalLongName" SG_ 2149752832 PrkBrkVDA "Park Brake Virtual Device Availability";
BA_ "GenSigStartValue" SG_ 2149752832 PrkBrkVDA 1;
BA_ "GenSigSendOnInit" SG_ 2152775680 RPDCA_Resrv3Avail 2;
BA_ "GenSigSendType" SG_ 2152775680 RPDCA_Resrv3Avail 10;
BA_ "VNSigAllNodes" SG_ 2152775680 RPDCA_Resrv3Avail 1;
BA_ "SignalType" SG_ 2152775680 RPDCA_Resrv3Avail "BLN";
BA_ "PacketOrder" SG_ 2152775680 RPDCA_Resrv3Avail 7;
BA_ "SignalLongName" SG_ 2152775680 RPDCA_Resrv3Avail "Rear Pedestrian Detection Customization Available : Reserved3 Available";
BA_ "GenSigSendOnInit" SG_ 2152775680 RPDCA_Resrv2Avail 2;
BA_ "GenSigSendType" SG_ 2152775680 RPDCA_Resrv2Avail 10;
BA_ "VNSigAllNodes" SG_ 2152775680 RPDCA_Resrv2Avail 1;
BA_ "SignalType" SG_ 2152775680 RPDCA_Resrv2Avail "BLN";
BA_ "PacketOrder" SG_ 2152775680 RPDCA_Resrv2Avail 6;
BA_ "SignalLongName" SG_ 2152775680 RPDCA_Resrv2Avail "Rear Pedestrian Detection Customization Available : Reserved2 Available";
BA_ "GenSigSendOnInit" SG_ 2152775680 RPDCA_Resrv1Avail 2;
BA_ "GenSigSendType" SG_ 2152775680 RPDCA_Resrv1Avail 10;
BA_ "VNSigAllNodes" SG_ 2152775680 RPDCA_Resrv1Avail 1;
BA_ "SignalType" SG_ 2152775680 RPDCA_Resrv1Avail "BLN";
BA_ "PacketOrder" SG_ 2152775680 RPDCA_Resrv1Avail 5;
BA_ "SignalLongName" SG_ 2152775680 RPDCA_Resrv1Avail "Rear Pedestrian Detection Customization Available : Reserved1 Available";
BA_ "GenSigSendOnInit" SG_ 2152775680 RPDCA_AlrtBrkAvail 2;
BA_ "GenSigSendType" SG_ 2152775680 RPDCA_AlrtBrkAvail 10;
BA_ "VNSigAllNodes" SG_ 2152775680 RPDCA_AlrtBrkAvail 1;
BA_ "SignalType" SG_ 2152775680 RPDCA_AlrtBrkAvail "BLN";
BA_ "PacketOrder" SG_ 2152775680 RPDCA_AlrtBrkAvail 4;
BA_ "SignalLongName" SG_ 2152775680 RPDCA_AlrtBrkAvail "Rear Pedestrian Detection Customization Available : Alert and Brake Available";
BA_ "GenSigSendOnInit" SG_ 2152775680 RPDCA_AlrtAvail 2;
BA_ "GenSigSendType" SG_ 2152775680 RPDCA_AlrtAvail 10;
BA_ "VNSigAllNodes" SG_ 2152775680 RPDCA_AlrtAvail 1;
BA_ "SignalType" SG_ 2152775680 RPDCA_AlrtAvail "BLN";
BA_ "PacketOrder" SG_ 2152775680 RPDCA_AlrtAvail 3;
BA_ "SignalLongName" SG_ 2152775680 RPDCA_AlrtAvail "Rear Pedestrian Detection Customization Available : Alert Available";
BA_ "GenSigSendOnInit" SG_ 2152775680 RPDCA_OnAvail 2;
BA_ "GenSigSendType" SG_ 2152775680 RPDCA_OnAvail 10;
BA_ "VNSigAllNodes" SG_ 2152775680 RPDCA_OnAvail 1;
BA_ "SignalType" SG_ 2152775680 RPDCA_OnAvail "BLN";
BA_ "PacketOrder" SG_ 2152775680 RPDCA_OnAvail 2;
BA_ "SignalLongName" SG_ 2152775680 RPDCA_OnAvail "Rear Pedestrian Detection Customization Available : On Available";
BA_ "GenSigStartValue" SG_ 2152775680 RPDCA_OnAvail 1;
BA_ "GenSigSendOnInit" SG_ 2152775680 RPDCA_OfAvail 2;
BA_ "GenSigSendType" SG_ 2152775680 RPDCA_OfAvail 10;
BA_ "VNSigAllNodes" SG_ 2152775680 RPDCA_OfAvail 1;
BA_ "SignalType" SG_ 2152775680 RPDCA_OfAvail "BLN";
BA_ "PacketOrder" SG_ 2152775680 RPDCA_OfAvail 1;
BA_ "SignalLongName" SG_ 2152775680 RPDCA_OfAvail "Rear Pedestrian Detection Customization Available : Off Available";
BA_ "GenSigStartValue" SG_ 2152775680 RPDCA_OfAvail 1;
BA_ "GenSigSendOnInit" SG_ 2152775680 DispTrgdVidOn 2;
BA_ "GenSigSendType" SG_ 2152775680 DispTrgdVidOn 10;
BA_ "VNSigAllNodes" SG_ 2152775680 DispTrgdVidOn 1;
BA_ "SignalType" SG_ 2152775680 DispTrgdVidOn "BLN";
BA_ "SignalLongName" SG_ 2152775680 DispTrgdVidOn "Display Triggered Video On";
BA_ "GenSigSendOnInit" SG_ 2152775680 a_360DegVidFetrPrsnt 2;
BA_ "GenSigSendType" SG_ 2152775680 a_360DegVidFetrPrsnt 10;
BA_ "VNSigAllNodes" SG_ 2152775680 a_360DegVidFetrPrsnt 1;
BA_ "SignalType" SG_ 2152775680 a_360DegVidFetrPrsnt "BLN";
BA_ "SignalLongName" SG_ 2152775680 a_360DegVidFetrPrsnt "360 Degree Video Feature Present";
BA_ "GenSigSendOnInit" SG_ 2152775680 TrgdVidRecFetrPrsnt 2;
BA_ "GenSigSendType" SG_ 2152775680 TrgdVidRecFetrPrsnt 10;
BA_ "VNSigAllNodes" SG_ 2152775680 TrgdVidRecFetrPrsnt 1;
BA_ "SignalType" SG_ 2152775680 TrgdVidRecFetrPrsnt "BLN";
BA_ "SignalLongName" SG_ 2152775680 TrgdVidRecFetrPrsnt "Triggered Video Recorder Feature Present";
BA_ "GenSigSendType" SG_ 2152775680 RrPdDetHptcStVbRq 12;
BA_ "GenSigDeltaValue" SG_ 2152775680 RrPdDetHptcStVbRq 1;
BA_ "VNSigAllNodes" SG_ 2152775680 RrPdDetHptcStVbRq 1;
BA_ "SignalType" SG_ 2152775680 RrPdDetHptcStVbRq "UNM";
BA_ "SignalLongName" SG_ 2152775680 RrPdDetHptcStVbRq "Rear Pedestrian Detection Haptic Seat Vibration Request";
BA_ "GenSigSendType" SG_ 2152775680 RrPdDetHptcStVbRqSeqN 12;
BA_ "GenSigDeltaValue" SG_ 2152775680 RrPdDetHptcStVbRqSeqN 1;
BA_ "VNSigAllNodes" SG_ 2152775680 RrPdDetHptcStVbRqSeqN 1;
BA_ "SignalType" SG_ 2152775680 RrPdDetHptcStVbRqSeqN "UNM";
BA_ "SignalLongName" SG_ 2152775680 RrPdDetHptcStVbRqSeqN "Rear Pedestrian Detection Haptic Seat Vibration Request Sequence Number";
BA_ "GenSigSendOnInit" SG_ 2152775680 RrPedDetCstStVal 2;
BA_ "GenSigSendType" SG_ 2152775680 RrPedDetCstStVal 10;
BA_ "VNSigAllNodes" SG_ 2152775680 RrPedDetCstStVal 1;
BA_ "SignalType" SG_ 2152775680 RrPedDetCstStVal "ENM";
BA_ "SignalLongName" SG_ 2152775680 RrPedDetCstStVal "Rear Pedestrian Detection Customization Current Setting Value";
BA_ "GenSigSendOnInit" SG_ 2152775680 RrPedDetCstStAvl 2;
BA_ "GenSigSendType" SG_ 2152775680 RrPedDetCstStAvl 10;
BA_ "VNSigAllNodes" SG_ 2152775680 RrPedDetCstStAvl 1;
BA_ "SignalType" SG_ 2152775680 RrPedDetCstStAvl "BLN";
BA_ "SignalLongName" SG_ 2152775680 RrPedDetCstStAvl "Rear Pedestrian Detection Customization Setting Available";
BA_ "GenSigSendOnInit" SG_ 2152775680 SurdVwLightgCsCurrSetVal 2;
BA_ "GenSigSendType" SG_ 2152775680 SurdVwLightgCsCurrSetVal 10;
BA_ "VNSigAllNodes" SG_ 2152775680 SurdVwLightgCsCurrSetVal 1;
BA_ "SignalType" SG_ 2152775680 SurdVwLightgCsCurrSetVal "ENM";
BA_ "SignalLongName" SG_ 2152775680 SurdVwLightgCsCurrSetVal "Surround View Lighting Customization Current Setting Value";
BA_ "GenSigSendOnInit" SG_ 2152775680 DispSmrtTwVidOn 2;
BA_ "GenSigSendType" SG_ 2152775680 DispSmrtTwVidOn 10;
BA_ "VNSigAllNodes" SG_ 2152775680 DispSmrtTwVidOn 1;
BA_ "SignalType" SG_ 2152775680 DispSmrtTwVidOn "BLN";
BA_ "SignalLongName" SG_ 2152775680 DispSmrtTwVidOn "Display Smart Tow Video On";
BA_ "GenSigSendOnInit" SG_ 2152775680 DispFrt360CamOn 2;
BA_ "GenSigSendType" SG_ 2152775680 DispFrt360CamOn 10;
BA_ "VNSigAllNodes" SG_ 2152775680 DispFrt360CamOn 1;
BA_ "SignalType" SG_ 2152775680 DispFrt360CamOn "BLN";
BA_ "SignalLongName" SG_ 2152775680 DispFrt360CamOn "Display Front 360 Camera On";
BA_ "GenSigSendOnInit" SG_ 2152775680 SurdVwLightgCsSetAvail 2;
BA_ "GenSigSendType" SG_ 2152775680 SurdVwLightgCsSetAvail 10;
BA_ "VNSigAllNodes" SG_ 2152775680 SurdVwLightgCsSetAvail 1;
BA_ "SignalType" SG_ 2152775680 SurdVwLightgCsSetAvail "BLN";
BA_ "SignalLongName" SG_ 2152775680 SurdVwLightgCsSetAvail "Surround View Lighting Customization Setting Available";
BA_ "GenSigSendType" SG_ 2152775680 PudlLmpReqstd 10;
BA_ "VNSigAllNodes" SG_ 2152775680 PudlLmpReqstd 1;
BA_ "SignalType" SG_ 2152775680 PudlLmpReqstd "BLN";
BA_ "SignalLongName" SG_ 2152775680 PudlLmpReqstd "Puddle Lamp Requested";
BA_ "GenSigSendType" SG_ 2153865216 TeenDrvReq 10;
BA_ "VNSigAllNodes" SG_ 2153865216 TeenDrvReq 1;
BA_ "SignalType" SG_ 2153865216 TeenDrvReq "ENM";
BA_ "SignalLongName" SG_ 2153865216 TeenDrvReq "Teen Driver Request";
BA_ "GenSigSendType" SG_ 2153865216 TeenDrvPinCd 10;
BA_ "GenSigDeltaValue" SG_ 2153865216 TeenDrvPinCd 1;
BA_ "VNSigAllNodes" SG_ 2153865216 TeenDrvPinCd 1;
BA_ "SignalType" SG_ 2153865216 TeenDrvPinCd "BCD";
BA_ "SignalLongName" SG_ 2153865216 TeenDrvPinCd "Teen Driver PIN Code";
BA_ "GenSigSendType" SG_ 2153865216 TnDrvSpdLmtCstStReq 10;
BA_ "VNSigAllNodes" SG_ 2153865216 TnDrvSpdLmtCstStReq 1;
BA_ "SignalType" SG_ 2153865216 TnDrvSpdLmtCstStReq "ENM";
BA_ "SignalLongName" SG_ 2153865216 TnDrvSpdLmtCstStReq "Teen Driver Speed Limit Customization Setting Request";
BA_ "GenSigSendType" SG_ 2153865216 TDOWCSR_StatReq 10;
BA_ "VNSigAllNodes" SG_ 2153865216 TDOWCSR_StatReq 1;
BA_ "SignalType" SG_ 2153865216 TDOWCSR_StatReq "ENM";
BA_ "PacketOrder" SG_ 2153865216 TDOWCSR_StatReq 1;
BA_ "SignalLongName" SG_ 2153865216 TDOWCSR_StatReq "Teen Driver Overspeed Warning Customization Setting Request : Status Request";
BA_ "GenSigSendType" SG_ 2153865216 TDOWCSR_IncSwAct 10;
BA_ "VNSigAllNodes" SG_ 2153865216 TDOWCSR_IncSwAct 1;
BA_ "SignalType" SG_ 2153865216 TDOWCSR_IncSwAct "BLN";
BA_ "PacketOrder" SG_ 2153865216 TDOWCSR_IncSwAct 2;
BA_ "SignalLongName" SG_ 2153865216 TDOWCSR_IncSwAct "Teen Driver Overspeed Warning Customization Setting Request : Increment  Switch Active";
BA_ "GenSigSendType" SG_ 2153865216 TDOWCSR_DecSwAct 10;
BA_ "VNSigAllNodes" SG_ 2153865216 TDOWCSR_DecSwAct 1;
BA_ "SignalType" SG_ 2153865216 TDOWCSR_DecSwAct "BLN";
BA_ "PacketOrder" SG_ 2153865216 TDOWCSR_DecSwAct 3;
BA_ "SignalLongName" SG_ 2153865216 TDOWCSR_DecSwAct "Teen Driver Overspeed Warning Customization Setting Request : Decrement  Switch Active";
BA_ "GenSigSendOnInit" SG_ 2150391808 EngRunAtvTm 1;
BA_ "GenSigSendType" SG_ 2150391808 EngRunAtvTm 12;
BA_ "GenSigDeltaValue" SG_ 2150391808 EngRunAtvTm 1;
BA_ "VNSigAllNodes" SG_ 2150391808 EngRunAtvTm 1;
BA_ "SignalType" SG_ 2150391808 EngRunAtvTm "UNM";
BA_ "SignalLongName" SG_ 2150391808 EngRunAtvTm "Engine Run Active Time";
BA_ "GenSigSendOnInit" SG_ 2150391808 EngIdlAtvTm 1;
BA_ "GenSigSendType" SG_ 2150391808 EngIdlAtvTm 12;
BA_ "GenSigDeltaValue" SG_ 2150391808 EngIdlAtvTm 1;
BA_ "VNSigAllNodes" SG_ 2150391808 EngIdlAtvTm 1;
BA_ "SignalType" SG_ 2150391808 EngIdlAtvTm "UNM";
BA_ "SignalLongName" SG_ 2150391808 EngIdlAtvTm "Engine Idle Active Time";
BA_ "GenSigSendType" SG_ 2155970560 ClmCntBatSaverIO 10;
BA_ "VNSigAllNodes" SG_ 2155970560 ClmCntBatSaverIO 1;
BA_ "SignalType" SG_ 2155970560 ClmCntBatSaverIO "BLN";
BA_ "SignalLongName" SG_ 2155970560 ClmCntBatSaverIO "Climate Control Battery Saver Indication On";
BA_ "GenSigSendType" SG_ 2155970560 ClmCntLdShdLvlRq 10;
BA_ "VNSigAllNodes" SG_ 2155970560 ClmCntLdShdLvlRq 1;
BA_ "SignalType" SG_ 2155970560 ClmCntLdShdLvlRq "ENM";
BA_ "SignalLongName" SG_ 2155970560 ClmCntLdShdLvlRq "Climate Control Load Shedding Level Request";
BA_ "GenSigSendType" SG_ 2151178240 AFLGPSCstStReq 10;
BA_ "VNSigAllNodes" SG_ 2151178240 AFLGPSCstStReq 1;
BA_ "SignalType" SG_ 2151178240 AFLGPSCstStReq "ENM";
BA_ "SignalLongName" SG_ 2151178240 AFLGPSCstStReq "Adaptive Forward Lighting With GPS Customization Setting Request";
BA_ "GenSigSendType" SG_ 2151178240 AFLCstStReq 10;
BA_ "VNSigAllNodes" SG_ 2151178240 AFLCstStReq 1;
BA_ "SignalType" SG_ 2151178240 AFLCstStReq "ENM";
BA_ "SignalLongName" SG_ 2151178240 AFLCstStReq "Adaptive Forward Lighting Customization Setting Request";
BA_ "GenSigSendType" SG_ 2151178240 LtRtHnTrCstStReq 10;
BA_ "VNSigAllNodes" SG_ 2151178240 LtRtHnTrCstStReq 1;
BA_ "SignalType" SG_ 2151178240 LtRtHnTrCstStReq "ENM";
BA_ "SignalLongName" SG_ 2151178240 LtRtHnTrCstStReq "Left Right Hand Traffic Customization Setting Request";
BA_ "GenSigSendType" SG_ 2151178240 AdpHgBmAsSnCsStRq 10;
BA_ "VNSigAllNodes" SG_ 2151178240 AdpHgBmAsSnCsStRq 1;
BA_ "SignalType" SG_ 2151178240 AdpHgBmAsSnCsStRq "ENM";
BA_ "SignalLongName" SG_ 2151178240 AdpHgBmAsSnCsStRq "Adaptive High Beam Assist With Sensitivity Customization Setting Request";
BA_ "GenSigSendType" SG_ 2151178240 AdpHgBmAstCstStRq 10;
BA_ "VNSigAllNodes" SG_ 2151178240 AdpHgBmAstCstStRq 1;
BA_ "SignalType" SG_ 2151178240 AdpHgBmAstCstStRq "ENM";
BA_ "SignalLongName" SG_ 2151178240 AdpHgBmAstCstStRq "Adaptive High Beam Assist Customization Setting Request";
BA_ "GenSigSendType" SG_ 2151178240 LtRtHnTrGPSCstStRq 10;
BA_ "VNSigAllNodes" SG_ 2151178240 LtRtHnTrGPSCstStRq 1;
BA_ "SignalType" SG_ 2151178240 LtRtHnTrGPSCstStRq "ENM";
BA_ "SignalLongName" SG_ 2151178240 LtRtHnTrGPSCstStRq "Left Right Hand Traffic With GPS Customization Setting Request";
BA_ "GenSigSendType" SG_ 2151178240 AutHgBmAsSnCsStRq 10;
BA_ "VNSigAllNodes" SG_ 2151178240 AutHgBmAsSnCsStRq 1;
BA_ "SignalType" SG_ 2151178240 AutHgBmAsSnCsStRq "ENM";
BA_ "SignalLongName" SG_ 2151178240 AutHgBmAsSnCsStRq "Auto High Beam Assist With Sensitivity Customization Setting Request";
BA_ "GenSigSendType" SG_ 2151178240 AutHgBmAstCstStRq 10;
BA_ "VNSigAllNodes" SG_ 2151178240 AutHgBmAstCstStRq 1;
BA_ "SignalType" SG_ 2151178240 AutHgBmAstCstStRq "ENM";
BA_ "SignalLongName" SG_ 2151178240 AutHgBmAstCstStRq "Auto High Beam Assist Customization Setting Request";
BA_ "GenSigSendType" SG_ 2151882752 PTOTpStpSpdCsStReq 10;
BA_ "VNSigAllNodes" SG_ 2151882752 PTOTpStpSpdCsStReq 1;
BA_ "SignalType" SG_ 2151882752 PTOTpStpSpdCsStReq "ENM";
BA_ "SignalLongName" SG_ 2151882752 PTOTpStpSpdCsStReq "Power Take Off Tap Step Speed Customization Setting Request";
BA_ "GenSigSendType" SG_ 2151882752 PTOStdbySpdCsStReq 10;
BA_ "VNSigAllNodes" SG_ 2151882752 PTOStdbySpdCsStReq 1;
BA_ "SignalType" SG_ 2151882752 PTOStdbySpdCsStReq "ENM";
BA_ "SignalLongName" SG_ 2151882752 PTOStdbySpdCsStReq "Power Take Off Standby Speed Customization Setting Request";
BA_ "GenSigSendType" SG_ 2151882752 PTOEngRnTmrCsStRq 10;
BA_ "VNSigAllNodes" SG_ 2151882752 PTOEngRnTmrCsStRq 1;
BA_ "SignalType" SG_ 2151882752 PTOEngRnTmrCsStRq "ENM";
BA_ "SignalLongName" SG_ 2151882752 PTOEngRnTmrCsStRq "Power Take Off Engine Run Timer Customization Setting Request";
BA_ "GenSigSendType" SG_ 2151882752 PTOSet2SpdCsStReq 10;
BA_ "VNSigAllNodes" SG_ 2151882752 PTOSet2SpdCsStReq 1;
BA_ "SignalType" SG_ 2151882752 PTOSet2SpdCsStReq "ENM";
BA_ "SignalLongName" SG_ 2151882752 PTOSet2SpdCsStReq "Power Take Off Set 2 Speed Customization Setting Request";
BA_ "GenSigSendType" SG_ 2151882752 PTOSet1SpdCsStReq 10;
BA_ "VNSigAllNodes" SG_ 2151882752 PTOSet1SpdCsStReq 1;
BA_ "SignalType" SG_ 2151882752 PTOSet1SpdCsStReq "ENM";
BA_ "SignalLongName" SG_ 2151882752 PTOSet1SpdCsStReq "Power Take Off Set 1 Speed Customization Setting Request";
BA_REL_ "GenSigSuprvResp" BU_SG_REL_ ECC_LS SG_ 2151202816 AuxHtrAlwd 1;
BA_REL_ "GenSigSuprvResp" BU_SG_REL_ ECC_LS SG_ 2151202816 IPSnsrTpCvrTempFltd 1;
BA_REL_ "GenSigSuprvResp" BU_SG_REL_ ECC_LS SG_ 2151202816 IPSnsrTpCvrTemp 1;
BA_REL_ "GenSigSuprvResp" BU_SG_REL_ ECC_LS SG_ 2151202816 IPSnsrSolrElvtnAngl 1;
BA_REL_ "GenSigSuprvResp" BU_SG_REL_ ECC_LS SG_ 2151202816 IPSnsrSolrAzmthAngl 1;
BA_REL_ "GenSigSuprvResp" BU_SG_REL_ ECC_LS SG_ 2151202816 IPSnsrSolrAnglFltd 1;
BA_REL_ "GenSigSuprvResp" BU_SG_REL_ ECC_LS SG_ 2151202816 IPSnsrRwSolrIntFltd 1;
BA_REL_ "GenSigSuprvResp" BU_SG_REL_ ECC_LS SG_ 2151202816 IPSnsrRwSolrInt 1;
BA_REL_ "GenSigSuprvResp" BU_SG_REL_ ECC_LS SG_ 2151202816 ILSSCommErr 1;
BA_REL_ "GenSigSuprvResp" BU_SG_REL_ PEPS_LS SG_ 2151759872 RrClsRelRq 1;
BA_REL_ "GenSigSuprvResp" BU_SG_REL_ PEPS_LS SG_ 2150137856 LMTTCPrsnOffStat 1;
BA_REL_ "GenSigSuprvResp" BU_SG_REL_ PEPS_LS SG_ 2150137856 FldTpMotReq 1;
BA_REL_ "GenSigSuprvResp" BU_SG_REL_ EOCM_F_LS SG_ 2154561536 VehOdo 1;
BA_REL_ "GenSigSuprvResp" BU_SG_REL_ ECC_LS SG_ 2154561536 VehOdo 1;
BA_REL_ "GenSigSuprvResp" BU_SG_REL_ VIS2_LS SG_ 2149908480 BrkPdlPos 1;
BA_REL_ "GenSigSuprvResp" BU_SG_REL_ SDM_LS SG_ 2149908480 BrkPedTrvlAchvd 1;
BA_REL_ "GenSigSuprvResp" BU_SG_REL_ VIS2_LS SG_ 2149908480 BrkPedTrvlAchvd 1;
BA_REL_ "GenSigSuprvResp" BU_SG_REL_ SDM_LS SG_ 2149908480 BrkPedTrvlAchvdV 1;
BA_REL_ "GenSigSuprvResp" BU_SG_REL_ VIS2_LS SG_ 2149908480 BrkPedTrvlAchvdV 1;
BA_REL_ "GenSigSuprvResp" BU_SG_REL_ BCM_LS SG_ 2155954176 ClimCtrlAftBlowModActv 1;
BA_REL_ "GenSigSuprvResp" BU_SG_REL_ PTM_LS SG_ 2155954176 ClmCntFrBlwFnSp 1;
BA_REL_ "GenSigSuprvResp" BU_SG_REL_ BCM_LS SG_ 2155954176 ACHtIdleBstLevReq 1;
BA_REL_ "GenSigSuprvResp" BU_SG_REL_ ECC_LS SG_ 2149875712 BattCrntFltrd 1;
BA_REL_ "GenSigSuprvResp" BU_SG_REL_ MSM_LS SG_ 2149875712 EnrgMgtLdShdRq 1;
BA_REL_ "GenSigSuprvResp" BU_SG_REL_ DCAC_LS SG_ 2149875712 EnrgMgtLdShdRq 1;
BA_REL_ "GenSigSuprvResp" BU_SG_REL_ ECC_LS SG_ 2149875712 EnrgMgtLdShdRq 1;
BA_REL_ "GenSigSuprvResp" BU_SG_REL_ PEPS_LS SG_ 2149875712 BatSOC 1;
BA_REL_ "GenSigSuprvResp" BU_SG_REL_ DCAC_LS SG_ 2149875712 BatSOC 1;
BA_REL_ "GenSigSuprvResp" BU_SG_REL_ PEPS_LS SG_ 2149875712 BatVlt 1;
BA_REL_ "GenSigSuprvResp" BU_SG_REL_ MSM_LS SG_ 2149875712 BatVlt 1;
BA_REL_ "GenSigVBitResp" BU_SG_REL_ MSM_LS SG_ 2149875712 BatVlt 1;
BA_REL_ "GenSigSuprvResp" BU_SG_REL_ EOCM_F_LS SG_ 2149875712 BatVlt 1;
BA_REL_ "GenSigSuprvResp" BU_SG_REL_ ECC_LS SG_ 2149875712 BatVlt 1;
BA_REL_ "GenSigVBitResp" BU_SG_REL_ ECC_LS SG_ 2149875712 BatVlt 1;
BA_REL_ "GenSigSuprvResp" BU_SG_REL_ SDM_LS SG_ 2154053632 DispNtSchmAtv 1;
BA_REL_ "GenSigSuprvResp" BU_SG_REL_ HFP_LS SG_ 2154053632 DispNtSchmAtv 1;
BA_REL_ "GenSigSuprvResp" BU_SG_REL_ MSM_LS SG_ 2154053632 IntDimLvl 1;
BA_REL_ "GenSigSuprvResp" BU_SG_REL_ ECC_LS SG_ 2154053632 IntDimLvl 1;
BA_REL_ "GenSigSuprvResp" BU_SG_REL_ SDM_LS SG_ 2154053632 IntDimDspLvl 1;
BA_REL_ "GenSigSuprvResp" BU_SG_REL_ ECC_LS SG_ 2154053632 IntDimDspLvl 1;
BA_REL_ "GenSigSuprvResp" BU_SG_REL_ SBZA_R_LS SG_ 2153824256 TeenDrvAct 1;
BA_REL_ "GenSigSuprvResp" BU_SG_REL_ SBZA_L_LS SG_ 2153824256 TeenDrvAct 1;
BA_REL_ "GenSigSuprvResp" BU_SG_REL_ UPA_LS SG_ 2153824256 TeenDrvAct 1;
BA_REL_ "GenSigSuprvResp" BU_SG_REL_ VIS2_LS SG_ 2153824256 TeenDrvAct 1;
BA_REL_ "GenSigSuprvResp" BU_SG_REL_ EOCM_F_LS SG_ 2153824256 TeenDrvAct 1;
BA_REL_ "GenSigSuprvResp" BU_SG_REL_ UPA_LS SG_ 2149957632 PrkAstRrObjSnsngRqAct 1;
BA_REL_ "GenSigSuprvResp" BU_SG_REL_ UPA_LS SG_ 2149957632 PrkAstOprtrDsrdStat 1;
BA_REL_ "GenSigSuprvResp" BU_SG_REL_ UPA_LS SG_ 2149957632 PrkAstInhbtReq 1;
BA_REL_ "GenSigSuprvResp" BU_SG_REL_ UPA_LS SG_ 2149957632 ClsnMtgtnInhbtd 1;
BA_REL_ "GenSigSuprvResp" BU_SG_REL_ VIS2_LS SG_ 2151751680 HptcStFldIO 1;
BA_REL_ "GenSigSuprvResp" BU_SG_REL_ SBZA_R_LS SG_ 2151751680 HptcStVbnStat 1;
BA_REL_ "GenSigSuprvResp" BU_SG_REL_ SBZA_L_LS SG_ 2151751680 HptcStVbnStat 1;
BA_REL_ "GenSigSuprvResp" BU_SG_REL_ UPA_LS SG_ 2151751680 HptcStVbnStat 1;
BA_REL_ "GenSigSuprvResp" BU_SG_REL_ VIS2_LS SG_ 2151751680 HptcStVbnStat 1;
BA_REL_ "GenSigSuprvResp" BU_SG_REL_ EOCM_F_LS SG_ 2151751680 HptcStVbnStat 1;
BA_REL_ "GenSigSuprvResp" BU_SG_REL_ BCM_LS SG_ 2151751680 HptcStVbnStat 1;
BA_REL_ "GenSigSuprvResp" BU_SG_REL_ EOCM_F_LS SG_ 2151751680 CrshAlrtDrvrSlctdType 1;
BA_REL_ "GenSigSuprvResp" BU_SG_REL_ BCM_LS SG_ 2151751680 CrshAlrtDrvrSlctdType 1;
BA_REL_ "GenSigSuprvResp" BU_SG_REL_ EOCM_F_LS SG_ 2151751680 CrshAlrtStPrsnt 1;
BA_REL_ "GenSigSuprvResp" BU_SG_REL_ EOCM_F_LS SG_ 2149990400 TrlrCnctdIO 1;
BA_REL_ "GenSigSuprvResp" BU_SG_REL_ SDM_LS SG_ 2149990400 ABSIO 1;
BA_REL_ "GenSigSuprvResp" BU_SG_REL_ PTM_LS SG_ 2155380736 PwrPkFnSpd 1;
BA_REL_ "GenSigSuprvResp" BU_SG_REL_ EOCM_F_LS SG_ 2155380736 AdvFrntLghtSysIndRq 1;
BA_REL_ "GenSigSuprvResp" BU_SG_REL_ SDM_LS SG_ 2155380736 RdcdPwrIO 1;
BA_REL_ "GenSigVDAFailResp" BU_SG_REL_ SDM_LS SG_ 2155380736 RdcdPwrIO 1;
BA_REL_ "GenSigVDAFailComment" BU_SG_REL_ SDM_LS SG_ 2155380736 RdcdPwrIO "Engine Virtual Device Availability";
BA_REL_ "GenSigSuprvResp" BU_SG_REL_ ECC_LS SG_ 2150498304 EngCltTmp 1;
BA_REL_ "GenSigSuprvResp" BU_SG_REL_ UPA_LS SG_ 2158845952 ODIAC_FUCID 1;
BA_REL_ "GenSigSuprvResp" BU_SG_REL_ EOCM_F_LS SG_ 2158845952 ODIAC_FUCID 1;
BA_REL_ "GenSigSuprvResp" BU_SG_REL_ UPA_LS SG_ 2158845952 ODIAC_DspMID 1;
BA_REL_ "GenSigSuprvResp" BU_SG_REL_ EOCM_F_LS SG_ 2158845952 ODIAC_DspMID 1;
BA_REL_ "GenSigSuprvResp" BU_SG_REL_ UPA_LS SG_ 2158845952 ODIAC_DaTy 1;
BA_REL_ "GenSigSuprvResp" BU_SG_REL_ EOCM_F_LS SG_ 2158845952 ODIAC_DaTy 1;
BA_REL_ "GenSigSuprvResp" BU_SG_REL_ UPA_LS SG_ 2158845952 ODIAC_ActnVal 1;
BA_REL_ "GenSigSuprvResp" BU_SG_REL_ EOCM_F_LS SG_ 2158845952 ODIAC_ActnVal 1;
BA_REL_ "GenSigSuprvResp" BU_SG_REL_ UPA_LS SG_ 2158845952 ODIAC_ActnID 1;
BA_REL_ "GenSigSuprvResp" BU_SG_REL_ EOCM_F_LS SG_ 2158845952 ODIAC_ActnID 1;
BA_REL_ "GenSigSuprvResp" BU_SG_REL_ UPA_LS SG_ 2151366656 PrkBrkSwAtv 1;
BA_REL_ "GenSigSuprvResp" BU_SG_REL_ MSM_LS SG_ 2151366656 PrkBrkSwAtv 1;
BA_REL_ "GenSigSuprvResp" BU_SG_REL_ MSM_LS SG_ 2149842944 AdptDrvrSeatStng 1;
BA_REL_ "GenSigSuprvResp" BU_SG_REL_ UPA_LS SG_ 2149842944 IMUProtLonAcc 1;
BA_REL_ "GenSigSuprvResp" BU_SG_REL_ PTM_LS SG_ 2149842944 IMUProtLonAcc 1;
BA_REL_ "GenSigSuprvResp" BU_SG_REL_ VIS2_LS SG_ 2149842944 IMUProtLonAcc 1;
BA_REL_ "GenSigSuprvResp" BU_SG_REL_ VIS2_LS SG_ 2149842944 TCSysAtv 1;
BA_REL_ "GenSigSuprvResp" BU_SG_REL_ EOCM_F_LS SG_ 2149842944 VSEAct 1;
BA_REL_ "GenSigSuprvResp" BU_SG_REL_ UPA_LS SG_ 2149842944 StrWhAng 1;
BA_REL_ "GenSigVDAFailResp" BU_SG_REL_ UPA_LS SG_ 2149842944 StrWhAng 1;
BA_REL_ "GenSigVDAFailComment" BU_SG_REL_ UPA_LS SG_ 2149842944 StrWhAng "StWhAnVDA";
BA_REL_ "GenSigSuprvResp" BU_SG_REL_ VIS2_LS SG_ 2149842944 StrWhAng 1;
BA_REL_ "GenSigVDAFailResp" BU_SG_REL_ VIS2_LS SG_ 2149842944 StrWhAng 1;
BA_REL_ "GenSigVDAFailComment" BU_SG_REL_ VIS2_LS SG_ 2149842944 StrWhAng "StWhAnVDA";
BA_REL_ "GenSigVBitRespComment" BU_SG_REL_ VIS2_LS SG_ 2149842944 StrWhAng "StrWhAngV";
BA_REL_ "GenSigVBitResp" BU_SG_REL_ VIS2_LS SG_ 2149842944 StrWhAng 1;
BA_REL_ "GenSigSuprvResp" BU_SG_REL_ UPA_LS SG_ 2154528768 WhlGrndVlctyRtNnDrvn 1;
BA_REL_ "GenSigVDAFailResp" BU_SG_REL_ UPA_LS SG_ 2154528768 WhlGrndVlctyRtNnDrvn 1;
BA_REL_ "GenSigVDAFailComment" BU_SG_REL_ UPA_LS SG_ 2154528768 WhlGrndVlctyRtNnDrvn "Brake System Virtual Device Availability";
BA_REL_ "GenSigVBitResp" BU_SG_REL_ UPA_LS SG_ 2154528768 WhlGrndVlctyRtNnDrvn 1;
BA_REL_ "GenSigSuprvResp" BU_SG_REL_ SDM_LS SG_ 2154528768 WhlGrndVlctyRtNnDrvn 1;
BA_REL_ "GenSigSuprvResp" BU_SG_REL_ UPA_LS SG_ 2154528768 WhlGrndVlctyRtDrvn 1;
BA_REL_ "GenSigVDAFailResp" BU_SG_REL_ UPA_LS SG_ 2154528768 WhlGrndVlctyRtDrvn 1;
BA_REL_ "GenSigVDAFailComment" BU_SG_REL_ UPA_LS SG_ 2154528768 WhlGrndVlctyRtDrvn "Brake System Virtual Device Availability";
BA_REL_ "GenSigVBitResp" BU_SG_REL_ UPA_LS SG_ 2154528768 WhlGrndVlctyRtDrvn 1;
BA_REL_ "GenSigSuprvResp" BU_SG_REL_ SDM_LS SG_ 2154528768 WhlGrndVlctyRtDrvn 1;
BA_REL_ "GenSigSuprvResp" BU_SG_REL_ UPA_LS SG_ 2154528768 WhlGrndVlctyLftNnDrvn 1;
BA_REL_ "GenSigVDAFailResp" BU_SG_REL_ UPA_LS SG_ 2154528768 WhlGrndVlctyLftNnDrvn 1;
BA_REL_ "GenSigVDAFailComment" BU_SG_REL_ UPA_LS SG_ 2154528768 WhlGrndVlctyLftNnDrvn "Brake System Virtual Device Availability";
BA_REL_ "GenSigVBitResp" BU_SG_REL_ UPA_LS SG_ 2154528768 WhlGrndVlctyLftNnDrvn 1;
BA_REL_ "GenSigSuprvResp" BU_SG_REL_ SDM_LS SG_ 2154528768 WhlGrndVlctyLftNnDrvn 1;
BA_REL_ "GenSigSuprvResp" BU_SG_REL_ UPA_LS SG_ 2154528768 WhlGrndVlctyLftDrvn 1;
BA_REL_ "GenSigVDAFailResp" BU_SG_REL_ UPA_LS SG_ 2154528768 WhlGrndVlctyLftDrvn 1;
BA_REL_ "GenSigVDAFailComment" BU_SG_REL_ UPA_LS SG_ 2154528768 WhlGrndVlctyLftDrvn "Brake System Virtual Device Availability";
BA_REL_ "GenSigVBitResp" BU_SG_REL_ UPA_LS SG_ 2154528768 WhlGrndVlctyLftDrvn 1;
BA_REL_ "GenSigSuprvResp" BU_SG_REL_ SDM_LS SG_ 2154528768 WhlGrndVlctyLftDrvn 1;
BA_REL_ "GenSigSuprvResp" BU_SG_REL_ UPA_LS SG_ 2149777408 WRSLNDWhlDisTpRC 1;
BA_REL_ "GenSigSuprvResp" BU_SG_REL_ UPA_LS SG_ 2149777408 WRSLNDWhlRotStRst 1;
BA_REL_ "GenSigVDAFailResp" BU_SG_REL_ UPA_LS SG_ 2149777408 WRSLNDWhlRotStRst 1;
BA_REL_ "GenSigVDAFailComment" BU_SG_REL_ UPA_LS SG_ 2149777408 WRSLNDWhlRotStRst "BrkSysVDA";
BA_REL_ "GenSigSuprvResp" BU_SG_REL_ UPA_LS SG_ 2149777408 WRSLNDWhlDistVal 1;
BA_REL_ "GenSigVDAFailResp" BU_SG_REL_ UPA_LS SG_ 2149777408 WRSLNDWhlDistVal 1;
BA_REL_ "GenSigVDAFailComment" BU_SG_REL_ UPA_LS SG_ 2149777408 WRSLNDWhlDistVal "BrkSysVDA";
BA_REL_ "GenSigSuprvResp" BU_SG_REL_ UPA_LS SG_ 2149777408 WRSLNDWhlDistTstm 1;
BA_REL_ "GenSigVDAFailResp" BU_SG_REL_ UPA_LS SG_ 2149777408 WRSLNDWhlDistTstm 1;
BA_REL_ "GenSigVDAFailComment" BU_SG_REL_ UPA_LS SG_ 2149777408 WRSLNDWhlDistTstm "BrkSysVDA";
BA_REL_ "GenSigSuprvResp" BU_SG_REL_ UPA_LS SG_ 2149777408 WRSLNDWhlDistPCntr 1;
BA_REL_ "GenSigVDAFailResp" BU_SG_REL_ UPA_LS SG_ 2149777408 WRSLNDWhlDistPCntr 1;
BA_REL_ "GenSigVDAFailComment" BU_SG_REL_ UPA_LS SG_ 2149777408 WRSLNDWhlDistPCntr "BrkSysVDA";
BA_REL_ "GenSigSuprvResp" BU_SG_REL_ UPA_LS SG_ 2149777408 WRSLNDSeqNum 1;
BA_REL_ "GenSigVDAFailResp" BU_SG_REL_ UPA_LS SG_ 2149777408 WRSLNDSeqNum 1;
BA_REL_ "GenSigVDAFailComment" BU_SG_REL_ UPA_LS SG_ 2149777408 WRSLNDSeqNum "BrkSysVDA";
BA_REL_ "GenSigSuprvResp" BU_SG_REL_ UPA_LS SG_ 2149777408 WRSRNDWhlDisTpRC 1;
BA_REL_ "GenSigSuprvResp" BU_SG_REL_ UPA_LS SG_ 2149777408 WRSRNDWhlRotStRst 1;
BA_REL_ "GenSigVDAFailResp" BU_SG_REL_ UPA_LS SG_ 2149777408 WRSRNDWhlRotStRst 1;
BA_REL_ "GenSigVDAFailComment" BU_SG_REL_ UPA_LS SG_ 2149777408 WRSRNDWhlRotStRst "BrkSysVDA";
BA_REL_ "GenSigSuprvResp" BU_SG_REL_ UPA_LS SG_ 2149777408 WRSRNDWhlDistVal 1;
BA_REL_ "GenSigVDAFailResp" BU_SG_REL_ UPA_LS SG_ 2149777408 WRSRNDWhlDistVal 1;
BA_REL_ "GenSigVDAFailComment" BU_SG_REL_ UPA_LS SG_ 2149777408 WRSRNDWhlDistVal "BrkSysVDA";
BA_REL_ "GenSigSuprvResp" BU_SG_REL_ UPA_LS SG_ 2149777408 WRSRNDWhlDistTstm 1;
BA_REL_ "GenSigVDAFailResp" BU_SG_REL_ UPA_LS SG_ 2149777408 WRSRNDWhlDistTstm 1;
BA_REL_ "GenSigVDAFailComment" BU_SG_REL_ UPA_LS SG_ 2149777408 WRSRNDWhlDistTstm "BrkSysVDA";
BA_REL_ "GenSigSuprvResp" BU_SG_REL_ UPA_LS SG_ 2149777408 WRSRNDWhlDistPCntr 1;
BA_REL_ "GenSigVDAFailResp" BU_SG_REL_ UPA_LS SG_ 2149777408 WRSRNDWhlDistPCntr 1;
BA_REL_ "GenSigVDAFailComment" BU_SG_REL_ UPA_LS SG_ 2149777408 WRSRNDWhlDistPCntr "BrkSysVDA";
BA_REL_ "GenSigSuprvResp" BU_SG_REL_ UPA_LS SG_ 2149777408 WRSRNDSeqNum 1;
BA_REL_ "GenSigVDAFailResp" BU_SG_REL_ UPA_LS SG_ 2149777408 WRSRNDSeqNum 1;
BA_REL_ "GenSigVDAFailComment" BU_SG_REL_ UPA_LS SG_ 2149777408 WRSRNDSeqNum "BrkSysVDA";
BA_REL_ "GenSigSuprvResp" BU_SG_REL_ UPA_LS SG_ 2149769216 WRSLDWhlDisTpRC 1;
BA_REL_ "GenSigSuprvResp" BU_SG_REL_ UPA_LS SG_ 2149769216 WRSLDSeqNum 1;
BA_REL_ "GenSigVDAFailResp" BU_SG_REL_ UPA_LS SG_ 2149769216 WRSLDSeqNum 1;
BA_REL_ "GenSigVDAFailComment" BU_SG_REL_ UPA_LS SG_ 2149769216 WRSLDSeqNum "BrkSysVDA";
BA_REL_ "GenSigSuprvResp" BU_SG_REL_ UPA_LS SG_ 2149769216 WRSLDWhlDistVal 1;
BA_REL_ "GenSigVDAFailResp" BU_SG_REL_ UPA_LS SG_ 2149769216 WRSLDWhlDistVal 1;
BA_REL_ "GenSigVDAFailComment" BU_SG_REL_ UPA_LS SG_ 2149769216 WRSLDWhlDistVal "BrkSysVDA";
BA_REL_ "GenSigSuprvResp" BU_SG_REL_ UPA_LS SG_ 2149769216 WRSLDWhlRotStatRst 1;
BA_REL_ "GenSigVDAFailResp" BU_SG_REL_ UPA_LS SG_ 2149769216 WRSLDWhlRotStatRst 1;
BA_REL_ "GenSigVDAFailComment" BU_SG_REL_ UPA_LS SG_ 2149769216 WRSLDWhlRotStatRst "BrkSysVDA";
BA_REL_ "GenSigSuprvResp" BU_SG_REL_ UPA_LS SG_ 2149769216 WRSLDWhlDistTmstm 1;
BA_REL_ "GenSigVDAFailResp" BU_SG_REL_ UPA_LS SG_ 2149769216 WRSLDWhlDistTmstm 1;
BA_REL_ "GenSigVDAFailComment" BU_SG_REL_ UPA_LS SG_ 2149769216 WRSLDWhlDistTmstm "BrkSysVDA";
BA_REL_ "GenSigSuprvResp" BU_SG_REL_ UPA_LS SG_ 2149769216 WRSLDWhlDistPlsCntr 1;
BA_REL_ "GenSigVDAFailResp" BU_SG_REL_ UPA_LS SG_ 2149769216 WRSLDWhlDistPlsCntr 1;
BA_REL_ "GenSigVDAFailComment" BU_SG_REL_ UPA_LS SG_ 2149769216 WRSLDWhlDistPlsCntr "BrkSysVDA";
BA_REL_ "GenSigSuprvResp" BU_SG_REL_ UPA_LS SG_ 2149769216 WRSRDWhlDisTpRC 1;
BA_REL_ "GenSigSuprvResp" BU_SG_REL_ UPA_LS SG_ 2149769216 WRSRDSeqNum 1;
BA_REL_ "GenSigVDAFailResp" BU_SG_REL_ UPA_LS SG_ 2149769216 WRSRDSeqNum 1;
BA_REL_ "GenSigVDAFailComment" BU_SG_REL_ UPA_LS SG_ 2149769216 WRSRDSeqNum "BrkSysVDA";
BA_REL_ "GenSigSuprvResp" BU_SG_REL_ UPA_LS SG_ 2149769216 WRSRDWhlRotStatRst 1;
BA_REL_ "GenSigVDAFailResp" BU_SG_REL_ UPA_LS SG_ 2149769216 WRSRDWhlRotStatRst 1;
BA_REL_ "GenSigVDAFailComment" BU_SG_REL_ UPA_LS SG_ 2149769216 WRSRDWhlRotStatRst "BrkSysVDA";
BA_REL_ "GenSigSuprvResp" BU_SG_REL_ UPA_LS SG_ 2149769216 WRSRDWhlDistVal 1;
BA_REL_ "GenSigVDAFailResp" BU_SG_REL_ UPA_LS SG_ 2149769216 WRSRDWhlDistVal 1;
BA_REL_ "GenSigVDAFailComment" BU_SG_REL_ UPA_LS SG_ 2149769216 WRSRDWhlDistVal "BrkSysVDA";
BA_REL_ "GenSigSuprvResp" BU_SG_REL_ UPA_LS SG_ 2149769216 WRSRDWhlDistTmstm 1;
BA_REL_ "GenSigVDAFailResp" BU_SG_REL_ UPA_LS SG_ 2149769216 WRSRDWhlDistTmstm 1;
BA_REL_ "GenSigVDAFailComment" BU_SG_REL_ UPA_LS SG_ 2149769216 WRSRDWhlDistTmstm "BrkSysVDA";
BA_REL_ "GenSigSuprvResp" BU_SG_REL_ UPA_LS SG_ 2149769216 WRSRDWhlDistPlsCntr 1;
BA_REL_ "GenSigVDAFailResp" BU_SG_REL_ UPA_LS SG_ 2149769216 WRSRDWhlDistPlsCntr 1;
BA_REL_ "GenSigVDAFailComment" BU_SG_REL_ UPA_LS SG_ 2149769216 WRSRDWhlDistPlsCntr "BrkSysVDA";
BA_REL_ "GenSigSuprvResp" BU_SG_REL_ UPA_LS SG_ 2149752832 ElecPrkBrkStat 1;
BA_REL_ "GenSigVDAFailResp" BU_SG_REL_ UPA_LS SG_ 2149752832 ElecPrkBrkStat 1;
BA_REL_ "GenSigVDAFailComment" BU_SG_REL_ UPA_LS SG_ 2149752832 ElecPrkBrkStat "Park Brake Virtual Device Availability";
BA_REL_ "GenSigSuprvResp" BU_SG_REL_ MSM_LS SG_ 2149752832 ElecPrkBrkStat 1;
BA_REL_ "GenSigSuprvResp" BU_SG_REL_ VIS2_LS SG_ 2149752832 ABSAtv 1;
BA_REL_ "GenSigSuprvResp" BU_SG_REL_ SDM_LS SG_ 2149752832 ABSAtv 1;
BA_REL_ "GenSigSuprvResp" BU_SG_REL_ MSM_LS SG_ 2152775680 RrPdDetHptcStVbRq 1;
BA_REL_ "GenSigSuprvResp" BU_SG_REL_ MSM_LS SG_ 2152775680 RrPdDetHptcStVbRqSeqN 1;
BA_REL_ "GenSigSuprvResp" BU_SG_REL_ BCM_LS SG_ 2153865216 TeenDrvReq 1;
BA_REL_ "GenSigSuprvResp" BU_SG_REL_ BCM_LS SG_ 2153865216 TeenDrvPinCd 1;
BA_REL_ "GenSigSuprvResp" BU_SG_REL_ BCM_LS SG_ 2153865216 TnDrvSpdLmtCstStReq 1;
BA_REL_ "GenSigSuprvResp" BU_SG_REL_ BCM_LS SG_ 2153865216 TDOWCSR_StatReq 1;
BA_REL_ "GenSigSuprvResp" BU_SG_REL_ BCM_LS SG_ 2153865216 TDOWCSR_IncSwAct 1;
BA_REL_ "GenSigSuprvResp" BU_SG_REL_ BCM_LS SG_ 2153865216 TDOWCSR_DecSwAct 1;
BA_REL_ "GenSigSuprvResp" BU_SG_REL_ BCM_LS SG_ 2150391808 EngRunAtvTm 1;
BA_REL_ "GenSigSuprvResp" BU_SG_REL_ BCM_LS SG_ 2150391808 EngIdlAtvTm 1;
BA_REL_ "GenSigSuprvResp" BU_SG_REL_ MSM_LS SG_ 2155970560 ClmCntLdShdLvlRq 1;
BA_REL_ "GenSigSuprvResp" BU_SG_REL_ VIS2_LS SG_ 2151178240 AFLGPSCstStReq 1;
BA_REL_ "GenSigSuprvResp" BU_SG_REL_ BCM_LS SG_ 2151178240 AFLGPSCstStReq 1;
BA_REL_ "GenSigSuprvResp" BU_SG_REL_ VIS2_LS SG_ 2151178240 AFLCstStReq 1;
BA_REL_ "GenSigSuprvResp" BU_SG_REL_ BCM_LS SG_ 2151178240 AFLCstStReq 1;
BA_REL_ "GenSigSuprvResp" BU_SG_REL_ VIS2_LS SG_ 2151178240 AdpHgBmAsSnCsStRq 1;
BA_REL_ "GenSigSuprvResp" BU_SG_REL_ BCM_LS SG_ 2151178240 AdpHgBmAsSnCsStRq 1;
BA_REL_ "GenSigSuprvResp" BU_SG_REL_ VIS2_LS SG_ 2151178240 AdpHgBmAstCstStRq 1;
BA_REL_ "GenSigSuprvResp" BU_SG_REL_ BCM_LS SG_ 2151178240 AdpHgBmAstCstStRq 1;
BA_REL_ "GenSigSuprvResp" BU_SG_REL_ VIS2_LS SG_ 2151178240 AutHgBmAsSnCsStRq 1;
BA_REL_ "GenSigSuprvResp" BU_SG_REL_ EOCM_F_LS SG_ 2151178240 AutHgBmAsSnCsStRq 1;
BA_REL_ "GenSigSuprvResp" BU_SG_REL_ BCM_LS SG_ 2151178240 AutHgBmAsSnCsStRq 1;
BA_REL_ "GenSigSuprvResp" BU_SG_REL_ VIS2_LS SG_ 2151178240 AutHgBmAstCstStRq 1;
BA_REL_ "GenSigSuprvResp" BU_SG_REL_ EOCM_F_LS SG_ 2151178240 AutHgBmAstCstStRq 1;
BA_REL_ "GenSigSuprvResp" BU_SG_REL_ BCM_LS SG_ 2151178240 AutHgBmAstCstStRq 1;
VAL_ 2151202816 AuxHtrAlwd 1 "true" 0 "false" ;
VAL_ 2151202816 IPSnsrTpCvrTempFltd 1 "true" 0 "false" ;
VAL_ 2151202816 IPSnsrSolrAnglFltd 1 "true" 0 "false" ;
VAL_ 2151202816 IPSnsrRwSolrIntFltd 1 "true" 0 "false" ;
VAL_ 2151202816 ILSSCommErr 1 "Comm Error Detected" 0 "No Comm Error" ;
VAL_ 2151202816 RrWndDfgSwAtv 1 "true" 0 "false" ;
VAL_ 2151202816 RrWndDfgInhRq 1 "Inhibit rear window defog" 0 "Allow rear window defog" ;
VAL_ 2151759872 RrClsRelRq 0 "No Activation" 1 "Release" ;
VAL_ 2151759872 CLRAF_UnandRsv3 1 "true" 0 "false" ;
VAL_ 2151759872 CLRAF_UnandRsv2 1 "true" 0 "false" ;
VAL_ 2151759872 CLRAF_UnandRsv1 1 "true" 0 "false" ;
VAL_ 2151759872 CLRAF_Unl_Lk 4 "Un-double Lock" 3 "Double Lock" 2 "Lock" 1 "Unlock" 0 "No Command" ;
VAL_ 2151759872 CLRAF_RRD 1 "true" 0 "false" ;
VAL_ 2151759872 CLRAF_RLD 1 "true" 0 "false" ;
VAL_ 2151759872 CLRAF_RrCls 1 "true" 0 "false" ;
VAL_ 2151759872 CLRAF_PD 1 "true" 0 "false" ;
VAL_ 2151759872 CLRAF_Hd 1 "true" 0 "false" ;
VAL_ 2151759872 CLRAF_FuelD 1 "true" 0 "false" ;
VAL_ 2151759872 CLRAF_DD 1 "true" 0 "false" ;
VAL_ 2151759872 CLRAF_ActFunc 11 "Exterior Lock Switch" 10 "Lockout Prevention" 9 "Re-locking" 8 "Delayed Locking" 7 "Enhanced Services/Telematics" 6 "Passive Remote Keyfob" 5 "Active Remote Keyfob" 4 "Emergency" 3 "Rr Closure Key Cylinder/Release Sw" 2 "Driver Door Key Cylinder" 1 "Power Door Lock Switch" 0 "Auto Door Lock" ;
VAL_ 2149974016 IntrSnsDisbld 1 "true" 0 "false" ;
VAL_ 2149974016 AlrmStat 4 "Arming Delay" 3 "Alarm Active" 2 "Disarmed" 1 "Armed" 0 "Off" ;
VAL_ 2149974016 AlrmTrggrdBattRcnctd 1 "true" 0 "false" ;
VAL_ 2149974016 AlrmTrgDrvDr 1 "true" 0 "false" ;
VAL_ 2149974016 AlrmTrgGlsBrkSns 1 "true" 0 "false" ;
VAL_ 2149974016 AlrmTrgHd 1 "true" 0 "false" ;
VAL_ 2149974016 AlrmTrgdIO 1 "true" 0 "false" ;
VAL_ 2149974016 AlrmTrgIntMvmntSns 1 "true" 0 "false" ;
VAL_ 2149974016 AlrmTrgNonOffPM 1 "true" 0 "false" ;
VAL_ 2149974016 AlrmTrgPsngDr 1 "true" 0 "false" ;
VAL_ 2149974016 AlrmTrgRrLftDr 1 "true" 0 "false" ;
VAL_ 2149974016 AlrmTrgRrRtDr 1 "true" 0 "false" ;
VAL_ 2149974016 AlrmTrgTltSns 1 "true" 0 "false" ;
VAL_ 2149974016 AlrmTrgTrnk 1 "true" 0 "false" ;
VAL_ 2149974016 SrvAlrmSysIO 1 "true" 0 "false" ;
VAL_ 2149974016 AlrmTrigMidClsr 1 "true" 0 "false" ;
VAL_ 2149974016 AlrmTrigTonn 1 "true" 0 "false" ;
VAL_ 2151907328 StrgWhlUnit1SwStat 15 "Function #F" 14 "Function #E" 13 "Function #D" 12 "Function #C" 11 "Function #B" 10 "Function #A" 9 "Function #9" 8 "Function #8" 7 "Function #7" 6 "Function #6" 5 "Function #5" 4 "Function #4" 3 "Function #3" 2 "Function #2" 1 "Function #1" 0 "No Activation" ;
VAL_ 2151907328 StrgWhlUnit2SwStat 15 "Function #F" 14 "Function #E" 13 "Function #D" 12 "Function #C" 11 "Function #B" 10 "Function #A" 9 "Function #9" 8 "Function #8" 7 "Function #7" 6 "Function #6" 5 "Function #5" 4 "Function #4" 3 "Function #3" 2 "Function #2" 1 "Function #1" 0 "No Activation" ;
VAL_ 2150137856 LMTTCPrsnOffStat 1 "true" 0 "false" ;
VAL_ 2150137856 FldTpMotReq 0 "No Request" 1 "Stop Motion" 2 "Start Motion" 3 "Authentication Failed" ;
VAL_ 2150137856 KeyInWrnIO 1 "true" 0 "false" ;
VAL_ 2150137856 FobPrevLrndIndOn 1 "true" 0 "false" ;
VAL_ 2150137856 RemCtrlFobNumForProgER 0 "No Fob" 1 "Remote Control Fob #1" 2 "Remote Control Fob #2" 3 "Remote Control Fob #3" 4 "Remote Control Fob #4" 5 "Remote Control Fob #5" 6 "Remote Control Fob #6" 7 "Remote Control Fob #7" 8 "Remote Control Fob #8" 9 "Unused" 10 "Unused" 11 "Unused" 12 "Unused" 13 "Unused" 14 "Unused" 15 "Unused" ;
VAL_ 2150137856 FbProgCustActRqd 1 "true" 0 "false" ;
VAL_ 2150137856 Ky_IdDevNotPrIO 1 "true" 0 "false" ;
VAL_ 2150137856 VehSecAtoLrnAtv 1 "true" 0 "false" ;
VAL_ 2150137856 Ky_IdDevPrgmAuthReq 1 "true" 0 "false" ;
VAL_ 2155872256 DrvStyPerfMdCsCrStVal 7 "Performance Mode 7" 6 "Performance Mode 6" 5 "Performance Mode 5" 4 "Performance Mode 4" 3 "Performance Mode 3" 2 "Performance Mode 2" 1 "Performance Mode 1" 0 "No Action" ;
VAL_ 2155872256 DrvStyPerfMdCsStAvl 1 "true" 0 "false" ;
VAL_ 2155872256 VehPitchAngleV 1 "Invalid" 0 "Valid" ;
VAL_ 2155872256 RdWhlAngV 1 "Invalid" 0 "Valid" ;
VAL_ 2155872256 FuelFltChgNwIO 1 "true" 0 "false" ;
VAL_ 2155872256 FlLvlPctV 1 "Invalid" 0 "Valid" ;
VAL_ 2155872256 FlInjRlCtRstOcc 1 "true" 0 "false" ;
VAL_ 2154561536 VehOdoV 1 "Invalid" 0 "Valid" ;
VAL_ 2149908480 BrkPedTrvlAchvd 1 "true" 0 "false" ;
VAL_ 2149908480 BrkPedTrvlAchvdV 1 "Invalid" 0 "Valid" ;
VAL_ 2149908480 BrkPdlModTrvlV 1 "Invalid" 0 "Valid" ;
VAL_ 2149908480 BrkPdlModTrvl 1 "true" 0 "false" ;
VAL_ 2151268352 ClmnLckTT 2 "Flashing Indication" 1 "Continuous Indication" 0 "No Indication" ;
VAL_ 2150424576 ExtHlStrAssCsCrStVal 2 "Standard Hold" 1 "Extended Hold" 0 "No Action" ;
VAL_ 2150424576 ExtHlStrAssCsStAvl 1 "true" 0 "false" ;
VAL_ 2150424576 RrAxlELSDCplLwResV 1 "Invalid" 0 "Valid" ;
VAL_ 2150424576 EngTrqDrRqdExtRngV 1 "Invalid" 0 "Valid" ;
VAL_ 2150424576 EngAirIntBstPrV 1 "Invalid" 0 "Valid" ;
VAL_ 2150424576 TrnsRngInhbtStat 4 "Diagnostic Inhibit Active" 3 "Driveline Not Engaged" 2 "Transmission Range Re-Selection Req" 1 "Transmission Inhibit Active" 0 "No Range Inhibit Active" ;
VAL_ 2150424576 DrvtShftCntrlTrgtGear 10 "Tenth Gear" 9 "Ninth Gear" 8 "Eighth Gear" 7 "Seventh Gear" 6 "Sixth Gear" 5 "Fifth Gear" 4 "Fourth Gear" 3 "Third Gear" 2 "Second Gear" 1 "First Gear" 0 "Not Supported" ;
VAL_ 2150424576 TrnsEngdStateV 1 "Invalid" 0 "Valid" ;
VAL_ 2150424576 ACRfHiSdFldPrsV 1 "Invalid" 0 "Valid" ;
VAL_ 2150424576 ACCompCmnd 1 "On" 0 "Off" ;
VAL_ 2150424576 TrnsEngdState 3 "Operating State Not Reached" 2 "Transmission Engaged in Reverse" 1 "Transmission Engaged in Forward" 0 "Transmission Not Engaged" ;
VAL_ 2155954176 ClmCntlExtDefActIO 1 "true" 0 "false" ;
VAL_ 2155954176 ClntCircPmpRq 1 "On" 0 "Off" ;
VAL_ 2155954176 ClimCtrlAftBlowModActv 1 "true" 0 "false" ;
VAL_ 2155954176 ACHtIdleBstLevReq 3 "Boost Level 3" 2 "Boost Level 2" 1 "Boost Level 1" 0 "No Boost Requested" ;
VAL_ 2155954176 AirCndActIO 1 "true" 0 "false" ;
VAL_ 2149875712 DCCnvStblznErrIO 1 "true" 0 "false" ;
VAL_ 2149875712 BattStOfChrgLowIO 1 "true" 0 "false" ;
VAL_ 2149875712 IntlgntBattSnsFldIO 1 "true" 0 "false" ;
VAL_ 2149875712 BatSOCV 1 "Invalid" 0 "Valid" ;
VAL_ 2149875712 EnrgMgtLdShdRq 4 "Load Shed Level 4" 3 "Load Shed Level 3" 2 "Load Shed Level 2" 1 "Load Shed Level 1" 0 "No Load Shedding" ;
VAL_ 2149875712 SrvBattChrgSysIO 1 "true" 0 "false" ;
VAL_ 2149875712 BattStOfChrgCrtyLow 1 "true" 0 "false" ;
VAL_ 2149875712 BatSaverIO 1 "true" 0 "false" ;
VAL_ 2149875712 BattVltIRq 3 "Battery Voltage Very Low" 2 "Battery Voltage High" 1 "Battery Voltage Low" 0 "Battery Voltage OK" ;
VAL_ 2149875712 BatVltV 1 "Invalid" 0 "Valid" ;
VAL_ 2154053632 TrlrLtngSeqStat 1 "On" 0 "Off" ;
VAL_ 2154053632 CargoLmpActIO 1 "true" 0 "false" ;
VAL_ 2154053632 DispNtSchmAtv 1 "true" 0 "false" ;
VAL_ 2154053632 IntDimNtPnlAtv 1 "true" 0 "false" ;
VAL_ 2151530496 HVBTBDCSRR1_DChSnSRq 3 "Yearly" 2 "Winter" 1 "Summer" 0 "No Action" ;
VAL_ 2151530496 HVBTBDCSRR1_DChSlSRq 8 "Unused and Reserved 4" 7 "Departure Time 2 Invalid" 6 "Unused and Reserved 3" 5 "Departure Time 2" 4 "Unused and Reserved 2" 3 "Departure Time 1 Invalid" 2 "Unused and Reserved 1" 1 "Departure Time 1" 0 "No Action" ;
VAL_ 2151530496 HVBTBDCSRR1_DChDStRq 10 "Sat and Sun Same" 9 "Mon To Fri Same" 8 "All Days Same" 7 "Saturday" 6 "Friday" 5 "Thursday" 4 "Wednsday" 3 "Tuesday" 2 "Monday" 1 "Sunday" 0 "No Action" ;
VAL_ 2151530496 HVBatTmBsChgMdRqRmt1 3 "Rate Based Charge" 2 "Delayed Charge" 1 "Charge Now" 0 "No Action" ;
VAL_ 2151530496 HVChgSyChgLvPfStRmt1 4 "Reduced Current Level 3" 3 "Reduced Current Level 2" 2 "Reduced Current Level 1" 1 "No Reduction" 0 "No Action" ;
VAL_ 2151530496 StTODChrgTmpOvrdRmt1 2 "Active" 1 "Inactive" 0 "No Action" ;
VAL_ 2151530496 PrtyChrgRqRmt1 2 "Active" 1 "Inactive" 0 "No Action" ;
VAL_ 2151530496 OfBrdHVCVhCsChRqRmt1 1 "true" 0 "false" ;
VAL_ 2151530496 TireTrdTmpStat 0 "No Action (unknown)" 1 "Frozen" 2 "Cold" 3 "Warm" 4 "Hot" 5 "Overheated" ;
VAL_ 2151530496 TrPrsMntrTrLdStat 0 "Unknown" 1 "Light Load" 2 "Best Economy Load" 3 "Max Load" ;
VAL_ 2151530496 TrPrsMntrAtLocFld 1 "true" 0 "false" ;
VAL_ 2151530496 TireLocatnWarnEn 1 "true" 0 "false" ;
VAL_ 2151530496 WintTrRecIndOn 1 "true" 0 "false" ;
VAL_ 2151530496 TrPrsMntrFld 1 "true" 0 "false" ;
VAL_ 2151530496 TrRrAxlPresStat 2 "Tire Pressure Imbalance Warning" 1 "Tire Pressure Balanced" 0 "Unknown" ;
VAL_ 2151530496 TrFrntAxlPresStat 2 "Tire Pressure Imbalance Warning" 1 "Tire Pressure Balanced" 0 "Unknown" ;
VAL_ 2151530496 TPMTrLrnMdCmplt 1 "true" 0 "false" ;
VAL_ 2153824256 TeenDrvAccelLimIO 1 "true" 0 "false" ;
VAL_ 2153824256 TeenDrvRsp 0 "No Action" 1 "Teen PIN Verified" 2 "Teen PIN Updated" 3 "Teen PIN Mismatch" 4 "Teen Key Set Complete" 5 "Teen Key Clear Complete" 6 "Key Not Present" 7 "Key Detected as Teen Key" 8 "Key Detected as NOT Teen Key" ;
VAL_ 2153824256 TeenDrvFtrAvl 1 "true" 0 "false" ;
VAL_ 2153824256 TeenDrvPINStrd 1 "true" 0 "false" ;
VAL_ 2153824256 TnDrvGapAdjUnbIO 1 "true" 0 "false" ;
VAL_ 2153824256 TnDrvOvrSpdIO 1 "true" 0 "false" ;
VAL_ 2153824256 TDOvSpdWrnCstStAvl 1 "true" 0 "false" ;
VAL_ 2153824256 TDOWCCSV_CrStat 0 "No Action" 1 "Off" 2 "On" ;
VAL_ 2153824256 TnDrvSpdLmtCstStAvl 1 "true" 0 "false" ;
VAL_ 2153824256 TDSLCCSV_SpLmtStat 0 "No Action" 1 "Off" 2 "On" ;
VAL_ 2153824256 TeenDrvAct 1 "true" 0 "false" ;
VAL_ 2149957632 PrkAstRrObjSnsngRqAct 1 "true" 0 "false" ;
VAL_ 2149957632 PrkAstOprtrDsrdStat 0 "Off" 1 "On" 2 "Tow Bar Attached" ;
VAL_ 2149957632 PrkAstInhbtReq 1 "true" 0 "false" ;
VAL_ 2149957632 ClsnMtgtnInhbtd 1 "true" 0 "false" ;
VAL_ 2151751680 HptcStFldIO 1 "true" 0 "false" ;
VAL_ 2151751680 HptcStVbnStat 0 "Normal Operation" 1 "Unknown" 2 "Failed" ;
VAL_ 2151751680 CrshAlrtDrvrSlctdType 0 "Chime" 1 "Seat" ;
VAL_ 2151751680 CrshAlrtStPrsnt 1 "true" 0 "false" ;
VAL_ 2149990400 ElcTransRngRq 7 "Unused and Reserved" 6 "Manual Range" 5 "Low Range" 4 "Drive" 3 "Neutral" 2 "Reverse" 1 "Park" 0 "No Request" ;
VAL_ 2149990400 TrlrBrkngVDA 1 "VirtualDeviceAvailable" 0 "VirtualDeviceUnavailable" ;
VAL_ 2149990400 MotStBltUnblIO 1 "true" 0 "false" ;
VAL_ 2149990400 MotStBltFldIO 1 "true" 0 "false" ;
VAL_ 2149990400 TransNtrlCntrlMdStat 3 "Exiting Neutral Control" 2 "Neutral Control Active" 1 "Entering Neutral Control" 0 "Neutral Control Not Active" ;
VAL_ 2149990400 TrlrWiringFltIO 1 "true" 0 "false" ;
VAL_ 2149990400 TrlrCnctdIO 1 "true" 0 "false" ;
VAL_ 2149990400 TrlrBrkngGainSetIO 1 "true" 0 "false" ;
VAL_ 2149990400 SrvTrlrBrkngSysIO 1 "true" 0 "false" ;
VAL_ 2149990400 ChkTrlrIO 1 "true" 0 "false" ;
VAL_ 2149990400 ScndryAxleVDA 1 "VirtualDeviceAvailable" 0 "VirtualDeviceUnavailable" ;
VAL_ 2149990400 TrlrHtchSwAtv_ITBC 1 "true" 0 "false" ;
VAL_ 2149990400 AdvHlmpsVDA 1 "VirtualDeviceAvailable" 0 "VirtualDeviceUnavailable" ;
VAL_ 2149990400 ABSIO 1 "true" 0 "false" ;
VAL_ 2149990400 ACCHdwayStngIO 1 "true" 0 "false" ;
VAL_ 2149990400 StpOnBrkToRelPBIndOn 1 "true" 0 "false" ;
VAL_ 2149990400 SADmpVDA 1 "VirtualDeviceAvailable" 0 "VirtualDeviceUnavailable" ;
VAL_ 2149990400 ACCDrvrSeltdSpdIO 1 "true" 0 "false" ;
VAL_ 2149990400 TreInfMonSysRstPrfmd 1 "true" 0 "false" ;
VAL_ 2149990400 DrvThrtlOvrdIO 1 "true" 0 "false" ;
VAL_ 2149990400 SecAxlOperMod 3 "Active All Wheel Drive (High)" 2 "4 Wheel Drive Low Locked" 1 "4 Wheel Drive High Locked" 0 "2 Wheel Drive High" 15 "Neutral" 14 "Unknown" 7 "2 Wheel Drive Low" 6 "Active All Wheel Drive (Low)" 5 "4 Wheel Drive Low Open" 4 "4 Wheel Drive High Open" ;
VAL_ 2155380736 ACCmCltEngd 1 "true" 0 "false" ;
VAL_ 2155380736 StrAsstRdcdLvl3IO 1 "true" 0 "false" ;
VAL_ 2155380736 StrAsstRdcdLvl2IO 1 "true" 0 "false" ;
VAL_ 2155380736 StrngAsstRdcdIO 1 "true" 0 "false" ;
VAL_ 2155380736 PTExPrtclFltrWrn2IO 1 "true" 0 "false" ;
VAL_ 2155380736 EngOilHotIO 1 "true" 0 "false" ;
VAL_ 2155380736 RrLevVDA 1 "VirtualDeviceAvailable" 0 "VirtualDeviceUnavailable" ;
VAL_ 2155380736 EngWtrInFlIO 1 "true" 0 "false" ;
VAL_ 2155380736 AdvFrntLghtSysIndRq 7 "Indication 7" 6 "Indication 6" 5 "Indication 5" 4 "Indication 4" 3 "Indication 3" 2 "Indication 2" 1 "Indication 1" 0 "No Indication" ;
VAL_ 2155380736 PTExPrtclFltrWrnIO 1 "true" 0 "false" ;
VAL_ 2155380736 AirCndOffIO 1 "true" 0 "false" ;
VAL_ 2155380736 HdLtLvlFlrIO 1 "true" 0 "false" ;
VAL_ 2155380736 PwrStrIO 1 "true" 0 "false" ;
VAL_ 2155380736 EngHt_StpEngIO 1 "true" 0 "false" ;
VAL_ 2155380736 CkFlFilrCapIO 1 "true" 0 "false" ;
VAL_ 2155380736 RdcdPwrIO 1 "true" 0 "false" ;
VAL_ 2155380736 EngOilPrsLwIO 1 "true" 0 "false" ;
VAL_ 2155380736 EngOilLvlLwIO 1 "true" 0 "false" ;
VAL_ 2155380736 EngOilChngIO 1 "true" 0 "false" ;
VAL_ 2155380736 EngHotFuelEnrchmntIO 1 "true" 0 "false" ;
VAL_ 2155380736 DslGlwPlgIO 1 "true" 0 "false" ;
VAL_ 2155380736 SrvLevSysIO 1 "true" 0 "false" ;
VAL_ 2155380736 VehOvrLdIndOn 1 "true" 0 "false" ;
VAL_ 2155380736 ARSFlrIO 1 "true" 0 "false" ;
VAL_ 2150498304 EngOilPrsV 1 "Invalid" 0 "Valid" ;
VAL_ 2150498304 EngOilTmpV 1 "Invalid" 0 "Valid" ;
VAL_ 2150498304 TrnOilTmpV 1 "Invalid" 0 "Valid" ;
VAL_ 2150498304 BarPrsAbsV 1 "Invalid" 0 "Valid" ;
VAL_ 2150498304 OAT_PT_EstV 1 "Invalid" 0 "Valid" ;
VAL_ 2150498304 EngCltTmpV 1 "Invalid" 0 "Valid" ;
VAL_ 2150498304 EngIntAirTmpV 1 "Invalid" 0 "Valid" ;
VAL_ 2150498304 OAT_PT_EstM 1 "Use Data" 0 "Don't Use Data" ;
VAL_ 2153955328 ElpsdTimeCntRstOcc 1 "true" 0 "false" ;
VAL_ 2153955328 EngOffTmExtRngV 1 "Invalid" 0 "Valid" ;
VAL_ 2158845952 ODIAC_DspMID 128 "Reserved" 64 "Reserved" 32 "OTIM" 16 "RearDisplayTwo" 8 "RearDisplayOne" 4 "AuxIP" 2 "CenterStack" 1 "IPC" ;
VAL_ 2158845952 ODIAC_DaTy 21 "Bitmap" 20 "DecimalShort" 19 "HoursOfDay" 18 "Character" 17 "Fuel Consumption Inverted" 16 "Fuel Consumption" 15 "Pressure" 14 "Temperature" 13 "Volume" 12 "DistanceShort" 11 "DistanceLong" 10 "BitmapId" 9 "TextId" 8 "Pictogram" 7 "List " 6 "Date" 5 "Time " 4 "Decimal" 3 "EnumerationValue" 2 "Integer" 1 "String" 0 "Speed" ;
VAL_ 2151366656 AxlLckUnavailIndReq 7 "Unused And Reserved 2" 6 "Unused And Reserved 1" 5 "Generic Unavailable" 4 "Not During Hill Decent" 3 "Speed Too High" 2 "Not In 4 WD Low" 1 "Rear Axle Not Locked" 0 "No Action" ;
VAL_ 2151366656 AxlLcksServIO 1 "true" 0 "false" ;
VAL_ 2151366656 RrAxlLckIO 1 "true" 0 "false" ;
VAL_ 2151366656 FrntAxlLckIO 1 "true" 0 "false" ;
VAL_ 2151366656 AxlLcksVDA 1 "Virtual Device Available" 0 "Virtual Device Unavailable" ;
VAL_ 2151366656 PrkBrkSwAtv 1 "true" 0 "false" ;
VAL_ 2149842944 AdptDrvrSeatStng 7 "Performance Mode 7" 6 "Performance Mode 6" 5 "Performance Mode 5" 4 "Performance Mode 4" 3 "Performance Mode 3" 2 "Performance Mode 2" 1 "Performance Mode 1" 0 "No Action" ;
VAL_ 2149842944 VSELatAccV 1 "Invalid" 0 "Valid" ;
VAL_ 2149842944 BrkSysAutBrkFld 1 "true" 0 "false" ;
VAL_ 2149842944 VehStabEnhmntMd 2 "Competitive" 1 "Normal" 0 "Off" ;
VAL_ 2149842944 TCSysOpMd 2 "Off Road" 1 "Normal" 0 "Off" ;
VAL_ 2149842944 IMUProtLonAccV 1 "Invalid" 0 "Valid" ;
VAL_ 2149842944 StrWhAngV 1 "Invalid" 0 "Valid" ;
VAL_ 2149842944 TCSysAtv 1 "true" 0 "false" ;
VAL_ 2149842944 StrWhlAngSenCalStat 2 "Calibrated" 1 "Estimated" 0 "Unknown" ;
VAL_ 2149842944 VehStabEnhmntStat 4 "Not Ready" 3 "Warming Up" 2 "Fault" 1 "Active" 0 "Inactive" ;
VAL_ 2149842944 VSEAct 1 "true" 0 "false" ;
VAL_ 2149842944 TCSysOpStat 2 "Fault" 1 "Active" 0 "Inactive" ;
VAL_ 2149842944 StWhAnVDA 1 "VirtualDeviceAvailable" 0 "VirtualDeviceUnavailable" ;
VAL_ 2154528768 WhlGrndVlctyRtNnDrvnV 1 "Invalid" 0 "Valid" ;
VAL_ 2154528768 WhlGrndVlctyRtDrvnV 1 "Invalid" 0 "Valid" ;
VAL_ 2154528768 WhlGrndVlctyLftNnDrvnV 1 "Invalid" 0 "Valid" ;
VAL_ 2154528768 WhlGrndVlctyLftDrvnV 1 "Invalid" 0 "Valid" ;
VAL_ 2149777408 WRSLNDWhlRotStRst 1 "true" 0 "false" ;
VAL_ 2149777408 WRSLNDWhlDistVal 1 "Invalid" 0 "Valid" ;
VAL_ 2149777408 WRSRNDWhlRotStRst 1 "true" 0 "false" ;
VAL_ 2149777408 WRSRNDWhlDistVal 1 "Invalid" 0 "Valid" ;
VAL_ 2149769216 WRSLDWhlDistVal 1 "Invalid" 0 "Valid" ;
VAL_ 2149769216 WRSLDWhlRotStatRst 1 "true" 0 "false" ;
VAL_ 2149769216 WRSRDWhlRotStatRst 1 "true" 0 "false" ;
VAL_ 2149769216 WRSRDWhlDistVal 1 "Invalid" 0 "Valid" ;
VAL_ 2149752832 SndEnhcmtPerfMdRq 7 "Performance Mode 7" 6 "Performance Mode 6" 5 "Performance Mode 5" 4 "Performance Mode 4" 3 "Performance Mode 3" 2 "Performance Mode 2" 1 "Performance Mode 1" 0 "No Action" ;
VAL_ 2149752832 SndPerfMdCsStAvl 1 "true" 0 "false" ;
VAL_ 2149752832 SndPerfMdCsCrStVal 0 "No Action" 1 "Performance Mode 1" 2 "Performance Mode 2" 3 "Performance Mode 3" 4 "Performance Mode 4" 5 "Performance Mode 5" 6 "Performance Mode 6" 7 "Auto" ;
VAL_ 2149752832 DispPerfMdCsStAvl 1 "true" 0 "false" ;
VAL_ 2149752832 DispPerfMdCsCrStVal 0 "No Action" 1 "Performance Mode 1" 2 "Performance Mode 2" 3 "Performance Mode 3" 4 "Performance Mode 4" 5 "Performance Mode 5" 6 "Performance Mode 6" 7 "Auto" ;
VAL_ 2149752832 HlStrAssActIO 1 "true" 0 "false" ;
VAL_ 2149752832 GNCustSetngAvlbl 1 "true" 0 "false" ;
VAL_ 2149752832 GNCustCrntStngVal 0 "No Action" 1 "Off" 2 "On" ;
VAL_ 2149752832 CPSInfotmntMtReq 0 "No Mute" 1 "Unused and Reserved 1" 2 "Unused and Reserved 2" 3 "Mute" ;
VAL_ 2149752832 ColPrSysStngAvl 1 "true" 0 "false" ;
VAL_ 2149752832 ColPrSysCrntStng 4 "Alert and Brake and Steer" 0 "No Action" 1 "Off" 2 "Alert" 3 "Alert and Brake" ;
VAL_ 2149752832 HillDscntCntlSysStat 4 "Temporarily Inhibited" 3 "Failed" 2 "Active" 1 "Enabled" 0 "Normal" ;
VAL_ 2149752832 EBDFailed 1 "true" 0 "false" ;
VAL_ 2149752832 SusCustStngAvlbl 1 "true" 0 "false" ;
VAL_ 2149752832 SusCustCurrStngVal 7 "Auto" 6 "Performance Mode 6" 5 "Performance Mode 5" 4 "Performance Mode 4" 3 "Performance Mode 3" 0 "No Action" 1 "Performance Mode 1" 2 "Performance Mode 2" ;
VAL_ 2149752832 StrCustStngAvlbl 1 "true" 0 "false" ;
VAL_ 2149752832 StrCustCurrStngVal 2 "Performance Mode 2" 7 "Auto" 6 "Performance Mode 6" 5 "Performance Mode 5" 4 "Performance Mode 4" 3 "Performance Mode 3" 0 "No Action" 1 "Performance Mode 1" ;
VAL_ 2149752832 DrvlnCustStngAvlbl 1 "true" 0 "false" ;
VAL_ 2149752832 DrvlnCustCurrStngVal 7 "Auto" 6 "Performance Mode 6" 5 "Performance Mode 5" 4 "Performance Mode 4" 3 "Performance Mode 3" 0 "No Action" 1 "Performance Mode 1" 2 "Performance Mode 2" ;
VAL_ 2149752832 PowStVDA 1 "VirtualDeviceAvailable" 0 "VirtualDeviceUnavailable" ;
VAL_ 2149752832 RrDrCntVDA 1 "VirtualDeviceAvailable" 0 "VirtualDeviceUnavailable" ;
VAL_ 2149752832 VehHghtStatV 1 "Invalid" 0 "Valid" ;
VAL_ 2149752832 VehHghtStat 4 "Maximum Height" 3 "Kneeling Height" 2 "Aerodynamic Height" 1 "Normal Design Ride Height" 0 "Unknown" ;
VAL_ 2149752832 IntBrkAssPreFilReq 1 "true" 0 "false" ;
VAL_ 2149752832 EPBSysDspMsgReq 7 "Message #7" 6 "Message #6" 5 "Message #5" 4 "Message #4" 3 "Message #3" 2 "Message #2" 1 "Message #1" 0 "Off" ;
VAL_ 2149752832 EPBSysAudWarnReq 2 "Warning #2" 1 "Warning #1" 0 "Off" ;
VAL_ 2149752832 BksOvht 1 "true" 0 "false" ;
VAL_ 2149752832 BrkSysRedBrkTlltlReq 1 "true" 0 "false" ;
VAL_ 2149752832 HalfSysFail 1 "true" 0 "false" ;
VAL_ 2149752832 ElecPrkBrkStat 2 "Fault" 1 "Applied" 0 "Released" ;
VAL_ 2149752832 ABSAtv 1 "true" 0 "false" ;
VAL_ 2149752832 SprTireSt 2 "Spare Detected" 1 "No Spare Detected" 0 "Undetermined" ;
VAL_ 2149752832 BrkSysVDA 1 "VirtualDeviceAvailable" 0 "VirtualDeviceUnavailable" ;
VAL_ 2149752832 PrkBrkVDA 1 "VirtualDeviceAvailable" 0 "VirtualDeviceUnavailable" ;
VAL_ 2152775680 RPDCA_Resrv3Avail 1 "true" 0 "false" ;
VAL_ 2152775680 RPDCA_Resrv2Avail 1 "true" 0 "false" ;
VAL_ 2152775680 RPDCA_Resrv1Avail 1 "true" 0 "false" ;
VAL_ 2152775680 RPDCA_AlrtBrkAvail 1 "true" 0 "false" ;
VAL_ 2152775680 RPDCA_AlrtAvail 1 "true" 0 "false" ;
VAL_ 2152775680 RPDCA_OnAvail 1 "true" 0 "false" ;
VAL_ 2152775680 RPDCA_OfAvail 1 "true" 0 "false" ;
VAL_ 2152775680 DispTrgdVidOn 1 "true" 0 "false" ;
VAL_ 2152775680 a_360DegVidFetrPrsnt 1 "true" 0 "false" ;
VAL_ 2152775680 TrgdVidRecFetrPrsnt 1 "true" 0 "false" ;
VAL_ 2152775680 RrPedDetCstStVal 7 "Reserved3" 6 "Reserved2" 5 "Reserved1" 4 "Alert and Brake" 3 "Alert" 2 "On" 1 "Off" 0 "No Action" ;
VAL_ 2152775680 RrPedDetCstStAvl 1 "true" 0 "false" ;
VAL_ 2152775680 SurdVwLightgCsCurrSetVal 7 "Unused and Reserved 5" 6 "Unused and Reserved 4" 5 "Unused and Reserved 3" 4 "Unused and Reserved 2" 3 "Unused and Reserved 1" 2 "ON" 1 "OFF" 0 "No Action" ;
VAL_ 2152775680 DispSmrtTwVidOn 1 "true" 0 "false" ;
VAL_ 2152775680 DispFrt360CamOn 1 "true" 0 "false" ;
VAL_ 2152775680 SurdVwLightgCsSetAvail 1 "true" 0 "false" ;
VAL_ 2152775680 PudlLmpReqstd 1 "true" 0 "false" ;
VAL_ 2153865216 TeenDrvReq 0 "No Action" 1 "Verify Teen PIN" 2 "Update Teen PIN" 3 "Set Teen Key" 4 "Clear Teen Key" 5 "Check for Teen Key" 6 "Clear Teen Keys and PIN" 7 "Reset Report Card" 8 "Request Report Card Data" ;
VAL_ 2153865216 TnDrvSpdLmtCstStReq 0 "No Action" 1 "Off" 2 "On" ;
VAL_ 2153865216 TDOWCSR_StatReq 0 "No Action" 1 "Off" 2 "On" ;
VAL_ 2153865216 TDOWCSR_IncSwAct 1 "true" 0 "false" ;
VAL_ 2153865216 TDOWCSR_DecSwAct 1 "true" 0 "false" ;
VAL_ 2151178240 AFLGPSCstStReq 0 "No Action" 1 "Corner And Curve Lighting Only" 2 "Intelligent Light Distribution" 3 "GPS Assistance" 4 "Reserved1" 5 "Reserved2" 6 "Reserved3" 7 "Off" ;
VAL_ 2151178240 AFLCstStReq 0 "No Action" 1 "Corner And Curve Lighting Only" 2 "Intelligent Light Distribution" 3 "Reserved1" 4 "Reserved2" 5 "Reserved3" 6 "Reserved4" 7 "Off" ;
VAL_ 2151178240 LtRtHnTrCstStReq 0 "No Action" 1 "Left Hand Traffic" 2 "Right Hand Traffic" ;
VAL_ 2151178240 AdpHgBmAsSnCsStRq 0 "No Action" 1 "Off" 2 "Normal Sensitivity" 3 "Reduced Sensitivity" 4 "Reserved1" 5 "Reserved2" 6 "Reserved3" 7 "Reserved4" ;
VAL_ 2151178240 AdpHgBmAstCstStRq 0 "No Action" 1 "Off" 2 "On" 3 "Reserved1" 4 "Reserved2" 5 "Reserved3" 6 "Reserved4" 7 "Reserved5" ;
VAL_ 2151178240 LtRtHnTrGPSCstStRq 0 "No Action" 1 "Left Hand Traffic" 2 "Right Hand Traffic" 3 "Automatic" 4 "Reserved1" 5 "Reserved2" 6 "Reserved3" 7 "Reserved4" ;
VAL_ 2151178240 AutHgBmAsSnCsStRq 0 "No Action" 1 "Off" 2 "On Normal Sensitivity" 3 "On Reduced Sensitivity" 4 "Reserved1" 5 "Reserved2" 6 "Reserved3" 7 "Reserved4" ;
VAL_ 2151178240 AutHgBmAstCstStRq 0 "No Action" 1 "Off" 2 "On" 3 "Reserved1" 4 "Reserved2" 5 "Reserved3" 6 "Reserved4" 7 "Reserved5" ;
VAL_ 2151882752 PTOTpStpSpdCsStReq 0 "No Action" 1 "5 rpm" 2 "10 rpm" 3 "25 rpm" 4 "50 rpm" 5 "100 rpm" 6 "250 rpm" 7 "500 rpm" ;
VAL_ 2151882752 PTOStdbySpdCsStReq 0 "No Action" 1 "900 rpm" 2 "1000 rpm" 3 "1100 rpm" 4 "1200 rpm" 5 "1300 rpm" 6 "1400 rpm" 7 "1500 rpm" ;
VAL_ 2151882752 PTOEngRnTmrCsStRq 0 "No Action" 1 "10 min" 2 "30 min" 3 "90 min" 4 "120 min" 5 "150 min" 6 "180 min" 7 "210 min" 8 "240 min" 9 "270 min" 10 "300 min" 11 "330 min" 12 "360 min" 13 "390 min" 14 "420 min" 15 "450 min" ;
VAL_ 2151882752 PTOSet2SpdCsStReq 0 "No Action" 1 "1900 rpm" 2 "2000 rpm" 3 "2100 rpm" 4 "2200 rpm" 5 "2300 rpm" 6 "2400 rpm" 7 "2500 rpm" 8 "2600 rpm" 9 "2700 rpm" 10 "2800 rpm" 11 "2900 rpm" 12 "3000 rpm" 13 "3100 rpm" 14 "3200 rpm" 15 "3300 rpm" ;
VAL_ 2151882752 PTOSet1SpdCsStReq 0 "No Action" 1 "1100 rpm" 2 "1200 rpm" 3 "1300 rpm" 4 "1400 rpm" 5 "1500 rpm" 6 "1600 rpm" 7 "1700 rpm" 8 "1800 rpm" 9 "1900 rpm" 10 "2000 rpm" 11 "2100 rpm" 12 "2200 rpm" 13 "2300 rpm" 14 "2400 rpm" 15 "2500 rpm" ;
SIG_GROUP_ 2151759872 CntrlLckRqwExtActFun 1 : CLRAF_UnandRsv3 CLRAF_UnandRsv2 CLRAF_UnandRsv1 CLRAF_Unl_Lk CLRAF_RRD CLRAF_RLD CLRAF_RrCls CLRAF_PD CLRAF_Hd CLRAF_FuelD CLRAF_DD CLRAF_ActFunc;
SIG_GROUP_ 2149908480 BrkPedInitTrvlAchvdStat 1 : BrkPedTrvlAchvd BrkPedTrvlAchvdV;
SIG_GROUP_ 2151530496 HVBatTmBsDlChStRqRmt1 1 : HVBTBDCSRR1_DChMHSRq HVBTBDCSRR1_DChSnSRq HVBTBDCSRR1_DChSlSRq HVBTBDCSRR1_DChDStRq HVBTBDCSRR1_DChHStRq;
SIG_GROUP_ 2153824256 TDOvSpdWrnCstCrStVl 1 : TDOWCCSV_CrStVl TDOWCCSV_CrStat;
SIG_GROUP_ 2153824256 TnDrvSpdLmtCstCrStVl 1 : TDSLCCSV_SpLmtStat TDSLCCSV_SpLmDisVl;
SIG_GROUP_ 2158845952 ODIActn_CntrStck 1 : ODIAC_FUCID ODIAC_DspMID ODIAC_DaTy ODIAC_ActnVal ODIAC_ActnID;
SIG_GROUP_ 2149777408 WhlRotStatLftNDrvn 1 : WRSLNDWhlDisTpRC WRSLNDWhlRotStRst WRSLNDWhlDistVal WRSLNDWhlDistTstm WRSLNDWhlDistPCntr WRSLNDSeqNum;
SIG_GROUP_ 2149777408 WhlRotStatRghtNDrvn 1 : WRSRNDWhlDisTpRC WRSRNDWhlRotStRst WRSRNDWhlDistVal WRSRNDWhlDistTstm WRSRNDWhlDistPCntr WRSRNDSeqNum;
SIG_GROUP_ 2149769216 WhlRotatStatLftDrvn 1 : WRSLDWhlDisTpRC WRSLDSeqNum WRSLDWhlDistVal WRSLDWhlRotStatRst WRSLDWhlDistTmstm WRSLDWhlDistPlsCntr;
SIG_GROUP_ 2149769216 WhlRotatStatRtDrvn 1 : WRSRDWhlDisTpRC WRSRDSeqNum WRSRDWhlRotStatRst WRSRDWhlDistVal WRSRDWhlDistTmstm WRSRDWhlDistPlsCntr;
SIG_GROUP_ 2152775680 RrPedDetCstAvail 1 : RPDCA_Resrv3Avail RPDCA_Resrv2Avail RPDCA_Resrv1Avail RPDCA_AlrtBrkAvail RPDCA_AlrtAvail RPDCA_OnAvail RPDCA_OfAvail;
SIG_GROUP_ 2153865216 TDOvSpdWrnCstStReq 1 : TDOWCSR_StatReq TDOWCSR_IncSwAct TDOWCSR_DecSwAct;
